VERSION ""

NS_ :

BS_:
BU_: Receiver ChassisBus VehicleBus PartyBus apb ui app aps bms gtwu odin cc cmp cp das dif dir di epas3p epas3s epbl epbr esp fc gtw hvp ibst ocs1p park pcs pmf pmr pm ptc radc rcm2 rcm sccm scm scs tas tpms umc vcfront vcleft vcright vcsec GTW

BO_ 800 ID320BMS_alertMatrix: 8 VehicleBus
   SG_ BMS_matrixIndex M : 0|4@1+ (1,0) [0|15] "" Receiver
   SG_ BMS_a001_Pack_Config_Mismatch m0 : 4|1@1+ (1,0) [0|1] "" Receiver
   SG_ BMS_a007_SW_Slowed_Chg_Batt_Cold m0 : 10|1@1+ (1,0) [0|1] "" Receiver
   SG_ BMS_a016_Pack_Module_Id_Mismatch m0 : 19|1@1+ (1,0) [0|1] "" Receiver
   SG_ BMS_a017_SW_Brick_OV m0 : 20|1@1+ (1,0) [0|1] "" Receiver
   SG_ BMS_a018_SW_Brick_UV m0 : 21|1@1+ (1,0) [0|1] "" Receiver
   SG_ BMS_a019_SW_Module_OT m0 : 22|1@1+ (1,0) [0|1] "" Receiver
   SG_ BMS_a021_SW_Dr_Limits_Regulation m0 : 24|1@1+ (1,0) [0|1] "" Receiver
   SG_ BMS_a022_SW_Over_Current m0 : 25|1@1+ (1,0) [0|1] "" Receiver
   SG_ BMS_a023_SW_Stack_OV m0 : 26|1@1+ (1,0) [0|1] "" Receiver
   SG_ BMS_a024_SW_Islanded_Brick m0 : 27|1@1+ (1,0) [0|1] "" Receiver
   SG_ BMS_a025_SW_PwrBalance_Anomaly m0 : 28|1@1+ (1,0) [0|1] "" Receiver
   SG_ BMS_a026_SW_HFCurrent_Anomaly m0 : 29|1@1+ (1,0) [0|1] "" Receiver
   SG_ BMS_a034_SW_Passive_Isolation m0 : 37|1@1+ (1,0) [0|1] "" Receiver
   SG_ BMS_a035_SW_Isolation m0 : 38|1@1+ (1,0) [0|1] "" Receiver
   SG_ BMS_a036_SW_HvpHvilFault m0 : 39|1@1+ (1,0) [0|1] "" Receiver
   SG_ BMS_a037_SW_Flood_Port_Open m0 : 40|1@1+ (1,0) [0|1] "" Receiver
   SG_ BMS_a039_SW_DC_Link_Over_Voltage m0 : 42|1@1+ (1,0) [0|1] "" Receiver
   SG_ BMS_a040_SW_Watch_Dog_HW_Trigger m0 : 43|1@1+ (1,0) [0|1] "" Receiver
   SG_ BMS_a041_SW_Destructive_Reset_So m0 : 44|1@1+ (1,0) [0|1] "" Receiver
   SG_ BMS_a042_SW_MPU_Error m0 : 45|1@1+ (1,0) [0|1] "" Receiver
   SG_ BMS_a043_SW_Watch_Dog_Reset m0 : 46|1@1+ (1,0) [0|1] "" Receiver
   SG_ BMS_a044_SW_Assertion m0 : 47|1@1+ (1,0) [0|1] "" Receiver
   SG_ BMS_a045_SW_Exception m0 : 48|1@1+ (1,0) [0|1] "" Receiver
   SG_ BMS_a046_SW_Task_Stack_Usage m0 : 49|1@1+ (1,0) [0|1] "" Receiver
   SG_ BMS_a047_SW_Task_Stack_Overflow m0 : 50|1@1+ (1,0) [0|1] "" Receiver
   SG_ BMS_a048_SW_Log_Upload_Request m0 : 51|1@1+ (1,0) [0|1] "" Receiver
   SG_ BMS_a050_SW_Brick_Voltage_MIA m0 : 53|1@1+ (1,0) [0|1] "" Receiver
   SG_ BMS_a051_SW_HVC_Vref_Bad m0 : 54|1@1+ (1,0) [0|1] "" Receiver
   SG_ BMS_a052_SW_PCS_MIA m0 : 55|1@1+ (1,0) [0|1] "" Receiver
   SG_ BMS_a054_SW_Ver_Supply_Fault m0 : 57|1@1+ (1,0) [0|1] "" Receiver
   SG_ BMS_a055_SW_HvChain_Model_Fault m0 : 58|1@1+ (1,0) [0|1] "" Receiver
   SG_ BMS_a056_SW_Standby_Supply_Fault m0 : 59|1@1+ (1,0) [0|1] "" Receiver
   SG_ BMS_a057_SW_Bandolier_Model_Warn m0 : 60|1@1+ (1,0) [0|1] "" Receiver
   SG_ BMS_a058_SW_Bandolier_Model_Rese m0 : 61|1@1+ (1,0) [0|1] "" Receiver
   SG_ BMS_a059_SW_Pack_Voltage_Sensing m0 : 62|1@1+ (1,0) [0|1] "" Receiver
   SG_ BMS_a060_SW_Leakage_Test_Failure m0 : 63|1@1+ (1,0) [0|1] "" Receiver
   SG_ BMS_a061_SW_BrickV_Change m1 : 4|1@1+ (1,0) [0|1] "" Receiver
   SG_ BMS_a062_SW_BrickV_Imbalance m1 : 5|1@1+ (1,0) [0|1] "" Receiver
   SG_ BMS_a063_SW_ChargePort_Fault m1 : 6|1@1+ (1,0) [0|1] "" Receiver
   SG_ BMS_a064_SW_SOC_Imbalance m1 : 7|1@1+ (1,0) [0|1] "" Receiver
   SG_ BMS_a065_SW_CAC_Imbalance m1 : 8|1@1+ (1,0) [0|1] "" Receiver
   SG_ BMS_a069_SW_Low_Power m1 : 12|1@1+ (1,0) [0|1] "" Receiver
   SG_ BMS_a071_SW_SM_TransCon_Not_Met m1 : 14|1@1+ (1,0) [0|1] "" Receiver
   SG_ BMS_a075_SW_Chg_Disable_Failure m1 : 18|1@1+ (1,0) [0|1] "" Receiver
   SG_ BMS_a076_SW_Dch_While_Charging m1 : 19|1@1+ (1,0) [0|1] "" Receiver
   SG_ BMS_a077_SW_Charger_Regulation m1 : 20|1@1+ (1,0) [0|1] "" Receiver
   SG_ BMS_a080_SW_Pack_Ctr_Impedance m1 : 23|1@1+ (1,0) [0|1] "" Receiver
   SG_ BMS_a081_SW_Ctr_Close_Blocked m1 : 24|1@1+ (1,0) [0|1] "" Receiver
   SG_ BMS_a082_SW_Ctr_Force_Open m1 : 25|1@1+ (1,0) [0|1] "" Receiver
   SG_ BMS_a083_SW_Ctr_Close_Failure m1 : 26|1@1+ (1,0) [0|1] "" Receiver
   SG_ BMS_a084_SW_Sleep_Wake_Aborted m1 : 27|1@1+ (1,0) [0|1] "" Receiver
   SG_ BMS_a087_SW_Feim_Test_Blocked m1 : 30|1@1+ (1,0) [0|1] "" Receiver
   SG_ BMS_a088_SW_VcFront_MIA_InDrive m1 : 31|1@1+ (1,0) [0|1] "" Receiver
   SG_ BMS_a089_SW_VcFront_MIA m1 : 32|1@1+ (1,0) [0|1] "" Receiver
   SG_ BMS_a090_SW_Gateway_MIA m1 : 33|1@1+ (1,0) [0|1] "" Receiver
   SG_ BMS_a091_SW_ChargePort_MIA m1 : 34|1@1+ (1,0) [0|1] "" Receiver
   SG_ BMS_a092_SW_ChargePort_Mia_On_Hv m1 : 35|1@1+ (1,0) [0|1] "" Receiver
   SG_ BMS_a094_SW_Drive_Inverter_MIA m1 : 37|1@1+ (1,0) [0|1] "" Receiver
   SG_ BMS_a098_SW_BMB_Data_Integrity_L m1 : 41|1@1+ (1,0) [0|1] "" Receiver
   SG_ BMS_a099_SW_BMB_Communication m1 : 42|1@1+ (1,0) [0|1] "" Receiver
   SG_ BMS_a105_SW_One_Module_Tsense m1 : 48|1@1+ (1,0) [0|1] "" Receiver
   SG_ BMS_a106_SW_All_Module_Tsense m1 : 49|1@1+ (1,0) [0|1] "" Receiver
   SG_ BMS_a107_SW_Stack_Voltage_MIA m1 : 50|1@1+ (1,0) [0|1] "" Receiver
   SG_ BMS_a121_SW_NVRAM_Config_Error m2 : 4|1@1+ (1,0) [0|1] "" Receiver
   SG_ BMS_a122_SW_BMS_Therm_Irrational m2 : 5|1@1+ (1,0) [0|1] "" Receiver
   SG_ BMS_a123_SW_Internal_Isolation m2 : 6|1@1+ (1,0) [0|1] "" Receiver
   SG_ BMS_a126_SW_Thermistor_Failure m2 : 9|1@1+ (1,0) [0|1] "" Receiver
   SG_ BMS_a127_SW_shunt_SNA m2 : 10|1@1+ (1,0) [0|1] "" Receiver
   SG_ BMS_a128_SW_shunt_MIA m2 : 11|1@1+ (1,0) [0|1] "" Receiver
   SG_ BMS_a129_SW_VSH_Failure m2 : 12|1@1+ (1,0) [0|1] "" Receiver
   SG_ BMS_a130_IO_CAN_Error m2 : 13|1@1+ (1,0) [0|1] "" Receiver
   SG_ BMS_a131_Bleed_FET_Failure m2 : 14|1@1+ (1,0) [0|1] "" Receiver
   SG_ BMS_a132_HW_BMB_OTP_Uncorrctbl m2 : 15|1@1+ (1,0) [0|1] "" Receiver
   SG_ BMS_a134_SW_Delayed_Ctr_Off m2 : 17|1@1+ (1,0) [0|1] "" Receiver
   SG_ BMS_a135_HW_BMB_Diagnostics_Fail m2 : 18|1@1+ (1,0) [0|1] "" Receiver
   SG_ BMS_a136_SW_Module_OT_Warning m2 : 19|1@1+ (1,0) [0|1] "" Receiver
   SG_ BMS_a137_SW_Brick_UV_Warning m2 : 20|1@1+ (1,0) [0|1] "" Receiver
   SG_ BMS_a138_SW_Brick_OV_Warning m2 : 21|1@1+ (1,0) [0|1] "" Receiver
   SG_ BMS_a139_SW_DC_Link_V_Irrational m2 : 22|1@1+ (1,0) [0|1] "" Receiver
   SG_ BMS_a141_SW_BMB_Status_Warning m2 : 24|1@1+ (1,0) [0|1] "" Receiver
   SG_ BMS_a143_SW_CAC_Change m2 : 26|1@1+ (1,0) [0|1] "" Receiver
   SG_ BMS_a144_Hvp_Config_Mismatch m2 : 27|1@1+ (1,0) [0|1] "" Receiver
   SG_ BMS_a145_SW_SOC_Change m2 : 28|1@1+ (1,0) [0|1] "" Receiver
   SG_ BMS_a146_SW_Brick_Overdischarged m2 : 29|1@1+ (1,0) [0|1] "" Receiver
   SG_ BMS_a149_SW_Missing_Config_Block m2 : 32|1@1+ (1,0) [0|1] "" Receiver
   SG_ BMS_a151_SW_external_isolation m2 : 34|1@1+ (1,0) [0|1] "" Receiver
   SG_ BMS_a155_SW_Weak_short_impedence m2 : 38|1@1+ (1,0) [0|1] "" Receiver
   SG_ BMS_a156_SW_BMB_Vref_bad m2 : 39|1@1+ (1,0) [0|1] "" Receiver
   SG_ BMS_a158_SW_HVP_HVI_Comms m2 : 41|1@1+ (1,0) [0|1] "" Receiver
   SG_ BMS_a159_SW_HVP_ECU_Error m2 : 42|1@1+ (1,0) [0|1] "" Receiver
   SG_ BMS_a160_SW_FC_Ctr_Clean_Failed m2 : 43|1@1+ (1,0) [0|1] "" Receiver
   SG_ BMS_a161_SW_DI_Open_Request m2 : 44|1@1+ (1,0) [0|1] "" Receiver
   SG_ BMS_a162_SW_No_Power_For_Support m2 : 45|1@1+ (1,0) [0|1] "" Receiver
   SG_ BMS_a163_SW_Contactor_Mismatch m2 : 46|1@1+ (1,0) [0|1] "" Receiver
   SG_ BMS_a164_SW_Uncontrolled_Regen m2 : 47|1@1+ (1,0) [0|1] "" Receiver
   SG_ BMS_a165_SW_Pack_Partial_Weld m2 : 48|1@1+ (1,0) [0|1] "" Receiver
   SG_ BMS_a166_SW_Pack_Full_Weld m2 : 49|1@1+ (1,0) [0|1] "" Receiver
   SG_ BMS_a167_SW_FC_Partial_Weld m2 : 50|1@1+ (1,0) [0|1] "" Receiver
   SG_ BMS_a168_SW_FC_Full_Weld m2 : 51|1@1+ (1,0) [0|1] "" Receiver
   SG_ BMS_a169_SW_FC_Pack_Weld m2 : 52|1@1+ (1,0) [0|1] "" Receiver
   SG_ BMS_a170_SW_Limp_Mode m2 : 53|1@1+ (1,0) [0|1] "" Receiver
   SG_ BMS_a171_SW_Stack_Voltage_Sense m2 : 54|1@1+ (1,0) [0|1] "" Receiver
   SG_ BMS_a174_SW_Charge_Failure m2 : 57|1@1+ (1,0) [0|1] "" Receiver
   SG_ BMS_a176_SW_GracefulPowerOff m2 : 59|1@1+ (1,0) [0|1] "" Receiver
   SG_ BMS_a178_SW_Uncontrolled_Regen_P m2 : 61|1@1+ (1,0) [0|1] "" Receiver
   SG_ BMS_a179_SW_Hvp_12V_Fault m2 : 62|1@1+ (1,0) [0|1] "" Receiver
   SG_ BMS_a180_SW_ECU_reset_blocked m2 : 63|1@1+ (1,0) [0|1] "" Receiver

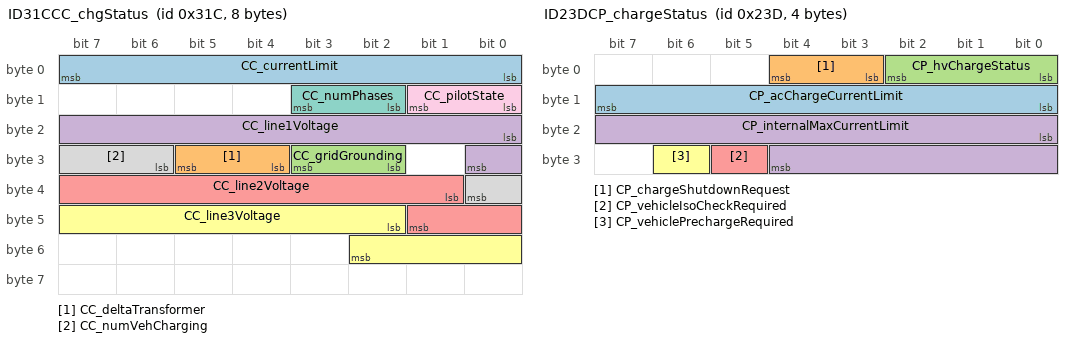
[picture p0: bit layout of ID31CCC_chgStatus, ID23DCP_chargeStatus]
BO_ 796 ID31CCC_chgStatus: 8 VehicleBus
   SG_ CC_currentLimit : 0|8@1+ (0.5,0) [0|127.5] "A" Receiver
   SG_ CC_deltaTransformer : 28|2@1+ (1,0) [0|3] "" Receiver
   SG_ CC_gridGrounding : 26|2@1+ (1,0) [0|2] "" Receiver
   SG_ CC_line1Voltage : 16|9@1+ (1,0) [0|511] "V" Receiver
   SG_ CC_line2Voltage : 33|9@1+ (1,0) [0|511] "V" Receiver
   SG_ CC_line3Voltage : 42|9@1+ (1,0) [0|511] "V" Receiver
   SG_ CC_numPhases : 10|2@1+ (1,0) [0|3] "" Receiver
   SG_ CC_numVehCharging : 30|3@1+ (1,0) [0|7] "" Receiver
   SG_ CC_pilotState : 8|2@1+ (1,0) [0|3] "" Receiver

BO_ 797 ID31DCC_chgStatus2: 8 VehicleBus
   SG_ CC_chgStatus2Index M : 0|8@1+ (1,0) [0|0] "" Receiver
   SG_ CC_buttonState m0 : 8|1@1+ (1,0) [0|1] "" Receiver

BO_ 812 ID32CCC_logData: 8 VehicleBus
   SG_ CC_logIndex M : 0|8@1+ (1,0) [0|13] "" Receiver
   SG_ CC_activeConnectorID m0 : 8|8@1+ (1,0) [0|255] "" Receiver
   SG_ CC_conn1Current m1 : 8|8@1+ (0.5,0) [0|127.5] "A" Receiver
   SG_ CC_conn2Current m2 : 8|8@1+ (0.5,0) [0|127.5] "A" Receiver
   SG_ CC_conn3Current m3 : 8|8@1+ (0.5,0) [0|127.5] "A" Receiver
   SG_ CC_conn4Current m4 : 8|8@1+ (0.5,0) [0|127.5] "A" Receiver
   SG_ CC_contactor1Closed m0 : 40|2@1+ (1,0) [0|3] "" Receiver
   SG_ CC_contactor2Closed m0 : 42|2@1+ (1,0) [0|3] "" Receiver
   SG_ CC_lifetimeAlertCount m12 : 8|28@1+ (1,0) [0|2.68435e+08] "" Receiver
   SG_ CC_lifetimeAvgStartupTemp m13 : 36|28@1- (0.1,0) [-1.34218e+07|1.34218e+07] "C" Receiver
   SG_ CC_lifetimeCtrCycles m11 : 8|28@1+ (1,0) [0|2.68435e+08] "" Receiver
   SG_ CC_lifetimeCtrCyclesLoaded m11 : 36|28@1+ (1,0) [0|2.68435e+08] "" Receiver
   SG_ CC_lifetimeThermalFoldbacks m12 : 36|28@1+ (1,0) [0|2.68435e+08] "" Receiver
   SG_ CC_lifetimei2t m10 : 32|32@1+ (0.1,0) [0|4.29497e+08] "A2h" Receiver
   SG_ CC_temperature1 m0 : 16|8@1- (1,88) [-40|215] "C" Receiver
   SG_ CC_temperature2 m0 : 24|8@1- (1,88) [-40|215] "C" Receiver
   SG_ CC_temperature3 m0 : 32|8@1- (1,88) [-40|215] "C" Receiver
   SG_ CC_temperature4 m0 : 44|8@1- (1,88) [-40|215] "C" Receiver

BO_ 573 ID23DCP_chargeStatus: 4 VehicleBus
   SG_ CP_acChargeCurrentLimit : 8|8@1+ (0.5,0) [0|127.5] "A" Receiver
   SG_ CP_chargeShutdownRequest : 3|2@1+ (1,0) [0|2] "" Receiver
   SG_ CP_hvChargeStatus : 0|3@1+ (1,0) [0|6] "" Receiver
   SG_ CP_internalMaxCurrentLimit : 16|13@1+ (0.146502,0) [0|1200] "A" Receiver
   SG_ CP_vehicleIsoCheckRequired : 29|1@1+ (1,0) [0|1] "" Receiver
   SG_ CP_vehiclePrechargeRequired : 30|1@1+ (1,0) [0|1] "" Receiver

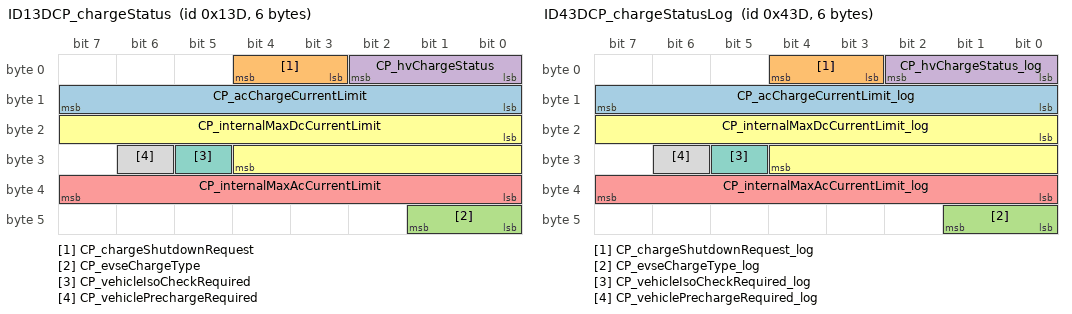
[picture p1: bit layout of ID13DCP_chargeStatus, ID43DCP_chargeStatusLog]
BO_ 317 ID13DCP_chargeStatus: 6 VehicleBus
   SG_ CP_acChargeCurrentLimit : 8|8@1+ (0.5,0) [0|127.5] "A" Receiver
   SG_ CP_chargeShutdownRequest : 3|2@1+ (1,0) [0|2] "" Receiver
   SG_ CP_evseChargeType : 40|2@1+ (1,0) [0|2] "" Receiver
   SG_ CP_hvChargeStatus : 0|3@1+ (1,0) [0|6] "" Receiver
   SG_ CP_internalMaxAcCurrentLimit : 32|8@1+ (0.5,0) [0|127.5] "A" Receiver
   SG_ CP_internalMaxDcCurrentLimit : 16|13@1+ (0.146502,0) [0|1200] "A" Receiver
   SG_ CP_vehicleIsoCheckRequired : 29|1@1+ (1,0) [0|1] "" Receiver
   SG_ CP_vehiclePrechargeRequired : 30|1@1+ (1,0) [0|1] "" Receiver

BO_ 1085 ID43DCP_chargeStatusLog: 6 VehicleBus
   SG_ CP_acChargeCurrentLimit_log : 8|8@1+ (0.5,0) [0|127.5] "A" Receiver
   SG_ CP_chargeShutdownRequest_log : 3|2@1+ (1,0) [0|2] "" Receiver
   SG_ CP_evseChargeType_log : 40|2@1+ (1,0) [0|2] "" Receiver
   SG_ CP_hvChargeStatus_log : 0|3@1+ (1,0) [0|6] "" Receiver
   SG_ CP_internalMaxAcCurrentLimit_log : 32|8@1+ (0.5,0) [0|127.5] "A" Receiver
   SG_ CP_internalMaxDcCurrentLimit_log : 16|13@1+ (0.146502,0) [0|1200] "A" Receiver
   SG_ CP_vehicleIsoCheckRequired_log : 29|1@1+ (1,0) [0|1] "" Receiver
   SG_ CP_vehiclePrechargeRequired_log : 30|1@1+ (1,0) [0|1] "" Receiver

BO_ 541 ID21DCP_evseStatus: 8 VehicleBus
   SG_ CP_acChargeState : 53|3@1+ (1,0) [0|6] "" Receiver
   SG_ CP_acNumRetries : 40|2@1+ (1,0) [0|3] "" Receiver
   SG_ CP_cableCurrentLimit : 24|7@1+ (1,0) [0|127] "A" Receiver
   SG_ CP_cableType : 16|3@1+ (1,0) [0|4] "" Receiver
   SG_ CP_digitalCommsAttempts : 32|2@1+ (1,0) [0|3] "" Receiver
   SG_ CP_digitalCommsEstablished : 37|1@1+ (1,0) [0|1] "" Receiver
   SG_ CP_evseAccept : 0|1@1+ (1,0) [0|1] "" Receiver
   SG_ CP_evseChargeType_UI : 38|2@1+ (1,0) [0|2] "" Receiver
   SG_ CP_evseRequest : 1|1@1+ (1,0) [0|1] "" Receiver
   SG_ CP_gbState : 42|4@1+ (1,0) [0|15] "" Receiver
   SG_ CP_gbdcChargeAttempts : 51|2@1+ (1,0) [0|3] "" Receiver
   SG_ CP_gbdcFailureReason : 49|2@1+ (1,0) [0|3] "" Receiver
   SG_ CP_gbdcStopChargeReason : 46|3@1+ (1,0) [0|7] "" Receiver
   SG_ CP_iecComboState : 60|4@1+ (1,0) [0|12] "" Receiver
   SG_ CP_pilot : 4|3@1+ (1,0) [0|7] "" Receiver
   SG_ CP_pilotCurrent : 8|8@1+ (0.5,0) [0|127.5] "A" Receiver
   SG_ CP_proximity : 2|2@1+ (1,0) [0|3] "" Receiver
   SG_ CP_teslaDcState : 56|4@1+ (1,0) [0|10] "" Receiver
   SG_ CP_teslaSwcanState : 34|3@1+ (1,0) [0|6] "" Receiver

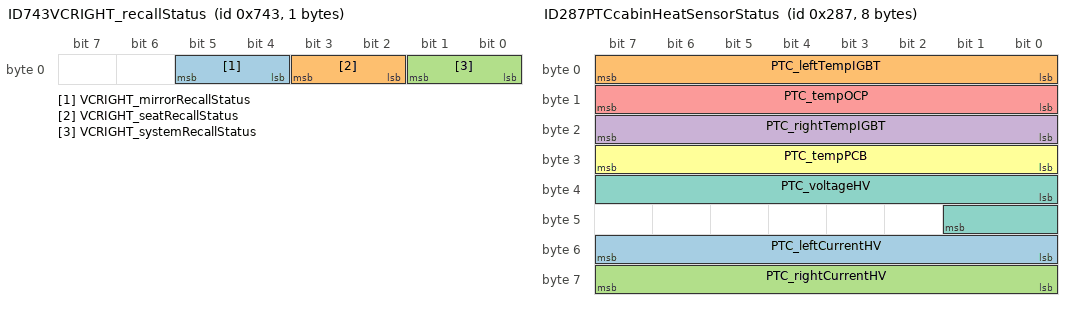
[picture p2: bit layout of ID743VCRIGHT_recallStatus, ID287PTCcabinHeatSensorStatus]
BO_ 1859 ID743VCRIGHT_recallStatus: 1 VehicleBus
   SG_ VCRIGHT_mirrorRecallStatus : 4|2@1+ (1,0) [0|3] "" Receiver
   SG_ VCRIGHT_seatRecallStatus : 2|2@1+ (1,0) [0|3] "" Receiver
   SG_ VCRIGHT_systemRecallStatus : 0|2@1+ (1,0) [0|3] "" Receiver

BO_ 1885 ID75DCP_sensorData: 8 VehicleBus
   SG_ CP_sensorDataSelect M : 0|4@1+ (1,0) [0|12] "" Receiver
   SG_ CP_UHF_chipState m6 : 4|3@1+ (1,0) [0|7] "" Receiver
   SG_ CP_UHF_fifoData m6 : 32|8@1+ (1,0) [0|255] "" Receiver
   SG_ CP_UHF_rssi m6 : 8|8@1+ (1,0) [0|255] "" Receiver
   SG_ CP_UHF_rxNumBytes m6 : 24|8@1+ (1,0) [0|255] "" Receiver
   SG_ CP_UHF_rxOverflow m6 : 16|1@1+ (1,0) [0|1] "" Receiver
   SG_ CP_UHF_selfTestRssi m6 : 40|8@1+ (1,0) [0|255] "" Receiver
   SG_ CP_backCover2Counts m5 : 32|16@1+ (0.0015259,0) [0|100] "%" Receiver
   SG_ CP_backCoverCounts m5 : 16|16@1+ (0.0015259,0) [0|100] "%" Receiver
   SG_ CP_boardTemperature m1 : 32|8@1+ (1.29412,-50) [-50|280] "C" Receiver
   SG_ CP_doorCountsDebounced m0 : 24|16@1+ (0.0015259,0) [0|100] "%" Receiver
   SG_ CP_doorCountsFiltered m0 : 8|16@1+ (0.0015259,0) [0|100] "%" Receiver
   SG_ CP_doorI m2 : 16|12@1+ (0.0025,0) [0|10.2375] "A" Receiver
   SG_ CP_doorLastRequestMaxI m2 : 28|12@1+ (0.0025,0) [0|10.2375] "A" Receiver
   SG_ CP_doorPot m2 : 4|12@1+ (0.025,0) [0|100] "%" Receiver
   SG_ CP_faultLineV m5 : 4|12@1+ (0.00114,0) [0|4.65524] "V" Receiver
   SG_ CP_inductiveSensor_raw m4 : 4|28@1+ (1,0) [0|2.68435e+08] "" Receiver
   SG_ CP_inlet1HarnessIdState m12 : 4|2@1+ (1,0) [0|2] "" Receiver
   SG_ CP_inlet1HarnessIdValue m12 : 8|3@1+ (1,0) [0|7] "" Receiver
   SG_ CP_inlet1HarnessV m12 : 16|14@1+ (0.001,0) [0|13.3] "V" Receiver
   SG_ CP_inlet2HarnessIdState m12 : 30|2@1+ (1,0) [0|2] "" Receiver
   SG_ CP_inlet2HarnessIdValue m12 : 32|3@1+ (1,0) [0|7] "" Receiver
   SG_ CP_inlet2HarnessV m12 : 40|14@1+ (0.001,0) [0|13.3] "V" Receiver
   SG_ CP_latch2I m3 : 16|12@1+ (0.0025,0) [0|10.2375] "A" Receiver
   SG_ CP_latchI m3 : 4|12@1+ (0.0025,0) [0|10.2375] "A" Receiver
   SG_ CP_pilotHighValue m9 : 40|12@1- (0.01,0) [-20.48|20.47] "V" Receiver
   SG_ CP_pilotHighValue_intervalMax10s m10 : 28|12@1- (0.01,0) [-20.48|20.47] "V" Receiver
   SG_ CP_pilotHighValue_intervalMin10s m10 : 40|12@1- (0.01,0) [-20.48|20.47] "V" Receiver
   SG_ CP_pilotLowValue m9 : 28|12@1- (0.01,0) [-20.48|20.47] "V" Receiver
   SG_ CP_pilotLowValue_intervalMax10s m10 : 4|12@1- (0.01,0) [-20.48|20.47] "V" Receiver
   SG_ CP_pilotLowValue_intervalMin10s m10 : 16|12@1- (0.01,0) [-20.48|20.47] "V" Receiver
   SG_ CP_pilotPeriod m9 : 16|12@1+ (1,0) [0|4095] "" Receiver
   SG_ CP_pilotPulseWidth m9 : 4|12@1+ (1,0) [0|4095] "" Receiver
   SG_ CP_pinTemperature1 m1 : 8|8@1+ (0.803922,-55) [-55|149.99] "C" Receiver
   SG_ CP_pinTemperature2 m1 : 16|8@1+ (0.803922,-55) [-55|149.99] "C" Receiver
   SG_ CP_pinTemperature3 m1 : 24|8@1+ (0.803922,-55) [-55|149.99] "C" Receiver
   SG_ CP_proxConn1Sense m8 : 56|1@1+ (1,0) [0|1] "" Receiver
   SG_ CP_proxEn m8 : 57|1@1+ (1,0) [0|1] "" Receiver
   SG_ CP_proximityV m8 : 8|16@1+ (0.0001,0) [0|6.5535] "V" Receiver
   SG_ CP_proximityV_GBCC1 m11 : 8|14@1+ (0.001,0) [0|13.3] "V" Receiver
   SG_ CP_proximityV_GBCC2 m11 : 24|14@1+ (0.001,0) [0|13.3] "V" Receiver
   SG_ CP_proximityV_intervalMax10s m8 : 40|16@1+ (0.0001,0) [0|6.5535] "V" Receiver
   SG_ CP_proximityV_intervalMin10s m8 : 24|16@1+ (0.0001,0) [0|6.5535] "V" Receiver
   SG_ CP_refVoltage m7 : 8|8@1+ (0.00705882,0) [0|1.8] "V" Receiver

BO_ 1962 ID7AAHVP_debugMessage: 8 VehicleBus
   SG_ HVP_debugMessageMultiplexer M : 0|4@1+ (1,0) [0|6] "" Receiver
   SG_ HVP_auxCurrentMia m0 : 57|1@1+ (1,0) [0|1] "" Receiver
   SG_ HVP_battery12V m5 : 36|12@1+ (0.1,0) [0|30] "V" Receiver
   SG_ HVP_currentSenseMia m0 : 58|1@1+ (1,0) [0|1] "" Receiver
   SG_ HVP_dcLinkNegativeV m3 : 8|16@1- (0.1,0) [-550|550] "V" Receiver
   SG_ HVP_dcLinkPositiveV m3 : 24|16@1- (0.1,0) [-550|550] "V" Receiver
   SG_ HVP_dcLinkVoltage m1 : 8|16@1- (0.1,0) [-3276.8|3276.7] "V" Receiver
   SG_ HVP_fcContCoilCurrent m4 : 4|12@1+ (0.1,0) [0|7.5] "A" Receiver
   SG_ HVP_fcContVoltage m4 : 16|12@1+ (0.1,0) [0|30] "V" Receiver
   SG_ HVP_fcLinkNegativeV m3 : 40|16@1- (0.1,0) [-550|550] "V" Receiver
   SG_ HVP_fcLinkPositiveV m5 : 8|16@1- (0.1,0) [-550|550] "V" Receiver
   SG_ HVP_fcLinkVoltage m1 : 40|16@1- (0.1,0) [-3276.8|3276.7] "V" Receiver
   SG_ HVP_gpioBmsEout m0 : 15|1@1+ (1,0) [0|1] "" Receiver
   SG_ HVP_gpioCpFaultIn m0 : 6|1@1+ (1,0) [0|1] "" Receiver
   SG_ HVP_gpioCpFaultOut m0 : 16|1@1+ (1,0) [0|1] "" Receiver
   SG_ HVP_gpioCpLatchEnable m0 : 21|1@1+ (1,0) [0|1] "" Receiver
   SG_ HVP_gpioCrashSignal m0 : 11|1@1+ (1,0) [0|1] "" Receiver
   SG_ HVP_gpioFcContNegAux m0 : 14|1@1+ (1,0) [0|1] "" Receiver
   SG_ HVP_gpioFcContPosAux m0 : 13|1@1+ (1,0) [0|1] "" Receiver
   SG_ HVP_gpioFcContPowerEnable m0 : 25|1@1+ (1,0) [0|1] "" Receiver
   SG_ HVP_gpioHvCablesOk m0 : 8|1@1+ (1,0) [0|1] "" Receiver
   SG_ HVP_gpioHvilEnable m0 : 26|1@1+ (1,0) [0|1] "" Receiver
   SG_ HVP_gpioHvpSelfEnable m0 : 9|1@1+ (1,0) [0|1] "" Receiver
   SG_ HVP_gpioHvpVerEn m0 : 19|1@1+ (1,0) [0|1] "" Receiver
   SG_ HVP_gpioLed m0 : 10|1@1+ (1,0) [0|1] "" Receiver
   SG_ HVP_gpioPackContPowerEn m0 : 7|1@1+ (1,0) [0|1] "" Receiver
   SG_ HVP_gpioPackCoontPosFlywheel m0 : 20|1@1+ (1,0) [0|1] "" Receiver
   SG_ HVP_gpioPassivePyroDepl m0 : 4|1@1+ (1,0) [0|1] "" Receiver
   SG_ HVP_gpioPcsChargePwmEnable m0 : 24|1@1+ (1,0) [0|1] "" Receiver
   SG_ HVP_gpioPcsDcdcPwmEnable m0 : 23|1@1+ (1,0) [0|1] "" Receiver
   SG_ HVP_gpioPcsEnable m0 : 22|1@1+ (1,0) [0|1] "" Receiver
   SG_ HVP_gpioPyroIsoEn m0 : 5|1@1+ (1,0) [0|1] "" Receiver
   SG_ HVP_gpioPyroPor m0 : 17|1@1+ (1,0) [0|1] "" Receiver
   SG_ HVP_gpioSecDrdy m0 : 27|1@1+ (1,0) [0|1] "" Receiver
   SG_ HVP_gpioShuntDataReady m0 : 12|1@1+ (1,0) [0|1] "" Receiver
   SG_ HVP_gpioShuntEn m0 : 18|1@1+ (1,0) [0|1] "" Receiver
   SG_ HVP_hvilInVoltage m4 : 28|12@1+ (0.1,0) [0|30] "V" Receiver
   SG_ HVP_hvilOutVoltage m4 : 40|12@1+ (0.1,0) [0|30] "V" Receiver
   SG_ HVP_hvp1v5Ref m0 : 28|12@1+ (0.1,0) [0|3] "V" Receiver
   SG_ HVP_packContCoilCurrent m5 : 24|12@1+ (0.1,0) [0|7.5] "A" Receiver
   SG_ HVP_packContVoltage m2 : 4|12@1+ (0.1,0) [0|30] "V" Receiver
   SG_ HVP_packCurrentMia m0 : 56|1@1+ (1,0) [0|1] "" Receiver
   SG_ HVP_packNegativeV m2 : 16|16@1- (0.1,0) [-550|550] "V" Receiver
   SG_ HVP_packPositiveV m2 : 32|16@1- (0.1,0) [-550|550] "V" Receiver
   SG_ HVP_packVoltage m1 : 24|16@1- (0.1,0) [-3276.8|3276.7] "V" Receiver
   SG_ HVP_pyroAnalog m2 : 48|12@1+ (0.1,0) [0|3] "V" Receiver
   SG_ HVP_shuntAsicTempDbg m6 : 40|16@1- (0.01,0) [-327.67|327.67] "C" Receiver
   SG_ HVP_shuntAsicTempStatus m6 : 60|2@1+ (1,0) [0|3] "" Receiver
   SG_ HVP_shuntAuxCurrentDbg m6 : 8|16@1- (0.1,0) [-3276.8|3276.7] "A" Receiver
   SG_ HVP_shuntAuxCurrentStatus m6 : 56|2@1+ (1,0) [0|3] "" Receiver
   SG_ HVP_shuntBarTempDbg m6 : 24|16@1- (0.01,0) [-327.67|327.67] "C" Receiver
   SG_ HVP_shuntBarTempStatus m6 : 58|2@1+ (1,0) [0|3] "" Receiver
   SG_ HVP_shuntCurrentDebug m0 : 40|16@1- (0.1,0) [-3276.8|3276.7] "A" Receiver
   SG_ HVP_shuntHwMia m0 : 61|1@1+ (1,0) [0|1] "" Receiver
   SG_ HVP_shuntRefVoltageDbg m5 : 48|16@1- (0.001,0) [-32.768|32.767] "V" Receiver
   SG_ HVP_shuntRefVoltageMismatch m0 : 59|1@1+ (1,0) [0|1] "" Receiver
   SG_ HVP_shuntThermistorMia m0 : 60|1@1+ (1,0) [0|1] "" Receiver

BO_ 647 ID287PTCcabinHeatSensorStatus: 8 VehicleBus
   SG_ PTC_leftCurrentHV : 48|8@1+ (0.2,0) [0|50] "A" Receiver
   SG_ PTC_leftTempIGBT : 0|8@1+ (1,-40) [-40|200] "C" Receiver
   SG_ PTC_rightCurrentHV : 56|8@1+ (0.2,0) [0|50] "A" Receiver
   SG_ PTC_rightTempIGBT : 16|8@1+ (1,-40) [-40|200] "C" Receiver
   SG_ PTC_tempOCP : 8|8@1+ (1,-40) [-40|200] "C" Receiver
   SG_ PTC_tempPCB : 24|8@1+ (1,-40) [-40|200] "C" Receiver
   SG_ PTC_voltageHV : 32|10@1+ (0.5,0) [0|511.5] "V" Receiver

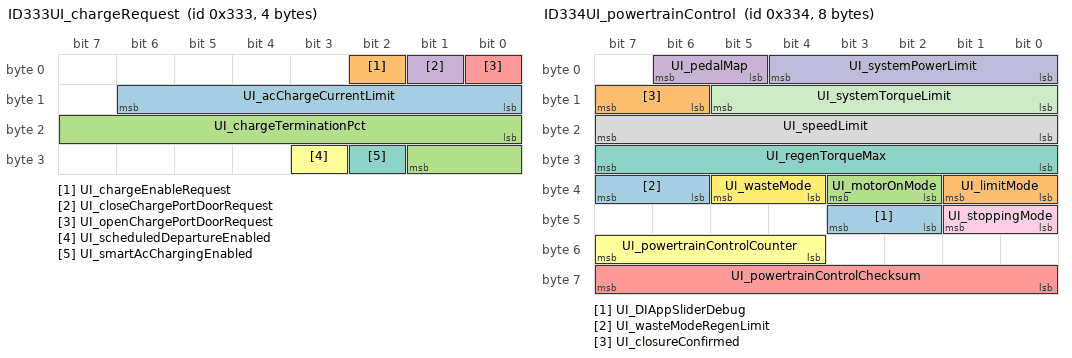
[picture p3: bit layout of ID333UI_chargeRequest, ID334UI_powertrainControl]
BO_ 819 ID333UI_chargeRequest: 4 VehicleBus
   SG_ UI_acChargeCurrentLimit : 8|7@1+ (1,0) [0|127] "A" Receiver
   SG_ UI_chargeEnableRequest : 2|1@1+ (1,0) [0|1] "" Receiver
   SG_ UI_chargeTerminationPct : 16|10@1+ (0.1,0) [25|100] "%" Receiver
   SG_ UI_closeChargePortDoorRequest : 1|1@1+ (1,0) [0|1] "" Receiver
   SG_ UI_openChargePortDoorRequest : 0|1@1+ (1,0) [0|1] "" Receiver
   SG_ UI_scheduledDepartureEnabled : 27|1@1+ (1,0) [0|1] "" Receiver
   SG_ UI_smartAcChargingEnabled : 26|1@1+ (1,0) [0|1] "" Receiver

BO_ 820 ID334UI_powertrainControl: 8 VehicleBus
   SG_ UI_DIAppSliderDebug : 42|2@1+ (1,0) [0|3] "" Receiver
   SG_ UI_limitMode : 32|2@1+ (1,0) [0|3] "" Receiver
   SG_ UI_motorOnMode : 34|2@1+ (1,0) [0|2] "" Receiver
   SG_ UI_pedalMap : 5|2@1+ (1,0) [0|2] "" Receiver
   SG_ UI_powertrainControlChecksum : 56|8@1+ (1,0) [0|255] "" Receiver
   SG_ UI_powertrainControlCounter : 52|4@1+ (1,0) [0|15] "" Receiver
   SG_ UI_regenTorqueMax : 24|8@1+ (0.5,0) [0|100] "%" Receiver
   SG_ UI_speedLimit : 16|8@1+ (1,50) [50|285] "kph" Receiver
   SG_ UI_stoppingMode : 40|2@1+ (1,0) [0|2] "" Receiver
   SG_ UI_systemPowerLimit : 0|5@1+ (20,20) [20|640] "kW" Receiver
   SG_ UI_systemTorqueLimit : 8|6@1+ (100,4000) [4000|10300] "Nm" Receiver
   SG_ UI_wasteMode : 36|2@1+ (1,0) [0|2] "" Receiver
   SG_ UI_wasteModeRegenLimit : 38|2@1+ (1,0) [0|3] "" Receiver
   SG_ UI_closureConfirmed : 14|2@1+ (1,0) [0|2] "" Receiver

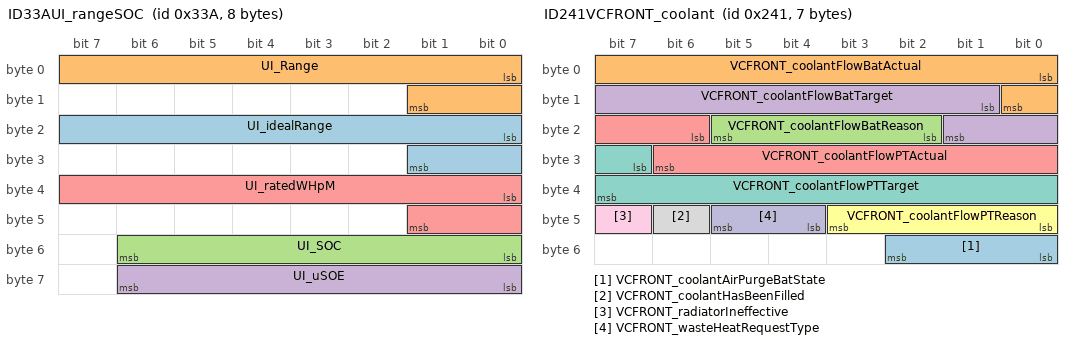
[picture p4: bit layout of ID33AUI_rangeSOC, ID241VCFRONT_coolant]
BO_ 826 ID33AUI_rangeSOC: 8 VehicleBus
   SG_ UI_idealRange : 16|10@1+ (1,0) [0|1023] "mi" Receiver
   SG_ UI_Range : 0|10@1+ (1,0) [0|1023] "mi" Receiver
   SG_ UI_SOC : 48|7@1+ (1,0) [0|127] "%" Receiver
   SG_ UI_uSOE : 56|7@1+ (1,0) [0|127] "%" Receiver
   SG_ UI_ratedWHpM : 32|10@1+ (1,0) [0|1023] "WHpM" Receiver

BO_ 577 ID241VCFRONT_coolant: 7 VehicleBus
   SG_ VCFRONT_coolantAirPurgeBatState : 48|3@1+ (1,0) [0|4] "" Receiver
   SG_ VCFRONT_coolantFlowBatActual : 0|9@1+ (0.1,0) [0|40] "LPM" Receiver
   SG_ VCFRONT_coolantFlowBatReason : 18|4@1+ (1,0) [0|14] "" Receiver
   SG_ VCFRONT_coolantFlowBatTarget : 9|9@1+ (0.1,0) [0|40] "LPM" Receiver
   SG_ VCFRONT_coolantFlowPTActual : 22|9@1+ (0.1,0) [0|40] "LPM" Receiver
   SG_ VCFRONT_coolantFlowPTReason : 40|4@1+ (1,0) [0|14] "" Receiver
   SG_ VCFRONT_coolantFlowPTTarget : 31|9@1+ (0.1,0) [0|40] "LPM" Receiver
   SG_ VCFRONT_coolantHasBeenFilled : 46|1@1+ (1,0) [0|1] "" Receiver
   SG_ VCFRONT_radiatorIneffective : 47|1@1+ (1,0) [0|1] "" Receiver
   SG_ VCFRONT_wasteHeatRequestType : 44|2@1+ (1,0) [0|2] "" Receiver

BO_ 708 ID2C4PCS_logging: 8 VehicleBus
   SG_ PCS_logMessageSelect M : 0|5@1+ (1,0) [0|26] "" Receiver
   SG_ PCS_1V2Max10s m9 : 43|11@1+ (0.001,0) [0|2.047] "V" Receiver
   SG_ PCS_1V2Min10s m9 : 32|11@1+ (0.001,0) [0|2.047] "V" Receiver
   SG_ PCS_1V5Max10s m9 : 19|11@1+ (0.001,0) [0|2.047] "V" Receiver
   SG_ PCS_1V5Min10s m9 : 8|11@1+ (0.001,0) [0|2.047] "V" Receiver
   SG_ PCS_5VNMax10s m9 : 54|10@1+ (0.01,0) [0|10.23] "V" Receiver
   SG_ PCS_acChargeSelfTestState m9 : 7|1@1+ (1,0) [0|1] "" Receiver
   SG_ PCS_chg5VL1Enable m5 : 61|1@1+ (1,0) [0|1] "" Receiver
   SG_ PCS_chgAcpwHeartbeatState m20 : 42|3@1+ (1,0) [0|4] "" Receiver
   SG_ PCS_chgCurrentSensorOutOfBandUs m20 : 32|10@1+ (0.01,0) [0|10.23] "us" Receiver
   SG_ PCS_chgInputFrequencyL1N m4 : 5|12@1+ (0.01,40) [40|80.95] "Hz" Receiver
   SG_ PCS_chgInputFrequencyL2N m4 : 17|12@1+ (0.01,40) [40|80.95] "Hz" Receiver
   SG_ PCS_chgInputFrequencyL3N m4 : 29|12@1+ (0.01,40) [40|80.95] "Hz" Receiver
   SG_ PCS_chgInputL1L2Vdc m21 : 36|10@1- (1,0) [-512|511] "V" Receiver
   SG_ PCS_chgInputL1L2Vrms m3 : 41|12@1+ (0.2,0) [0|819] "V" Receiver
   SG_ PCS_chgInputL1NVdc m21 : 5|10@1- (1,0) [-512|511] "V" Receiver
   SG_ PCS_chgInputL1NVrms m3 : 5|12@1+ (0.2,0) [0|819] "V" Receiver
   SG_ PCS_chgInputL2NVdc m21 : 16|10@1- (1,0) [-512|511] "V" Receiver
   SG_ PCS_chgInputL2NVrms m3 : 17|12@1+ (0.2,0) [0|819] "V" Receiver
   SG_ PCS_chgInputL3NVdc m21 : 26|10@1- (1,0) [-512|511] "V" Receiver
   SG_ PCS_chgInputL3NVrms m3 : 29|12@1+ (0.2,0) [0|819] "V" Receiver
   SG_ PCS_chgInputNGVdc m21 : 46|10@1- (1,0) [-512|511] "V" Receiver
   SG_ PCS_chgInputNGVrms m3 : 53|9@1+ (1,0) [0|511] "V" Receiver
   SG_ PCS_chgInternalPhaseConfig m4 : 41|4@1+ (1,0) [0|9] "" Receiver
   SG_ PCS_chgKwhLostByFreqDroop m20 : 48|8@1+ (0.1,0) [0|25.5] "kWh" Receiver
   SG_ PCS_chgL1L2PllLocked m5 : 57|1@1+ (1,0) [0|1] "" Receiver
   SG_ PCS_chgL1NPllLocked m5 : 54|1@1+ (1,0) [0|1] "" Receiver
   SG_ PCS_chgL2NPllLocked m5 : 55|1@1+ (1,0) [0|1] "" Receiver
   SG_ PCS_chgL3NPllLocked m5 : 56|1@1+ (1,0) [0|1] "" Receiver
   SG_ PCS_chgNgPllLocked m5 : 58|1@1+ (1,0) [0|1] "" Receiver
   SG_ PCS_chgOutputV m4 : 51|12@1+ (0.146484,0) [0|599.854] "V" Receiver
   SG_ PCS_chgPHAInputVPeak10s m13 : 5|9@1+ (1,0) [0|511] "V" Receiver
   SG_ PCS_chgPHBInputVPeak10s m13 : 14|9@1+ (1,0) [0|511] "V" Receiver
   SG_ PCS_chgPHCInputVPeak10s m13 : 23|9@1+ (1,0) [0|511] "V" Receiver
   SG_ PCS_chgPhAInputFreqWobbleCnt m13 : 32|8@1- (1,0) [-128|127] "s" Receiver
   SG_ PCS_chgPhAInputIrms m0 : 5|9@1+ (0.1,0) [0|51.1] "A" Receiver
   SG_ PCS_chgPhAIntBusV m0 : 14|9@1+ (1,0) [0|511] "V" Receiver
   SG_ PCS_chgPhAIntBusVMax10s m10 : 14|9@1+ (1,0) [0|511] "V" Receiver
   SG_ PCS_chgPhAIntBusVMin10s m10 : 5|9@1+ (1,0) [0|511] "V" Receiver
   SG_ PCS_chgPhAIntBusVTarget m0 : 23|9@1+ (1,0) [0|511] "V" Receiver
   SG_ PCS_chgPhALastShutdownReason m5 : 17|5@1+ (1,0) [0|17] "" Receiver
   SG_ PCS_chgPhALifetimekWh m10 : 31|24@1+ (0.01,0) [0|167772] "kWh" Receiver
   SG_ PCS_chgPhAMachineEnabled m23 : 5|1@1+ (1,0) [0|1] "" Receiver
   SG_ PCS_chgPhAMachineRotorFreqDroop m23 : 6|10@1- (0.01,0) [-5.12|5.11] "Hz" Receiver
   SG_ PCS_chgPhAMachineStatorCurrent m23 : 16|8@1- (0.2,0) [-25.6|25.4] "A" Receiver
   SG_ PCS_chgPhANoFlowBucket m20 : 5|9@1+ (0.01,0) [0|5.11] "-" Receiver
   SG_ PCS_chgPhAOutputI m0 : 32|8@1+ (0.1,0) [0|25.5] "A" Receiver
   SG_ PCS_chgPhAPchgVoltDeltaMax10s m10 : 23|8@1+ (0.5,0) [0|127.5] "V" Receiver
   SG_ PCS_chgPhARetryCount m5 : 32|3@1+ (1,0) [0|7] "" Receiver
   SG_ PCS_chgPhAState m5 : 5|4@1+ (1,0) [0|6] "" Receiver
   SG_ PCS_chgPhATransientRetryCount m10 : 55|9@1+ (0.1,0) [0|51.1] "-" Receiver
   SG_ PCS_chgPhBInputFreqWobbleCnt m13 : 40|8@1- (1,0) [-128|127] "s" Receiver
   SG_ PCS_chgPhBInputIrms m1 : 5|9@1+ (0.1,0) [0|51.1] "A" Receiver
   SG_ PCS_chgPhBIntBusV m1 : 14|9@1+ (1,0) [0|511] "V" Receiver
   SG_ PCS_chgPhBIntBusVMax10s m11 : 14|9@1+ (1,0) [0|511] "V" Receiver
   SG_ PCS_chgPhBIntBusVMin10s m11 : 5|9@1+ (1,0) [0|511] "V" Receiver
   SG_ PCS_chgPhBIntBusVTarget m1 : 23|9@1+ (1,0) [0|511] "V" Receiver
   SG_ PCS_chgPhBLastShutdownReason m5 : 22|5@1+ (1,0) [0|17] "" Receiver
   SG_ PCS_chgPhBLifetimekWh m11 : 31|24@1+ (0.01,0) [0|167772] "kWh" Receiver
   SG_ PCS_chgPhBMachineEnabled m23 : 24|1@1+ (1,0) [0|1] "" Receiver
   SG_ PCS_chgPhBMachineRotorFreqDroop m23 : 25|10@1- (0.01,0) [-5.12|5.11] "Hz" Receiver
   SG_ PCS_chgPhBMachineStatorCurrent m23 : 35|8@1- (0.2,0) [-25.6|25.4] "A" Receiver
   SG_ PCS_chgPhBNoFlowBucket m20 : 14|9@1+ (0.01,0) [0|5.11] "-" Receiver
   SG_ PCS_chgPhBOutputI m1 : 32|8@1+ (0.1,0) [0|25.5] "A" Receiver
   SG_ PCS_chgPhBPchgVoltDeltaMax10s m11 : 23|8@1+ (0.5,0) [0|127.5] "V" Receiver
   SG_ PCS_chgPhBRetryCount m5 : 35|3@1+ (1,0) [0|7] "" Receiver
   SG_ PCS_chgPhBState m5 : 9|4@1+ (1,0) [0|6] "" Receiver
   SG_ PCS_chgPhBTransientRetryCount m11 : 55|9@1+ (0.1,0) [0|51.1] "-" Receiver
   SG_ PCS_chgPhCInputFreqWobbleCnt m13 : 48|8@1- (1,0) [-128|127] "s" Receiver
   SG_ PCS_chgPhCInputIrms m2 : 5|9@1+ (0.1,0) [0|51.1] "A" Receiver
   SG_ PCS_chgPhCIntBusV m2 : 14|9@1+ (1,0) [0|511] "V" Receiver
   SG_ PCS_chgPhCIntBusVMax10s m12 : 14|9@1+ (1,0) [0|511] "V" Receiver
   SG_ PCS_chgPhCIntBusVMin10s m12 : 5|9@1+ (1,0) [0|511] "V" Receiver
   SG_ PCS_chgPhCIntBusVTarget m2 : 23|9@1+ (1,0) [0|511] "V" Receiver
   SG_ PCS_chgPhCLastShutdownReason m5 : 27|5@1+ (1,0) [0|17] "" Receiver
   SG_ PCS_chgPhCLifetimekWh m12 : 31|24@1+ (0.01,0) [0|167772] "kWh" Receiver
   SG_ PCS_chgPhCMachineEnabled m23 : 43|1@1+ (1,0) [0|1] "" Receiver
   SG_ PCS_chgPhCMachineRotorFreqDroop m23 : 44|10@1- (0.01,0) [-5.12|5.11] "Hz" Receiver
   SG_ PCS_chgPhCMachineStatorCurrent m23 : 54|8@1- (0.2,0) [-25.6|25.4] "A" Receiver
   SG_ PCS_chgPhCNoFlowBucket m20 : 23|9@1+ (0.01,0) [0|5.11] "-" Receiver
   SG_ PCS_chgPhCOutputI m2 : 32|8@1+ (0.1,0) [0|25.5] "A" Receiver
   SG_ PCS_chgPhCPchgVoltDeltaMax10s m12 : 23|8@1+ (0.5,0) [0|127.5] "V" Receiver
   SG_ PCS_chgPhCRetryCount m5 : 38|3@1+ (1,0) [0|7] "" Receiver
   SG_ PCS_chgPhCState m5 : 13|4@1+ (1,0) [0|6] "" Receiver
   SG_ PCS_chgPhCTransientRetryCount m12 : 55|9@1+ (0.1,0) [0|51.1] "-" Receiver
   SG_ PCS_chgPhManCurrentToDist m5 : 44|10@1+ (0.1,0) [0|100] "A" Receiver
   SG_ PCS_chgPhManOptimalPhsToUse m5 : 59|2@1+ (1,0) [0|3] "" Receiver
   SG_ PCS_chgPhasesPriority m4 : 45|6@1+ (1,0) [0|36] "" Receiver
   SG_ PCS_chgPwmEnableLineErrorCount m22 : 32|10@1+ (1,0) [0|1023] "" Receiver
   SG_ PCS_chgReqKwhLostByFreqDroop m20 : 56|8@1+ (0.1,0) [0|25.5] "kWh" Receiver
   SG_ PCS_chgRetryCount m5 : 41|3@1+ (1,0) [0|7] "" Receiver
   SG_ PCS_cpu2BootState m9 : 5|2@1+ (1,0) [0|3] "" Receiver
   SG_ PCS_dLogPhAChannel1Content m14 : 5|2@1+ (1,0) [0|3] "" Receiver
   SG_ PCS_dLogPhAChannel1Data m14 : 16|16@1- (0.02,0) [-655.36|655.34] "-" Receiver
   SG_ PCS_dLogPhAChannel2Content m15 : 5|2@1+ (1,0) [0|3] "" Receiver
   SG_ PCS_dLogPhAChannel2Data m15 : 16|16@1- (0.02,0) [-655.36|655.34] "-" Receiver
   SG_ PCS_dLogPhAChannel3Content m16 : 5|2@1+ (1,0) [0|3] "" Receiver
   SG_ PCS_dLogPhAChannel3Data m16 : 16|16@1- (0.02,0) [-655.36|655.34] "-" Receiver
   SG_ PCS_dLogPhAChannel4Content m17 : 5|2@1+ (1,0) [0|3] "" Receiver
   SG_ PCS_dLogPhAChannel4Data m17 : 16|16@1- (0.02,0) [-655.36|655.34] "-" Receiver
   SG_ PCS_dLogPhBChannel1Content m14 : 8|2@1+ (1,0) [0|3] "" Receiver
   SG_ PCS_dLogPhBChannel1Data m14 : 32|16@1- (0.02,0) [-655.36|655.34] "-" Receiver
   SG_ PCS_dLogPhBChannel2Content m15 : 8|2@1+ (1,0) [0|3] "" Receiver
   SG_ PCS_dLogPhBChannel2Data m15 : 32|16@1- (0.02,0) [-655.36|655.34] "-" Receiver
   SG_ PCS_dLogPhBChannel3Content m16 : 8|2@1+ (1,0) [0|3] "" Receiver
   SG_ PCS_dLogPhBChannel3Data m16 : 32|16@1- (0.02,0) [-655.36|655.34] "-" Receiver
   SG_ PCS_dLogPhBChannel4Content m17 : 8|2@1+ (1,0) [0|3] "" Receiver
   SG_ PCS_dLogPhBChannel4Data m17 : 32|16@1- (0.02,0) [-655.36|655.34] "-" Receiver
   SG_ PCS_dLogPhCChannel1Content m14 : 10|2@1+ (1,0) [0|3] "" Receiver
   SG_ PCS_dLogPhCChannel1Data m14 : 48|16@1- (0.02,0) [-655.36|655.34] "-" Receiver
   SG_ PCS_dLogPhCChannel2Content m15 : 10|2@1+ (1,0) [0|3] "" Receiver
   SG_ PCS_dLogPhCChannel2Data m15 : 48|16@1- (0.02,0) [-655.36|655.34] "-" Receiver
   SG_ PCS_dLogPhCChannel3Content m16 : 10|2@1+ (1,0) [0|3] "" Receiver
   SG_ PCS_dLogPhCChannel3Data m16 : 48|16@1- (0.02,0) [-655.36|655.34] "-" Receiver
   SG_ PCS_dLogPhCChannel4Content m17 : 10|2@1+ (1,0) [0|3] "" Receiver
   SG_ PCS_dLogPhCChannel4Data m17 : 48|16@1- (0.02,0) [-655.36|655.34] "-" Receiver
   SG_ PCS_dcdc12vSupportLifetimekWh m22 : 8|24@1+ (0.01,0) [0|167772] "kWh" Receiver
   SG_ PCS_dcdcCLAControllerOutput m7 : 16|10@1+ (0.001,0) [0|1] "1" Receiver
   SG_ PCS_dcdcClaCurrentFreq m7 : 48|12@1+ (0.0976563,0) [0|399.9] "kHz" Receiver
   SG_ PCS_dcdcCurrentLimit m6 : 20|12@1+ (0.1,0) [0|400] "A" Receiver
   SG_ PCS_dcdcHalfPeriodUs m8 : 40|16@1+ (0.000488281,0) [0|31.9995] "us" Receiver
   SG_ PCS_dcdcHvBusEstimated_C_uF m25 : 5|10@1+ (7.82014,0) [0|8000] "uF" Receiver
   SG_ PCS_dcdcHvBusEstimated_R_kOhm m25 : 16|10@1+ (0.0488759,0) [0|50] "kOhm" Receiver
   SG_ PCS_dcdcIntervalMaxFrequency m18 : 8|12@1+ (1,0) [0|400] "kHz" Receiver
   SG_ PCS_dcdcIntervalMaxHvBusVolt m18 : 24|13@1+ (0.1,0) [0|600] "V" Receiver
   SG_ PCS_dcdcIntervalMaxLvBusVolt m18 : 37|9@1+ (0.1,0) [0|40] "V" Receiver
   SG_ PCS_dcdcIntervalMaxLvOutputCurr m18 : 48|12@1+ (1,0) [0|400] "A" Receiver
   SG_ PCS_dcdcIntervalMinFrequency m19 : 8|12@1+ (1,0) [0|400] "kHz" Receiver
   SG_ PCS_dcdcIntervalMinHvBusVolt m19 : 24|13@1+ (0.1,0) [0|600] "V" Receiver
   SG_ PCS_dcdcIntervalMinLvBusVolt m19 : 37|9@1+ (0.1,0) [0|40] "V" Receiver
   SG_ PCS_dcdcIntervalMinLvOutputCurr m19 : 48|12@1+ (1,0) [0|400] "A" Receiver
   SG_ PCS_dcdcLvOutputCurrentTempLimit m6 : 32|12@1+ (0.1,0) [0|400] "A" Receiver
   SG_ PCS_dcdcMaxLvOutputCurrent m6 : 8|12@1+ (0.1,0) [0|400] "A" Receiver
   SG_ PCS_dcdcPchgStartHvBusVolt m24 : 16|12@1+ (0.146484,0) [0|599.854] "V" Receiver
   SG_ PCS_dcdcPchgStartLvBusVolt m24 : 5|10@1+ (0.0390625,0) [0|39.9609] "V" Receiver
   SG_ PCS_dcdcPwmEnableLineErrorCount m22 : 42|10@1+ (1,0) [0|1023] "" Receiver
   SG_ PCS_dcdcShortTimeUs m8 : 24|16@1+ (0.000488281,0) [0|31.9995] "us" Receiver
   SG_ PCS_dcdcTCommMeasured m8 : 8|16@1- (0.00195313,0) [-64|63.998] "us" Receiver
   SG_ PCS_dcdcTankVoltage m7 : 26|11@1- (1,0) [-1024|1023] "V" Receiver
   SG_ PCS_dcdcTankVoltageTarget m7 : 37|10@1+ (1,0) [0|1023] "V" Receiver
   SG_ PCS_dcdcUnifiedCommand m7 : 5|10@1+ (0.001,0) [0|1] "1" Receiver
   SG_ PCS_numAlertsSet m22 : 56|7@1+ (1,0) [0|127] "" Receiver

BO_ 955 ID3BBUI_power: 2 VehicleBus
   SG_ UI_powerExpected : 0|8@1+ (1,0) [0|100] "kW" Receiver
   SG_ UI_powerIdeal : 8|8@1+ (1,0) [0|100] "kW" Receiver

BO_ 1493 ID5D5RearDItemps: 5 VehicleBus
   SG_ DI_ph1Temp : 0|8@1+ (1,-40) [-40|120] "C" Receiver
   SG_ DI_ph2Temp : 8|8@1+ (1,-40) [-40|120] "C" Receiver
   SG_ DI_ph3Temp : 16|8@1+ (1,-40) [-40|120] "C" Receiver
   SG_ DI_pcbTemp2 : 24|8@1+ (1,-40) [-40|150] "C" Receiver
   SG_ DI_IGBTJunctTemp : 32|8@1+ (1,-40) [-40|200] "C" Receiver
   SG_ DI_lashAngle : 40|10@1+ (0.06,0) [0|60] "Deg" Receiver
   SG_ DI_lashCheckCount : 50|6@1+ (1,0) [0|63] "" Receiver
   SG_ DI_torqueWearTotal : 56|8@1+ (0.02,0) [0|5.08] "1" Receiver

BO_ 1366 ID556FrontDItemps: 5 VehicleBus
   SG_ DIF_ph1Temp : 0|8@1+ (1,-40) [-40|120] "C" Receiver
   SG_ DIF_ph2Temp : 8|8@1+ (1,-40) [-40|120] "C" Receiver
   SG_ DIF_ph3Temp : 16|8@1+ (1,-40) [-40|120] "C" Receiver
   SG_ DIF_pcbTemp2 : 24|8@1+ (1,-40) [-40|150] "C" Receiver
   SG_ DIF_IGBTJunctTemp : 32|8@1+ (1,-40) [-40|200] "C" Receiver
   SG_ DIF_lashAngle : 40|10@1+ (0.06,0) [0|60] "Deg" Receiver
   SG_ DIF_lashCheckCount : 50|6@1+ (1,0) [0|63] "" Receiver
   SG_ DIF_torqueWearTotal : 56|8@1+ (0.02,0) [0|5.08] "1" Receiver

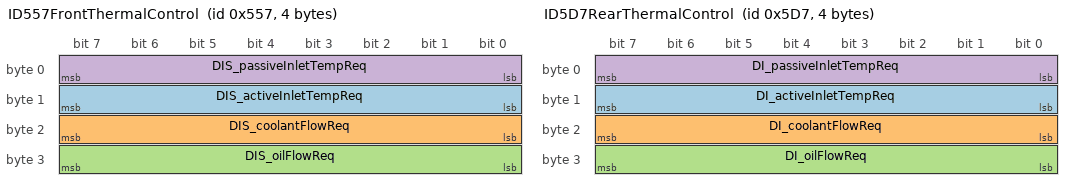
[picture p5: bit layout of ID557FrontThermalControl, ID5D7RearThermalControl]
BO_ 1367 ID557FrontThermalControl: 4 VehicleBus
   SG_ DIS_activeInletTempReq : 8|8@1+ (1,-40) [-40|120] "C" Receiver
   SG_ DIS_coolantFlowReq : 16|8@1+ (0.2,0) [0|50] "LPM" Receiver
   SG_ DIS_oilFlowReq : 24|8@1+ (0.06,0) [0|15] "LPM" Receiver
   SG_ DIS_passiveInletTempReq : 0|8@1+ (1,-40) [-40|120] "C" Receiver

BO_ 1495 ID5D7RearThermalControl: 4 VehicleBus
   SG_ DI_activeInletTempReq : 8|8@1+ (1,-40) [-40|120] "C" Receiver
   SG_ DI_coolantFlowReq : 16|8@1+ (0.2,0) [0|50] "LPM" Receiver
   SG_ DI_oilFlowReq : 24|8@1+ (0.06,0) [0|15] "LPM" Receiver
   SG_ DI_passiveInletTempReq : 0|8@1+ (1,-40) [-40|120] "C" Receiver

BO_ 2005 ID7D5DIR_debug: 8 VehicleBus
   SG_ DIR_debugSelector M : 0|8@1+ (1,0) [0|255] "" Receiver
   SG_ DIR_aebCancelReason m45 : 32|8@1+ (1,0) [0|255] "" Receiver
   SG_ DIR_aebFaultReason m45 : 16|4@1+ (1,0) [0|15] "" Receiver
   SG_ DIR_aebUnavailableReason m45 : 24|4@1+ (1,0) [0|10] "" Receiver
   SG_ DIR_brakeCpScale m2 : 16|9@1- (0.01,0.5) [-1|2] "N/N" Receiver
   SG_ DIR_brakeSwitchNC m42 : 63|1@1+ (1,0) [0|1] "" Receiver
   SG_ DIR_brakeSwitchNO m42 : 62|1@1+ (1,0) [0|1] "" Receiver
   SG_ DIR_brkStState m50 : 24|3@1+ (1,0) [0|6] "" Receiver
   SG_ DIR_busbarTemp m64 : 16|8@1+ (1,-40) [-40|215] "C" Receiver
   SG_ DIR_controlStack m67 : 56|8@1+ (0.4,0) [0|100] "%" Receiver
   SG_ DIR_cpu100HzAvg m66 : 48|8@1+ (0.4,0) [0|102] "%" Receiver
   SG_ DIR_cpu100HzMax m66 : 40|8@1+ (0.4,0) [0|102] "%" Receiver
   SG_ DIR_cpu100HzMin m66 : 32|8@1+ (0.4,0) [0|102] "%" Receiver
   SG_ DIR_cpu10HzAvg m66 : 24|8@1+ (0.4,0) [0|102] "%" Receiver
   SG_ DIR_cpu10HzMax m66 : 16|8@1+ (0.4,0) [0|102] "%" Receiver
   SG_ DIR_cpu10HzMin m66 : 8|8@1+ (0.4,0) [0|102] "%" Receiver
   SG_ DIR_cpu1HzAvg m128 : 32|8@1+ (0.4,0) [0|102] "%" Receiver
   SG_ DIR_cpu1HzMax m128 : 24|8@1+ (0.4,0) [0|102] "%" Receiver
   SG_ DIR_cpu1HzMin m128 : 16|8@1+ (0.4,0) [0|102] "%" Receiver
   SG_ DIR_cpu1kHzAvg m67 : 24|8@1+ (0.4,0) [0|102] "%" Receiver
   SG_ DIR_cpu1kHzMax m67 : 16|8@1+ (0.4,0) [0|102] "%" Receiver
   SG_ DIR_cpu1kHzMin m67 : 8|8@1+ (0.4,0) [0|102] "%" Receiver
   SG_ DIR_cpu20kHzAvg m67 : 48|8@1+ (0.4,0) [0|102] "%" Receiver
   SG_ DIR_cpu20kHzMax m67 : 40|8@1+ (0.4,0) [0|102] "%" Receiver
   SG_ DIR_cpu20kHzMin m67 : 32|8@1+ (0.4,0) [0|102] "%" Receiver
   SG_ DIR_cpuIDWord0 m131 : 16|16@1+ (1,0) [0|65535] "" Receiver
   SG_ DIR_cpuIDWord1 m132 : 16|16@1+ (1,0) [0|65535] "" Receiver
   SG_ DIR_cpuIDWord2 m132 : 32|16@1+ (1,0) [0|65535] "" Receiver
   SG_ DIR_cpuIDWord3 m132 : 48|16@1+ (1,0) [0|65535] "" Receiver
   SG_ DIR_crc m131 : 32|32@1+ (1,0) [0|4.29497e+09] "" Receiver
   SG_ DIR_currentLimit m41 : 32|16@1+ (0.1,0) [0|6553.5] "A" Receiver
   SG_ DIR_dcCableCurrentEst m37 : 16|16@1- (0.1,0) [-3276.8|3276.7] "A" Receiver
   SG_ DIR_dcCableHeat m47 : 32|16@1+ (0.001,0) [0|65.535] "kA2s" Receiver
   SG_ DIR_dcCapTemp m64 : 8|8@1+ (1,-40) [-40|215] "C" Receiver
   SG_ DIR_dcLinkCapTemp m70 : 32|8@1+ (1,-40) [-40|215] "C" Receiver
   SG_ DIR_decodeHardwareStack m68 : 24|8@1+ (0.4,0) [0|100] "%" Receiver
   SG_ DIR_driveUnitOdometer m69 : 32|32@1+ (10,0) [0|4.29497e+10] "rev" Receiver
   SG_ DIR_eepromStack m68 : 32|8@1+ (0.4,0) [0|100] "%" Receiver
   SG_ DIR_fluxState m42 : 16|4@1+ (1,0) [0|10] "" Receiver
   SG_ DIR_gainScale m37 : 8|8@1+ (0.01,0) [0|2.55] "scale" Receiver
   SG_ DIR_gateDriveState m50 : 10|3@1+ (1,0) [0|4] "" Receiver
   SG_ DIR_gateDriveSupplyState m50 : 8|2@1+ (1,0) [0|3] "" Receiver
   SG_ DIR_hvDcCableTemp m70 : 40|8@1+ (1,-40) [-40|215] "C" Receiver
   SG_ DIR_hwFaultCount m69 : 8|4@1+ (1,0) [0|15] "" Receiver
   SG_ DIR_idleStack m68 : 16|8@1+ (0.4,0) [0|100] "%" Receiver
   SG_ DIR_immobilizerCondition m64 : 63|1@1+ (1,0) [0|1] "" Receiver
   SG_ DIR_immobilizerStack m68 : 56|8@1+ (0.4,0) [0|100] "%" Receiver
   SG_ DIR_internalAngleFilt m37 : 48|16@1+ (0.0003,0) [0|8] "rad" Receiver
   SG_ DIR_llrScale m42 : 32|8@1+ (0.015,0) [0|3.825] "scale" Receiver
   SG_ DIR_llsScale m42 : 24|8@1+ (0.004,0) [0|1.02] "scale" Receiver
   SG_ DIR_lmScale m36 : 8|8@1+ (0.004,0) [0|1.02] "scale" Receiver
   SG_ DIR_loadAngle m42 : 40|16@1- (0.0003,0) [-4|4] "rad" Receiver
   SG_ DIR_loadAngleMargin m37 : 32|16@1- (0.0003,0) [-4|4] "rad" Receiver
   SG_ DIR_locCheckSpeedRef m75 : 54|8@1+ (1,0) [0|250] "kph" Receiver
   SG_ DIR_locFeedFwTrq m75 : 44|10@1- (10,0) [-5000|5000] "Nm" Receiver
   SG_ DIR_locTargetAccel m75 : 8|8@1- (0.08,-4.72) [-15|5.4] "m/s^2" Receiver
   SG_ DIR_locTargetSpeed m75 : 16|8@1+ (1,0) [0|250] "kph" Receiver
   SG_ DIR_locUi m75 : 34|10@1- (10,0) [-5000|5000] "Nm" Receiver
   SG_ DIR_locUp m75 : 24|10@1- (10,0) [-5000|5000] "Nm" Receiver
   SG_ DIR_magnetTempEst m47 : 48|8@1+ (1,-40) [-40|180] "C" Receiver
   SG_ DIR_module10HzStack m66 : 56|8@1+ (0.4,0) [0|100] "%" Receiver
   SG_ DIR_motorIA m32 : 16|16@1+ (0.1,0) [0|6553.5] "A" Receiver
   SG_ DIR_motorIAavg m38 : 32|16@1- (0.1,0) [-3276.8|3276.7] "A" Receiver
   SG_ DIR_motorIB m32 : 32|16@1+ (0.1,0) [0|6553.5] "A" Receiver
   SG_ DIR_motorIBavg m38 : 48|16@1- (0.1,0) [-3276.8|3276.7] "A" Receiver
   SG_ DIR_motorIC m32 : 48|16@1+ (0.1,0) [0|6553.5] "A" Receiver
   SG_ DIR_motorType m128 : 8|5@1+ (1,0) [0|28] "" Receiver
   SG_ DIR_motorV m34 : 48|16@1+ (2e-05,0) [0|1.3107] "mindex" Receiver
   SG_ DIR_muSurfHigh m2 : 8|8@1+ (0.005,0) [0|1.2] "N/N" Receiver
   SG_ DIR_negDcBusbarTemp m70 : 48|8@1+ (1,-40) [-40|215] "C" Receiver
   SG_ DIR_offsetA m32 : 8|8@1- (0.1,0) [-12.8|12.7] "A" Receiver
   SG_ DIR_offsetB m33 : 8|8@1- (0.1,0) [-12.8|12.7] "A" Receiver
   SG_ DIR_oilPumpMotorSpeed m46 : 8|8@1+ (40,0) [0|10200] "RPM" Receiver
   SG_ DIR_oilPumpPhaseVoltage m46 : 16|8@1+ (0.1,0) [0|25.4] "V" Receiver
   SG_ DIR_oilPumpPressureEstimateMax m46 : 24|8@1+ (2,0) [0|500] "kPa" Receiver
   SG_ DIR_oilPumpPressureExpectedMin m46 : 32|8@1+ (2,0) [0|500] "kPa" Receiver
   SG_ DIR_opdUnavailableReason m45 : 40|4@1+ (1,0) [0|15] "" Receiver
   SG_ DIR_pcsTemp m64 : 24|8@1+ (1,-40) [-40|215] "C" Receiver
   SG_ DIR_peakFlux m36 : 48|16@1+ (0.0001,0) [0|6.5535] "Wb" Receiver
   SG_ DIR_peakIQref m38 : 16|16@1+ (0.1,0) [0|6553.5] "A" Receiver
   SG_ DIR_pedalPosFilt m2 : 32|8@1+ (0.4,0) [0|100] "%" Receiver
   SG_ DIR_phaseOutBusbarTemp m70 : 8|8@1+ (1,-40) [-40|215] "C" Receiver
   SG_ DIR_phaseOutBusbarWeldTemp m70 : 16|8@1+ (1,-40) [-40|215] "C" Receiver
   SG_ DIR_phaseOutLugTemp m70 : 24|8@1+ (1,-40) [-40|215] "C" Receiver
   SG_ DIR_posDcBusbarTemp m70 : 56|8@1+ (1,-40) [-40|215] "C" Receiver
   SG_ DIR_powerStageSafeState m50 : 13|2@1+ (1,0) [0|3] "" Receiver
   SG_ DIR_pwrSatChargeCurrent m42 : 8|8@1+ (0.4,0) [0|102] "%" Receiver
   SG_ DIR_pwrSatDischargeCurrent m40 : 8|8@1+ (0.4,0) [0|102] "%" Receiver
   SG_ DIR_pwrSatMaxBusVoltage m39 : 48|8@1+ (0.4,0) [0|102] "%" Receiver
   SG_ DIR_pwrSatMaxDischargePower m39 : 16|8@1+ (0.4,0) [0|102] "%" Receiver
   SG_ DIR_pwrSatMaxRegenPower m39 : 24|8@1+ (0.4,0) [0|102] "%" Receiver
   SG_ DIR_pwrSatMinBusVoltage m39 : 56|8@1+ (0.4,0) [0|102] "%" Receiver
   SG_ DIR_resolverClaMIA m48 : 43|1@1+ (1,0) [0|1] "" Receiver
   SG_ DIR_resolverCommonGain m48 : 32|8@1+ (0.025,0) [0|5] "1" Receiver
   SG_ DIR_resolverCosFiltered m52 : 32|8@1- (0.01,0) [-1|1] "1" Receiver
   SG_ DIR_resolverCosRmsSquared m52 : 16|8@1+ (0.005,0) [0|1] "1" Receiver
   SG_ DIR_resolverErrorRmsSquared m52 : 48|8@1+ (0.005,0) [0|1] "1" Receiver
   SG_ DIR_resolverNoCarrier m48 : 41|1@1+ (1,0) [0|1] "" Receiver
   SG_ DIR_resolverNoPhaseLock m48 : 42|1@1+ (1,0) [0|1] "" Receiver
   SG_ DIR_resolverOffsetCos m48 : 8|8@1+ (0.015,0) [0|3.3] "V" Receiver
   SG_ DIR_resolverOffsetSin m48 : 16|8@1+ (0.015,0) [0|3.3] "V" Receiver
   SG_ DIR_resolverPhaseOffset m48 : 24|8@1+ (0.1,7.5) [7.5|32.5] "us" Receiver
   SG_ DIR_resolverReady m48 : 40|1@1+ (1,0) [0|1] "" Receiver
   SG_ DIR_resolverSinFiltered m52 : 40|8@1- (0.01,0) [-1|1] "1" Receiver
   SG_ DIR_resolverSinRmsSquared m52 : 24|8@1+ (0.005,0) [0|1] "1" Receiver
   SG_ DIR_rotorFlux m47 : 16|16@1+ (0.0001,0) [0|6.5535] "Wb" Receiver
   SG_ DIR_rotorMaxMagnetTemp m72 : 16|8@1+ (1,-40) [-40|215] "C" Receiver
   SG_ DIR_rotorOffsetEst m43 : 8|12@1- (0.01,0) [-20|20] "deg" Receiver
   SG_ DIR_rotorOffsetLearningState m63 : 8|4@1+ (1,0) [0|9] "" Receiver
   SG_ DIR_rotorOffsetMean m43 : 20|12@1- (0.01,0) [-20|20] "deg" Receiver
   SG_ DIR_rsScale m34 : 8|8@1+ (0.01,0) [0|2.55] "scale" Receiver
   SG_ DIR_soptMaxCurrentMagSqrd m49 : 40|16@1+ (100,0) [0|6.5535e+06] "A2" Receiver
   SG_ DIR_soptTimeToOff m49 : 24|11@1+ (0.05,0) [0|100] "ms" Receiver
   SG_ DIR_soptTimeToTrip m49 : 8|8@1+ (0.05,0) [0|10] "ms" Receiver
   SG_ DIR_soptTripDelay m49 : 16|8@1+ (0.05,0) [0|10] "ms" Receiver
   SG_ DIR_ssmState m38 : 8|4@1+ (1,0) [0|8] "" Receiver
   SG_ DIR_statorEndWindingTemp m72 : 8|8@1+ (1,-40) [-40|215] "C" Receiver
   SG_ DIR_statorFluxFdb m35 : 32|16@1+ (0.0001,0) [0|6.5535] "Wb" Receiver
   SG_ DIR_statorFluxRef m35 : 16|16@1+ (0.0001,0) [0|6.5535] "Wb" Receiver
   SG_ DIR_statorIDfdb m33 : 32|16@1- (0.1,0) [-3276.8|3276.7] "A" Receiver
   SG_ DIR_statorIDref m33 : 16|16@1- (0.1,0) [-3276.8|3276.7] "A" Receiver
   SG_ DIR_statorIQfdb m34 : 32|16@1- (0.1,0) [-3276.8|3276.7] "A" Receiver
   SG_ DIR_statorIQref m34 : 16|16@1- (0.1,0) [-3276.8|3276.7] "A" Receiver
   SG_ DIR_statorTemp1 m64 : 32|8@1+ (1,-40) [-40|215] "C" Receiver
   SG_ DIR_statorTemp2 m64 : 40|8@1+ (1,-40) [-40|215] "C" Receiver
   SG_ DIR_statorVD m36 : 32|16@1- (4e-05,0) [-1.31072|1.31068] "mindex" Receiver
   SG_ DIR_statorVDFiltered m63 : 16|16@1- (4e-05,0) [-1.31072|1.31068] "mindex" Receiver
   SG_ DIR_statorVQ m36 : 16|16@1- (4e-05,0) [-1.31072|1.31068] "mindex" Receiver
   SG_ DIR_statorVQFiltered m63 : 32|16@1- (4e-05,0) [-1.31072|1.31068] "mindex" Receiver
   SG_ DIR_sysHeatPowerOptimal m50 : 16|8@1+ (0.08,0) [0|20] "kW" Receiver
   SG_ DIR_sysPedalMaxTorque m44 : 22|14@1+ (0.1,0) [0|1638.3] "Nm" Receiver
   SG_ DIR_sysPedalMinTorque m44 : 8|14@1+ (0.1,-1638.3) [-1638.3|0] "Nm" Receiver
   SG_ DIR_sysPostPedalMaxTorque m44 : 50|14@1+ (0.1,0) [0|1638.3] "Nm" Receiver
   SG_ DIR_sysPostPedalMinTorque m44 : 36|14@1+ (0.1,-1638.3) [-1638.3|0] "Nm" Receiver
   SG_ DIR_systemStack m68 : 8|8@1+ (0.4,0) [0|100] "%" Receiver
   SG_ DIR_systemTorqueCommand m35 : 48|16@1- (0.035,0) [-1146.88|1146.85] "Nm" Receiver
   SG_ DIR_tcMaxRequest m40 : 16|8@1+ (5,0) [0|1275] "Nm" Receiver
   SG_ DIR_tcMinRequest m40 : 24|8@1+ (5,0) [0|1275] "Nm" Receiver
   SG_ DIR_torquePerAmp m33 : 48|16@1+ (0.0001,0) [0|6.5535] "Nm/A" Receiver
   SG_ DIR_tqSatMotorCurrent m39 : 40|8@1+ (0.4,0) [0|102] "%" Receiver
   SG_ DIR_tqSatMotorVoltage m39 : 32|8@1+ (0.4,0) [0|102] "%" Receiver
   SG_ DIR_tqSatThermal m39 : 8|8@1+ (0.4,0) [0|102] "%" Receiver
   SG_ DIR_tqSatUiDriveTorque m40 : 32|8@1+ (0.4,0) [0|102] "%" Receiver
   SG_ DIR_tqSatUiRegenTorque m40 : 40|8@1+ (0.4,0) [0|102] "%" Receiver
   SG_ DIR_tqScaleDifferential m35 : 8|8@1+ (0.4,0) [0|102] "%" Receiver
   SG_ DIR_tqScaleMaxMotorSpeed m40 : 48|8@1+ (0.4,0) [0|102] "%" Receiver
   SG_ DIR_tqScaleShift m40 : 56|8@1+ (0.4,0) [0|102] "%" Receiver
   SG_ DIR_udsStack m68 : 40|8@1+ (0.4,0) [0|100] "%" Receiver
   SG_ DIR_usmState m38 : 12|3@1+ (1,0) [0|7] "" Receiver
   SG_ DIR_veMassInvRaw m41 : 8|12@1+ (1e-07,0.0001) [0.0001|0.0005] "1/kg" Receiver
   SG_ DIR_veResForce m41 : 20|12@1- (0.0005,0) [-1.024|1.0235] "G" Receiver
   SG_ DIR_velocityEstimatorState m65 : 8|3@1+ (1,0) [0|4] "" Receiver
   SG_ DIR_wasteCurrentLimit m41 : 48|16@1+ (0.1,0) [0|6553.5] "A" Receiver
   SG_ DIR_xcpStack m68 : 48|8@1+ (0.4,0) [0|100] "%" Receiver

BO_ 1879 ID757DIF_debug: 8 VehicleBus
   SG_ DIF_debugSelector M : 0|8@1+ (1,0) [0|255] "" Receiver
   SG_ DIF_aebCancelReason m45 : 32|8@1+ (1,0) [0|255] "" Receiver
   SG_ DIF_aebFaultReason m45 : 16|4@1+ (1,0) [0|15] "" Receiver
   SG_ DIF_aebUnavailableReason m45 : 24|4@1+ (1,0) [0|10] "" Receiver
   SG_ DIF_brakeCpScale m2 : 16|9@1- (0.01,0.5) [-1|2] "N/N" Receiver
   SG_ DIF_brakeSwitchNC m42 : 63|1@1+ (1,0) [0|1] "" Receiver
   SG_ DIF_brakeSwitchNO m42 : 62|1@1+ (1,0) [0|1] "" Receiver
   SG_ DIF_brkStState m50 : 24|3@1+ (1,0) [0|6] "" Receiver
   SG_ DIF_busbarTemp m64 : 16|8@1+ (1,-40) [-40|215] "C" Receiver
   SG_ DIF_controlStack m67 : 56|8@1+ (0.4,0) [0|100] "%" Receiver
   SG_ DIF_cpu100HzAvg m66 : 48|8@1+ (0.4,0) [0|102] "%" Receiver
   SG_ DIF_cpu100HzMax m66 : 40|8@1+ (0.4,0) [0|102] "%" Receiver
   SG_ DIF_cpu100HzMin m66 : 32|8@1+ (0.4,0) [0|102] "%" Receiver
   SG_ DIF_cpu10HzAvg m66 : 24|8@1+ (0.4,0) [0|102] "%" Receiver
   SG_ DIF_cpu10HzMax m66 : 16|8@1+ (0.4,0) [0|102] "%" Receiver
   SG_ DIF_cpu10HzMin m66 : 8|8@1+ (0.4,0) [0|102] "%" Receiver
   SG_ DIF_cpu1HzAvg m128 : 32|8@1+ (0.4,0) [0|102] "%" Receiver
   SG_ DIF_cpu1HzMax m128 : 24|8@1+ (0.4,0) [0|102] "%" Receiver
   SG_ DIF_cpu1HzMin m128 : 16|8@1+ (0.4,0) [0|102] "%" Receiver
   SG_ DIF_cpu1kHzAvg m67 : 24|8@1+ (0.4,0) [0|102] "%" Receiver
   SG_ DIF_cpu1kHzMax m67 : 16|8@1+ (0.4,0) [0|102] "%" Receiver
   SG_ DIF_cpu1kHzMin m67 : 8|8@1+ (0.4,0) [0|102] "%" Receiver
   SG_ DIF_cpu20kHzAvg m67 : 48|8@1+ (0.4,0) [0|102] "%" Receiver
   SG_ DIF_cpu20kHzMax m67 : 40|8@1+ (0.4,0) [0|102] "%" Receiver
   SG_ DIF_cpu20kHzMin m67 : 32|8@1+ (0.4,0) [0|102] "%" Receiver
   SG_ DIF_cpuIDWord0 m131 : 16|16@1+ (1,0) [0|65535] "" Receiver
   SG_ DIF_cpuIDWord1 m132 : 16|16@1+ (1,0) [0|65535] "" Receiver
   SG_ DIF_cpuIDWord2 m132 : 32|16@1+ (1,0) [0|65535] "" Receiver
   SG_ DIF_cpuIDWord3 m132 : 48|16@1+ (1,0) [0|65535] "" Receiver
   SG_ DIF_crc m131 : 32|32@1+ (1,0) [0|4.29497e+09] "" Receiver
   SG_ DIF_currentLimit m41 : 32|16@1+ (0.1,0) [0|6553.5] "A" Receiver
   SG_ DIF_dcCableCurrentEst m37 : 16|16@1- (0.1,0) [-3276.8|3276.7] "A" Receiver
   SG_ DIF_dcCableHeat m47 : 32|16@1+ (0.001,0) [0|65.535] "kA2s" Receiver
   SG_ DIF_dcCapTemp m64 : 8|8@1+ (1,-40) [-40|215] "C" Receiver
   SG_ DIF_dcLinkCapTemp m70 : 32|8@1+ (1,-40) [-40|215] "C" Receiver
   SG_ DIF_decodeHardwareStack m68 : 24|8@1+ (0.4,0) [0|100] "%" Receiver
   SG_ DIF_driveUnitOdometer m69 : 32|32@1+ (10,0) [0|4.29497e+10] "rev" Receiver
   SG_ DIF_eepromStack m68 : 32|8@1+ (0.4,0) [0|100] "%" Receiver
   SG_ DIF_fluxState m42 : 16|4@1+ (1,0) [0|10] "" Receiver
   SG_ DIF_gainScale m37 : 8|8@1+ (0.01,0) [0|2.55] "scale" Receiver
   SG_ DIF_gateDriveState m50 : 10|3@1+ (1,0) [0|4] "" Receiver
   SG_ DIF_gateDriveSupplyState m50 : 8|2@1+ (1,0) [0|3] "" Receiver
   SG_ DIF_hvDcCableTemp m70 : 40|8@1+ (1,-40) [-40|215] "C" Receiver
   SG_ DIF_hwFaultCount m69 : 8|4@1+ (1,0) [0|15] "" Receiver
   SG_ DIF_idleStack m68 : 16|8@1+ (0.4,0) [0|100] "%" Receiver
   SG_ DIF_immobilizerCondition m64 : 63|1@1+ (1,0) [0|1] "" Receiver
   SG_ DIF_immobilizerStack m68 : 56|8@1+ (0.4,0) [0|100] "%" Receiver
   SG_ DIF_internalAngleFilt m37 : 48|16@1+ (0.0003,0) [0|8] "rad" Receiver
   SG_ DIF_llrScale m42 : 32|8@1+ (0.015,0) [0|3.825] "scale" Receiver
   SG_ DIF_llsScale m42 : 24|8@1+ (0.004,0) [0|1.02] "scale" Receiver
   SG_ DIF_lmScale m36 : 8|8@1+ (0.004,0) [0|1.02] "scale" Receiver
   SG_ DIF_loadAngle m42 : 40|16@1- (0.0003,0) [-4|4] "rad" Receiver
   SG_ DIF_loadAngleMargin m37 : 32|16@1- (0.0003,0) [-4|4] "rad" Receiver
   SG_ DIF_locCheckSpeedRef m75 : 54|8@1+ (1,0) [0|250] "kph" Receiver
   SG_ DIF_locFeedFwTrq m75 : 44|10@1- (10,0) [-5000|5000] "Nm" Receiver
   SG_ DIF_locTargetAccel m75 : 8|8@1- (0.08,-4.72) [-15|5.4] "m/s^2" Receiver
   SG_ DIF_locTargetSpeed m75 : 16|8@1+ (1,0) [0|250] "kph" Receiver
   SG_ DIF_locUi m75 : 34|10@1- (10,0) [-5000|5000] "Nm" Receiver
   SG_ DIF_locUp m75 : 24|10@1- (10,0) [-5000|5000] "Nm" Receiver
   SG_ DIF_magnetTempEst m47 : 48|8@1+ (1,-40) [-40|180] "C" Receiver
   SG_ DIF_module10HzStack m66 : 56|8@1+ (0.4,0) [0|100] "%" Receiver
   SG_ DIF_motorIA m32 : 16|16@1+ (0.1,0) [0|6553.5] "A" Receiver
   SG_ DIF_motorIAavg m38 : 32|16@1- (0.1,0) [-3276.8|3276.7] "A" Receiver
   SG_ DIF_motorIB m32 : 32|16@1+ (0.1,0) [0|6553.5] "A" Receiver
   SG_ DIF_motorIBavg m38 : 48|16@1- (0.1,0) [-3276.8|3276.7] "A" Receiver
   SG_ DIF_motorIC m32 : 48|16@1+ (0.1,0) [0|6553.5] "A" Receiver
   SG_ DIF_motorType m128 : 8|5@1+ (1,0) [0|28] "" Receiver
   SG_ DIF_motorV m34 : 48|16@1+ (2e-05,0) [0|1.3107] "mindex" Receiver
   SG_ DIF_muSurfHigh m2 : 8|8@1+ (0.005,0) [0|1.2] "N/N" Receiver
   SG_ DIF_negDcBusbarTemp m70 : 48|8@1+ (1,-40) [-40|215] "C" Receiver
   SG_ DIF_offsetA m32 : 8|8@1- (0.1,0) [-12.8|12.7] "A" Receiver
   SG_ DIF_offsetB m33 : 8|8@1- (0.1,0) [-12.8|12.7] "A" Receiver
   SG_ DIF_oilPumpMotorSpeed m46 : 8|8@1+ (40,0) [0|10200] "RPM" Receiver
   SG_ DIF_oilPumpPhaseVoltage m46 : 16|8@1+ (0.1,0) [0|25.4] "V" Receiver
   SG_ DIF_oilPumpPressureEstimateMax m46 : 24|8@1+ (2,0) [0|500] "kPa" Receiver
   SG_ DIF_oilPumpPressureExpectedMin m46 : 32|8@1+ (2,0) [0|500] "kPa" Receiver
   SG_ DIF_opdUnavailableReason m45 : 40|4@1+ (1,0) [0|15] "" Receiver
   SG_ DIF_pcsTemp m64 : 24|8@1+ (1,-40) [-40|215] "C" Receiver
   SG_ DIF_peakFlux m36 : 48|16@1+ (0.0001,0) [0|6.5535] "Wb" Receiver
   SG_ DIF_peakIQref m38 : 16|16@1+ (0.1,0) [0|6553.5] "A" Receiver
   SG_ DIF_pedalPosFilt m2 : 32|8@1+ (0.4,0) [0|100] "%" Receiver
   SG_ DIF_phaseOutBusbarTemp m70 : 8|8@1+ (1,-40) [-40|215] "C" Receiver
   SG_ DIF_phaseOutBusbarWeldTemp m70 : 16|8@1+ (1,-40) [-40|215] "C" Receiver
   SG_ DIF_phaseOutLugTemp m70 : 24|8@1+ (1,-40) [-40|215] "C" Receiver
   SG_ DIF_posDcBusbarTemp m70 : 56|8@1+ (1,-40) [-40|215] "C" Receiver
   SG_ DIF_powerStageSafeState m50 : 13|2@1+ (1,0) [0|3] "" Receiver
   SG_ DIF_pwrSatChargeCurrent m42 : 8|8@1+ (0.4,0) [0|102] "%" Receiver
   SG_ DIF_pwrSatDischargeCurrent m40 : 8|8@1+ (0.4,0) [0|102] "%" Receiver
   SG_ DIF_pwrSatMaxBusVoltage m39 : 48|8@1+ (0.4,0) [0|102] "%" Receiver
   SG_ DIF_pwrSatMaxDischargePower m39 : 16|8@1+ (0.4,0) [0|102] "%" Receiver
   SG_ DIF_pwrSatMaxRegenPower m39 : 24|8@1+ (0.4,0) [0|102] "%" Receiver
   SG_ DIF_pwrSatMinBusVoltage m39 : 56|8@1+ (0.4,0) [0|102] "%" Receiver
   SG_ DIF_resolverClaMIA m48 : 43|1@1+ (1,0) [0|1] "" Receiver
   SG_ DIF_resolverCommonGain m48 : 32|8@1+ (0.025,0) [0|5] "1" Receiver
   SG_ DIF_resolverCosFiltered m52 : 32|8@1- (0.01,0) [-1|1] "1" Receiver
   SG_ DIF_resolverCosRmsSquared m52 : 16|8@1+ (0.005,0) [0|1] "1" Receiver
   SG_ DIF_resolverErrorRmsSquared m52 : 48|8@1+ (0.005,0) [0|1] "1" Receiver
   SG_ DIF_resolverNoCarrier m48 : 41|1@1+ (1,0) [0|1] "" Receiver
   SG_ DIF_resolverNoPhaseLock m48 : 42|1@1+ (1,0) [0|1] "" Receiver
   SG_ DIF_resolverOffsetCos m48 : 8|8@1+ (0.015,0) [0|3.3] "V" Receiver
   SG_ DIF_resolverOffsetSin m48 : 16|8@1+ (0.015,0) [0|3.3] "V" Receiver
   SG_ DIF_resolverPhaseOffset m48 : 24|8@1+ (0.1,7.5) [7.5|32.5] "us" Receiver
   SG_ DIF_resolverReady m48 : 40|1@1+ (1,0) [0|1] "" Receiver
   SG_ DIF_resolverSinFiltered m52 : 40|8@1- (0.01,0) [-1|1] "1" Receiver
   SG_ DIF_resolverSinRmsSquared m52 : 24|8@1+ (0.005,0) [0|1] "1" Receiver
   SG_ DIF_rotorFlux m47 : 16|16@1+ (0.0001,0) [0|6.5535] "Wb" Receiver
   SG_ DIF_rotorMaxMagnetTemp m72 : 16|8@1+ (1,-40) [-40|215] "C" Receiver
   SG_ DIF_rotorOffsetEst m43 : 8|12@1- (0.01,0) [-20|20] "deg" Receiver
   SG_ DIF_rotorOffsetLearningState m63 : 8|4@1+ (1,0) [0|9] "" Receiver
   SG_ DIF_rotorOffsetMean m43 : 20|12@1- (0.01,0) [-20|20] "deg" Receiver
   SG_ DIF_rsScale m34 : 8|8@1+ (0.01,0) [0|2.55] "scale" Receiver
   SG_ DIF_soptMaxCurrentMagSqrd m49 : 40|16@1+ (100,0) [0|6.5535e+06] "A2" Receiver
   SG_ DIF_soptTimeToOff m49 : 24|11@1+ (0.05,0) [0|100] "ms" Receiver
   SG_ DIF_soptTimeToTrip m49 : 8|8@1+ (0.05,0) [0|10] "ms" Receiver
   SG_ DIF_soptTripDelay m49 : 16|8@1+ (0.05,0) [0|10] "ms" Receiver
   SG_ DIF_ssmState m38 : 8|4@1+ (1,0) [0|8] "" Receiver
   SG_ DIF_statorEndWindingTemp m72 : 8|8@1+ (1,-40) [-40|215] "C" Receiver
   SG_ DIF_statorFluxFdb m35 : 32|16@1+ (0.0001,0) [0|6.5535] "Wb" Receiver
   SG_ DIF_statorFluxRef m35 : 16|16@1+ (0.0001,0) [0|6.5535] "Wb" Receiver
   SG_ DIF_statorIDfdb m33 : 32|16@1- (0.1,0) [-3276.8|3276.7] "A" Receiver
   SG_ DIF_statorIDref m33 : 16|16@1- (0.1,0) [-3276.8|3276.7] "A" Receiver
   SG_ DIF_statorIQfdb m34 : 32|16@1- (0.1,0) [-3276.8|3276.7] "A" Receiver
   SG_ DIF_statorIQref m34 : 16|16@1- (0.1,0) [-3276.8|3276.7] "A" Receiver
   SG_ DIF_statorTemp1 m64 : 32|8@1+ (1,-40) [-40|215] "C" Receiver
   SG_ DIF_statorTemp2 m64 : 40|8@1+ (1,-40) [-40|215] "C" Receiver
   SG_ DIF_statorVD m36 : 32|16@1- (4e-05,0) [-1.31072|1.31068] "mindex" Receiver
   SG_ DIF_statorVDFiltered m63 : 16|16@1- (4e-05,0) [-1.31072|1.31068] "mindex" Receiver
   SG_ DIF_statorVQ m36 : 16|16@1- (4e-05,0) [-1.31072|1.31068] "mindex" Receiver
   SG_ DIF_statorVQFiltered m63 : 32|16@1- (4e-05,0) [-1.31072|1.31068] "mindex" Receiver
   SG_ DIF_sysHeatPowerOptimal m50 : 16|8@1+ (0.08,0) [0|20] "kW" Receiver
   SG_ DIF_sysPedalMaxTorque m44 : 22|14@1+ (0.1,0) [0|1638.3] "Nm" Receiver
   SG_ DIF_sysPedalMinTorque m44 : 8|14@1+ (0.1,-1638.3) [-1638.3|0] "Nm" Receiver
   SG_ DIF_sysPostPedalMaxTorque m44 : 50|14@1+ (0.1,0) [0|1638.3] "Nm" Receiver
   SG_ DIF_sysPostPedalMinTorque m44 : 36|14@1+ (0.1,-1638.3) [-1638.3|0] "Nm" Receiver
   SG_ DIF_systemStack m68 : 8|8@1+ (0.4,0) [0|100] "%" Receiver
   SG_ DIF_systemTorqueCommand m35 : 48|16@1- (0.035,0) [-1146.88|1146.85] "Nm" Receiver
   SG_ DIF_tcMaxRequest m40 : 16|8@1+ (5,0) [0|1275] "Nm" Receiver
   SG_ DIF_tcMinRequest m40 : 24|8@1+ (5,0) [0|1275] "Nm" Receiver
   SG_ DIF_torquePerAmp m33 : 48|16@1+ (0.0001,0) [0|6.5535] "Nm/A" Receiver
   SG_ DIF_tqSatMotorCurrent m39 : 40|8@1+ (0.4,0) [0|102] "%" Receiver
   SG_ DIF_tqSatMotorVoltage m39 : 32|8@1+ (0.4,0) [0|102] "%" Receiver
   SG_ DIF_tqSatThermal m39 : 8|8@1+ (0.4,0) [0|102] "%" Receiver
   SG_ DIF_tqSatUiDriveTorque m40 : 32|8@1+ (0.4,0) [0|102] "%" Receiver
   SG_ DIF_tqSatUiRegenTorque m40 : 40|8@1+ (0.4,0) [0|102] "%" Receiver
   SG_ DIF_tqScaleDifferential m35 : 8|8@1+ (0.4,0) [0|102] "%" Receiver
   SG_ DIF_tqScaleMaxMotorSpeed m40 : 48|8@1+ (0.4,0) [0|102] "%" Receiver
   SG_ DIF_tqScaleShift m40 : 56|8@1+ (0.4,0) [0|102] "%" Receiver
   SG_ DIF_udsStack m68 : 40|8@1+ (0.4,0) [0|100] "%" Receiver
   SG_ DIF_usmState m38 : 12|3@1+ (1,0) [0|7] "" Receiver
   SG_ DIF_veMassInvRaw m41 : 8|12@1+ (1e-07,0.0001) [0.0001|0.0005] "1/kg" Receiver
   SG_ DIF_veResForce m41 : 20|12@1- (0.0005,0) [-1.024|1.0235] "G" Receiver
   SG_ DIF_velocityEstimatorState m65 : 8|3@1+ (1,0) [0|4] "" Receiver
   SG_ DIF_wasteCurrentLimit m41 : 48|16@1+ (0.1,0) [0|6553.5] "A" Receiver
   SG_ DIF_xcpStack m68 : 48|8@1+ (0.4,0) [0|100] "%" Receiver

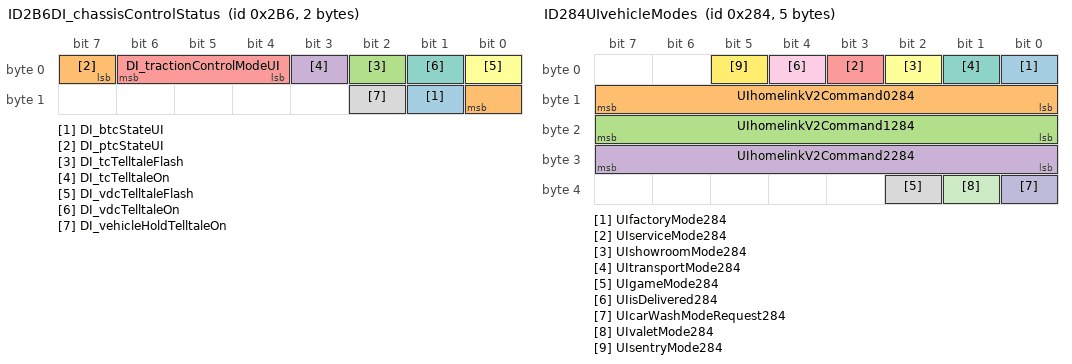
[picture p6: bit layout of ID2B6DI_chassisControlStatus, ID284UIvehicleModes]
BO_ 694 ID2B6DI_chassisControlStatus: 2 VehicleBus
   SG_ DI_btcStateUI : 9|1@1+ (1,0) [0|1] "" Receiver
   SG_ DI_ptcStateUI : 7|2@1+ (1,0) [0|3] "" Receiver
   SG_ DI_tcTelltaleFlash : 2|1@1+ (1,0) [0|1] "" Receiver
   SG_ DI_tcTelltaleOn : 3|1@1+ (1,0) [0|1] "" Receiver
   SG_ DI_tractionControlModeUI : 4|3@1+ (1,0) [0|6] "" Receiver
   SG_ DI_vdcTelltaleFlash : 0|1@1+ (1,0) [0|1] "" Receiver
   SG_ DI_vdcTelltaleOn : 1|1@1+ (1,0) [0|1] "" Receiver
   SG_ DI_vehicleHoldTelltaleOn : 10|1@1+ (1,0) [0|1] "" Receiver

BO_ 644 ID284UIvehicleModes: 5 VehicleBus
   SG_ UIfactoryMode284 : 0|1@1+ (1,0) [0|0] "" Receiver
   SG_ UIhomelinkV2Command0284 : 8|8@1+ (1,0) [0|0] "" Receiver
   SG_ UIhomelinkV2Command1284 : 16|8@1+ (1,0) [0|0] "" Receiver
   SG_ UIhomelinkV2Command2284 : 24|8@1+ (1,0) [0|0] "" Receiver
   SG_ UIserviceMode284 : 3|1@1+ (1,0) [0|0] "" Receiver
   SG_ UIshowroomMode284 : 2|1@1+ (1,0) [0|0] "" Receiver
   SG_ UItransportMode284 : 1|1@1+ (1,0) [0|0] "" Receiver
   SG_ UIgameMode284 : 34|1@1+ (1,0) [0|0] "" Receiver
   SG_ UIisDelivered284 : 4|1@1+ (1,0) [0|0] "" Receiver
   SG_ UIcarWashModeRequest284 : 32|1@1+ (1,0) [0|0] "" Receiver
   SG_ UIvaletMode284 : 33|1@1+ (1,0) [0|0] "" Receiver
   SG_ UIsentryMode284 : 5|1@1+ (1,0) [0|0] "" Receiver

BO_ 545 ID221VCFRONT_LVPowerState: 8 VehicleBus
   SG_ VCFRONT_LVPowerStateIndex M : 0|5@1+ (1,0) [0|1] "" Receiver
   SG_ VCFRONT_CMPDLVState m1 : 18|2@1+ (1,0) [0|3] "" Receiver
   SG_ VCFRONT_amplifierLVRequest m0 : 28|2@1+ (1,0) [0|3] "" Receiver
   SG_ VCFRONT_cpLVRequest m1 : 8|2@1+ (1,0) [0|3] "" Receiver
   SG_ VCFRONT_das1HighCurrentLVState m0 : 30|2@1+ (1,0) [0|3] "" Receiver
   SG_ VCFRONT_das2HighCurrentLVState m0 : 32|2@1+ (1,0) [0|3] "" Receiver
   SG_ VCFRONT_difLVState m0 : 36|2@1+ (1,0) [0|3] "" Receiver
   SG_ VCFRONT_dirLVRequest m0 : 34|2@1+ (1,0) [0|3] "" Receiver
   SG_ VCFRONT_epasLVState m1 : 10|2@1+ (1,0) [0|3] "" Receiver
   SG_ VCFRONT_espLVState m0 : 10|2@1+ (1,0) [0|3] "" Receiver
   SG_ VCFRONT_hvacCompLVState m0 : 14|2@1+ (1,0) [0|3] "" Receiver
   SG_ VCFRONT_hvcLVRequest m1 : 12|2@1+ (1,0) [0|3] "" Receiver
   SG_ VCFRONT_iBoosterLVState m0 : 24|2@1+ (1,0) [0|3] "" Receiver
   SG_ VCFRONT_ocsLVRequest m0 : 42|2@1+ (1,0) [0|3] "" Receiver
   SG_ VCFRONT_oilPumpFrontLVState m0 : 38|2@1+ (1,0) [0|3] "" Receiver
   SG_ VCFRONT_oilPumpRearLVRequest m0 : 40|2@1+ (1,0) [0|3] "" Receiver
   SG_ VCFRONT_parkLVState m0 : 8|2@1+ (1,0) [0|3] "" Receiver
   SG_ VCFRONT_pcsLVState m1 : 16|2@1+ (1,0) [0|3] "" Receiver
   SG_ VCFRONT_ptcLVRequest m0 : 16|2@1+ (1,0) [0|3] "" Receiver
   SG_ VCFRONT_radcLVState m0 : 12|2@1+ (1,0) [0|3] "" Receiver
   SG_ VCFRONT_rcmLVRequest m0 : 22|2@1+ (1,0) [0|3] "" Receiver
   SG_ VCFRONT_sccmLVRequest m0 : 18|2@1+ (1,0) [0|3] "" Receiver
   SG_ VCFRONT_tasLVState m1 : 14|2@1+ (1,0) [0|3] "" Receiver
   SG_ VCFRONT_tpmsLVRequest m0 : 20|2@1+ (1,0) [0|3] "" Receiver
   SG_ VCFRONT_tunerLVRequest m0 : 26|2@1+ (1,0) [0|3] "" Receiver
   SG_ VCFRONT_uiHiCurrentLVState m0 : 48|2@1+ (1,0) [0|3] "" Receiver
   SG_ VCFRONT_vcleftHiCurrentLVState m0 : 44|2@1+ (1,0) [0|3] "" Receiver
   SG_ VCFRONT_vcrightHiCurrentLVState m0 : 46|2@1+ (1,0) [0|3] "" Receiver

BO_ 753 ID2F1VCFRONT_eFuseDebugStatus: 8 VehicleBus
   SG_ VCFRONT_eFuseDebugStatusIndex M : 0|5@1+ (1,0) [0|18] "" Receiver
   SG_ VCFRONT_ChargePumpVoltage m16 : 24|16@1+ (0.00544368,0) [0|356.751] "V" Receiver
   SG_ VCFRONT_EPAS3PCurrent m4 : 47|16@1+ (0.1,0) [0|6553.5] "A" Receiver
   SG_ VCFRONT_EPAS3PFault m4 : 10|1@1+ (1,0) [0|1] "" Receiver
   SG_ VCFRONT_EPAS3PSelfTestResult m4 : 11|4@1+ (1,0) [0|11] "" Receiver
   SG_ VCFRONT_EPAS3PState m4 : 8|2@1+ (1,0) [0|2] "" Receiver
   SG_ VCFRONT_EPAS3PTemp m4 : 15|11@1+ (0.125,-40) [-40|150] "C" Receiver
   SG_ VCFRONT_EPAS3PVoltage m4 : 31|16@1+ (0.1,0) [0|6553.5] "V" Receiver
   SG_ VCFRONT_EPAS3SCurrent m5 : 47|16@1+ (0.1,0) [0|6553.5] "A" Receiver
   SG_ VCFRONT_EPAS3SFault m5 : 10|1@1+ (1,0) [0|1] "" Receiver
   SG_ VCFRONT_EPAS3SSelfTestResult m5 : 11|4@1+ (1,0) [0|11] "" Receiver
   SG_ VCFRONT_EPAS3SState m5 : 8|2@1+ (1,0) [0|2] "" Receiver
   SG_ VCFRONT_EPAS3STemp m5 : 15|11@1+ (0.125,-40) [-40|150] "C" Receiver
   SG_ VCFRONT_EPAS3SVoltage m5 : 31|16@1+ (0.1,0) [0|6553.5] "V" Receiver
   SG_ VCFRONT_ESPMotorCurrent m6 : 47|16@1+ (0.1,0) [0|6553.5] "A" Receiver
   SG_ VCFRONT_ESPMotorFault m6 : 10|1@1+ (1,0) [0|1] "" Receiver
   SG_ VCFRONT_ESPMotorSelfTestResult m6 : 11|4@1+ (1,0) [0|11] "" Receiver
   SG_ VCFRONT_ESPMotorState m6 : 8|2@1+ (1,0) [0|2] "" Receiver
   SG_ VCFRONT_ESPMotorTemp m6 : 15|11@1+ (0.125,-40) [-40|150] "C" Receiver
   SG_ VCFRONT_ESPMotorVoltage m6 : 31|16@1+ (0.1,0) [0|6553.5] "V" Receiver
   SG_ VCFRONT_ESPValveCurrent m7 : 44|16@1+ (0.1,0) [0|6553.5] "A" Receiver
   SG_ VCFRONT_ESPValveFault m7 : 10|1@1+ (1,0) [0|1] "" Receiver
   SG_ VCFRONT_ESPValveState m7 : 8|2@1+ (1,0) [0|2] "" Receiver
   SG_ VCFRONT_ESPValveTemp m7 : 12|11@1+ (0.125,-40) [-40|150] "C" Receiver
   SG_ VCFRONT_ESPValveVoltage m7 : 28|16@1+ (0.1,0) [0|6553.5] "V" Receiver
   SG_ VCFRONT_IBSUnfilteredTemperature m17 : 40|16@1- (0.01,0) [-327.68|327.67] "C" Receiver
   SG_ VCFRONT_PCSCurrent m2 : 47|16@1- (0.1,0) [-3276.8|3276.7] "A" Receiver
   SG_ VCFRONT_PCSFault m2 : 10|1@1+ (1,0) [0|1] "" Receiver
   SG_ VCFRONT_PCSState m2 : 8|2@1+ (1,0) [0|2] "" Receiver
   SG_ VCFRONT_PCSTemp m2 : 15|11@1+ (0.125,-40) [-40|150] "C" Receiver
   SG_ VCFRONT_PCSVoltage m2 : 31|16@1+ (0.1,0) [0|6553.5] "V" Receiver
   SG_ VCFRONT_autopilot1Current m8 : 43|16@1+ (0.1,0) [0|6553.5] "A" Receiver
   SG_ VCFRONT_autopilot1Fault m8 : 10|1@1+ (1,0) [0|1] "" Receiver
   SG_ VCFRONT_autopilot1State m8 : 8|2@1+ (1,0) [0|2] "" Receiver
   SG_ VCFRONT_autopilot1Temp m8 : 11|11@1+ (0.125,-40) [-40|150] "C" Receiver
   SG_ VCFRONT_autopilot1Voltage m8 : 27|16@1+ (0.1,0) [0|6553.5] "V" Receiver
   SG_ VCFRONT_autopilot2Current m9 : 43|16@1+ (0.1,0) [0|6553.5] "A" Receiver
   SG_ VCFRONT_autopilot2Fault m9 : 10|1@1+ (1,0) [0|1] "" Receiver
   SG_ VCFRONT_autopilot2State m9 : 8|2@1+ (1,0) [0|2] "" Receiver
   SG_ VCFRONT_autopilot2Temp m9 : 11|11@1+ (0.125,-40) [-40|150] "C" Receiver
   SG_ VCFRONT_autopilot2Voltage m9 : 27|16@1+ (0.1,0) [0|6553.5] "V" Receiver
   SG_ VCFRONT_chargedIBSAmpHours m17 : 8|16@1+ (1,0) [0|65535] "Ah" Receiver
   SG_ VCFRONT_dischargedIBSAmpHours m17 : 24|16@1+ (1,0) [0|65535] "Ah" Receiver
   SG_ VCFRONT_eFuseLockoutVoltage m16 : 8|12@1+ (0.00544368,0) [0|22.2919] "V" Receiver
   SG_ VCFRONT_headlampLeftCurrent m12 : 10|10@1+ (0.1,0) [0|102.3] "A" Receiver
   SG_ VCFRONT_headlampLeftFault m12 : 9|1@1+ (1,0) [0|1] "" Receiver
   SG_ VCFRONT_headlampLeftState m12 : 8|1@1+ (1,0) [0|1] "" Receiver
   SG_ VCFRONT_headlampLeftTemperature m12 : 48|8@1- (1,-40) [-40|150] "C" Receiver
   SG_ VCFRONT_headlampLeftVoltage m12 : 20|8@1+ (0.1,0) [0|25.4] "V" Receiver
   SG_ VCFRONT_headlampRightCurrent m12 : 30|10@1+ (0.1,0) [0|102.3] "A" Receiver
   SG_ VCFRONT_headlampRightFault m12 : 29|1@1+ (1,0) [0|1] "" Receiver
   SG_ VCFRONT_headlampRightState m12 : 28|1@1+ (1,0) [0|1] "" Receiver
   SG_ VCFRONT_headlampRightTemperature m12 : 56|8@1- (1,-40) [-40|150] "C" Receiver
   SG_ VCFRONT_headlampRightVoltage m12 : 40|8@1+ (0.1,0) [0|25.4] "V" Receiver
   SG_ VCFRONT_iBoosterCurrent m3 : 47|16@1+ (0.1,0) [0|6553.5] "A" Receiver
   SG_ VCFRONT_iBoosterFault m3 : 10|1@1+ (1,0) [0|1] "" Receiver
   SG_ VCFRONT_iBoosterSelfTestResult m3 : 11|4@1+ (1,0) [0|11] "" Receiver
   SG_ VCFRONT_iBoosterState m3 : 8|2@1+ (1,0) [0|2] "" Receiver
   SG_ VCFRONT_iBoosterTemp m3 : 15|11@1+ (0.125,-40) [-40|150] "C" Receiver
   SG_ VCFRONT_iBoosterVoltage m3 : 31|16@1+ (0.1,0) [0|6553.5] "V" Receiver
   SG_ VCFRONT_leftControllerCurrent m1 : 47|16@1+ (0.1,0) [0|6553.5] "A" Receiver
   SG_ VCFRONT_leftControllerFault m1 : 10|1@1+ (1,0) [0|1] "" Receiver
   SG_ VCFRONT_leftControllerState m1 : 8|2@1+ (1,0) [0|2] "" Receiver
   SG_ VCFRONT_leftControllerTemp m1 : 15|11@1+ (0.125,-40) [-40|150] "C" Receiver
   SG_ VCFRONT_leftControllerVoltage m1 : 31|16@1+ (0.1,0) [0|6553.5] "V" Receiver
   SG_ VCFRONT_pcsSelfTestResult m2 : 11|4@1+ (1,0) [0|11] "" Receiver
   SG_ VCFRONT_pump1AndFanCurrent m14 : 6|16@1+ (0.1,0) [0|6553.5] "A" Receiver
   SG_ VCFRONT_pump1AndFanState m14 : 5|1@1+ (1,0) [0|1] "" Receiver
   SG_ VCFRONT_pump1AndFanVoltage m14 : 22|12@1+ (0.1,0) [0|409.5] "V" Receiver
   SG_ VCFRONT_pump2AndAirCompCurrent m14 : 35|16@1+ (0.1,0) [0|6553.5] "A" Receiver
   SG_ VCFRONT_pump2AndAirCompState m14 : 34|1@1+ (1,0) [0|1] "" Receiver
   SG_ VCFRONT_pump2AndAirCompVoltage m14 : 51|12@1+ (0.1,0) [0|409.5] "V" Receiver
   SG_ VCFRONT_railA_12v m15 : 8|12@1+ (0.00544368,0) [0|22.2919] "V" Receiver
   SG_ VCFRONT_railA_5v m15 : 32|12@1+ (0.00544368,0) [0|22.2919] "V" Receiver
   SG_ VCFRONT_railB_12v m15 : 20|12@1+ (0.00544368,0) [0|22.2919] "V" Receiver
   SG_ VCFRONT_railB_5v m15 : 44|12@1+ (0.00544368,0) [0|22.2919] "V" Receiver
   SG_ VCFRONT_rightControllerCurrent m0 : 47|16@1+ (0.1,0) [0|6553.5] "A" Receiver
   SG_ VCFRONT_rightControllerFault m0 : 10|1@1+ (1,0) [0|1] "" Receiver
   SG_ VCFRONT_rightControllerState m0 : 8|2@1+ (1,0) [0|2] "" Receiver
   SG_ VCFRONT_rightControllerTemp m0 : 15|11@1+ (0.125,-40) [-40|150] "C" Receiver
   SG_ VCFRONT_rightControllerVoltage m0 : 31|16@1+ (0.1,0) [0|6553.5] "V" Receiver
   SG_ VCFRONT_sleepBypassCurrent m10 : 26|16@1+ (0.1,0) [0|6553.5] "A" Receiver
   SG_ VCFRONT_sleepBypassFault m10 : 9|1@1+ (1,0) [0|1] "" Receiver
   SG_ VCFRONT_sleepBypassState m10 : 8|1@1+ (1,0) [0|1] "" Receiver
   SG_ VCFRONT_sleepBypassVoltage m10 : 10|16@1+ (0.1,0) [0|6553.5] "V" Receiver
   SG_ VCFRONT_uiAudioCurrent m11 : 8|16@1+ (0.1,0) [0|6553.5] "A" Receiver
   SG_ VCFRONT_uiAudioFault m11 : 6|1@1+ (1,0) [0|1] "" Receiver
   SG_ VCFRONT_uiAudioState m11 : 5|1@1+ (1,0) [0|1] "" Receiver
   SG_ VCFRONT_uiCurrent m11 : 32|16@1+ (0.1,0) [0|6553.5] "A" Receiver
   SG_ VCFRONT_uiFault m11 : 25|1@1+ (1,0) [0|1] "" Receiver
   SG_ VCFRONT_uiState m11 : 24|1@1+ (1,0) [0|1] "" Receiver
   SG_ VCFRONT_vbatFusedHighCurrent m13 : 46|16@1+ (0.1,0) [0|6553.5] "A" Receiver
   SG_ VCFRONT_vbatFusedHighFault m13 : 9|1@1+ (1,0) [0|1] "" Receiver
   SG_ VCFRONT_vbatFusedHighState m13 : 8|1@1+ (1,0) [0|1] "" Receiver
   SG_ VCFRONT_vbatFusedHighTemp m13 : 14|11@1+ (0.125,-40) [-40|150] "C" Receiver
   SG_ VCFRONT_vbatFusedHighVoltage m13 : 30|16@1+ (0.1,0) [0|6553.5] "V" Receiver
   SG_ VCFRONT_vbatFusedSelfTestResult m13 : 10|4@1+ (1,0) [0|11] "" Receiver
   SG_ VCFRONT_vcleftSelfTestResult m1 : 11|4@1+ (1,0) [0|11] "" Receiver
   SG_ VCFRONT_vcrightSelfTestResult m0 : 11|4@1+ (1,0) [0|11] "" Receiver

BO_ 579 ID243VCRIGHT_hvacStatus: 8 VehicleBus
   SG_ VCRIGHT_hvacStatusIndex M : 0|2@1+ (1,0) [0|3] "" Receiver
   SG_ VCRIGHT_hvacACRunning m0 : 50|1@1+ (1,0) [0|1] "" Receiver
   SG_ VCRIGHT_hvacAirDistributionMode m0 : 41|3@1+ (1,0) [0|7] "" Receiver
   SG_ VCRIGHT_hvacBlowerSegment m0 : 44|4@1+ (1,0) [0|11] "" Receiver
   SG_ VCRIGHT_hvacCabinTempEst m0 : 30|11@1+ (0.1,-40) [-40|164] "C" Receiver
   SG_ VCRIGHT_hvacDuctTargetLeft m1 : 48|8@1+ (0.5,-40) [-40|80] "C" Receiver
   SG_ VCRIGHT_hvacDuctTargetRight m1 : 56|8@1+ (0.5,-40) [-40|80] "C" Receiver
   SG_ VCRIGHT_hvacMassflowRefrigSystem m1 : 2|8@1+ (1,0) [0|250] "g/s" Receiver
   SG_ VCRIGHT_hvacModelInitStatus m0 : 60|3@1+ (1,0) [0|5] "" Receiver
   SG_ VCRIGHT_hvacOverheatProtActive m0 : 63|1@1+ (1,0) [0|1] "" Receiver
   SG_ VCRIGHT_hvacPowerState m0 : 51|3@1+ (1,0) [0|4] "" Receiver
   SG_ VCRIGHT_hvacQdotLeft m0 : 2|14@1+ (1,-8191) [-8191|8191] "W" Receiver
   SG_ VCRIGHT_hvacQdotRight m0 : 16|14@1+ (1,-8191) [-8191|8191] "W" Receiver
   SG_ VCRIGHT_hvacRecirc m0 : 48|2@1+ (1,0) [0|2] "" Receiver
   SG_ VCRIGHT_hvacRecircDoorPercent m1 : 10|6@1+ (1.6,0) [0|100] "%" Receiver
   SG_ VCRIGHT_hvacSecondRowState m0 : 56|3@1+ (1,0) [0|4] "" Receiver
   SG_ VCRIGHT_hvacSystemNominal m0 : 59|1@1+ (1,0) [0|1] "" Receiver
   SG_ VCRIGHT_hvacVentStatus m0 : 54|2@1+ (1,0) [0|2] "" Receiver
   SG_ VCRIGHT_tempDuctLeft m1 : 16|8@1+ (0.5,-22) [-22|105] "C" Receiver
   SG_ VCRIGHT_tempDuctLeftLower m1 : 24|8@1+ (0.5,-22) [-22|105] "C" Receiver
   SG_ VCRIGHT_tempDuctLeftUpper m2 : 2|8@1+ (0.5,-22) [-22|105] "C" Receiver
   SG_ VCRIGHT_tempDuctRight m1 : 32|8@1+ (0.5,-22) [-22|105] "C" Receiver
   SG_ VCRIGHT_tempDuctRightLower m1 : 40|8@1+ (0.5,-22) [-22|105] "C" Receiver
   SG_ VCRIGHT_tempDuctRightUpper m2 : 10|8@1+ (0.5,-22) [-22|105] "C" Receiver

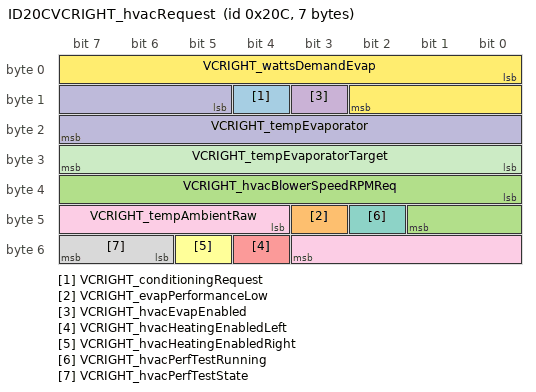
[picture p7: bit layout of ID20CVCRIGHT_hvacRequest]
BO_ 524 ID20CVCRIGHT_hvacRequest: 7 VehicleBus
   SG_ VCRIGHT_conditioningRequest : 12|1@1+ (1,0) [0|1] "" Receiver
   SG_ VCRIGHT_evapPerformanceLow : 43|1@1+ (1,0) [0|1] "" Receiver
   SG_ VCRIGHT_hvacBlowerSpeedRPMReq : 32|10@1+ (5,0) [0|5115] "RPM" Receiver
   SG_ VCRIGHT_hvacEvapEnabled : 11|1@1+ (1,0) [0|1] "" Receiver
   SG_ VCRIGHT_hvacHeatingEnabledLeft : 52|1@1+ (1,0) [0|1] "" Receiver
   SG_ VCRIGHT_hvacHeatingEnabledRight : 53|1@1+ (1,0) [0|1] "" Receiver
   SG_ VCRIGHT_hvacPerfTestRunning : 42|1@1+ (1,0) [0|1] "" Receiver
   SG_ VCRIGHT_hvacPerfTestState : 54|2@1+ (1,0) [0|2] "" Receiver
   SG_ VCRIGHT_tempAmbientRaw : 44|8@1+ (0.5,-40) [-40|80] "C" Receiver
   SG_ VCRIGHT_tempEvaporator : 13|11@1+ (0.1,-40) [-40|105] "C" Receiver
   SG_ VCRIGHT_tempEvaporatorTarget : 24|8@1+ (0.2,0) [0|50] "C" Receiver
   SG_ VCRIGHT_wattsDemandEvap : 0|11@1+ (5,0) [0|10000] "W" Receiver

BO_ 691 ID2B3VCRIGHT_logging1Hz: 8 VehicleBus
   SG_ VCRIGHT_logging1HzIndex M : 0|4@1+ (1,0) [0|11] "" Receiver
   SG_ VCRIGHT_LHPanelAirflowBlocked m3 : 54|1@1+ (1,0) [0|1] "" Receiver
   SG_ VCRIGHT_RHPanelAirflowBlocked m3 : 55|1@1+ (1,0) [0|1] "" Receiver
   SG_ VCRIGHT_cabinTempBreathLevel m1 : 56|8@1+ (0.5,-40) [-40|80] "C" Receiver
   SG_ VCRIGHT_cabinTempFanCurrent m9 : 15|6@1- (0.001,0) [-0.01|0.05] "A" Receiver
   SG_ VCRIGHT_cabinTempFanOutput m9 : 14|1@1+ (1,0) [0|1] "" Receiver
   SG_ VCRIGHT_cabinTempGlassRoof m1 : 8|8@1+ (0.5,-40) [-40|80] "C" Receiver
   SG_ VCRIGHT_cabinTempInterior m1 : 24|8@1+ (0.5,-40) [-40|80] "C" Receiver
   SG_ VCRIGHT_cabinTempInteriorL2 m0 : 24|8@1+ (0.5,-40) [-40|80] "C" Receiver
   SG_ VCRIGHT_cabinTempInteriorL3 m9 : 40|8@1+ (0.5,-40) [-40|80] "C" Receiver
   SG_ VCRIGHT_cabinTempInteriorSunny m1 : 32|8@1+ (0.6,-40) [-40|100] "C" Receiver
   SG_ VCRIGHT_cabinTempInteriorSunnyL2 m0 : 40|8@1+ (0.6,-40) [-40|100] "C" Receiver
   SG_ VCRIGHT_cabinTempInteriorSunnyL3 m9 : 48|8@1+ (0.6,-40) [-40|100] "C" Receiver
   SG_ VCRIGHT_cabinTempSideGlassLeft m1 : 40|8@1+ (0.5,-40) [-40|80] "C" Receiver
   SG_ VCRIGHT_cabinTempSideGlassRight m1 : 48|8@1+ (0.5,-40) [-40|80] "C" Receiver
   SG_ VCRIGHT_cabinTempTopPadAir m9 : 56|8@1+ (0.6,-40) [-40|100] "C" Receiver
   SG_ VCRIGHT_cabinTempWindshield m1 : 16|8@1+ (0.5,-40) [-40|80] "C" Receiver
   SG_ VCRIGHT_cloudinessEstimatedPct m9 : 33|7@1+ (1,0) [0|100] "%" Receiver
   SG_ VCRIGHT_convectionDeliveredLeft m4 : 24|8@1+ (2,-254) [-254|256] "W/m2" Receiver
   SG_ VCRIGHT_convectionDeliveredRight m4 : 32|8@1+ (2,-254) [-254|256] "W/m2" Receiver
   SG_ VCRIGHT_convectionTargetLeft m4 : 8|8@1+ (2,-254) [-254|256] "W/m2" Receiver
   SG_ VCRIGHT_convectionTargetRight m4 : 16|8@1+ (2,-254) [-254|256] "W/m2" Receiver
   SG_ VCRIGHT_defrostAirflowBlocked m3 : 57|1@1+ (1,0) [0|1] "" Receiver
   SG_ VCRIGHT_evapCondensationRate m10 : 47|9@1- (0.007,0) [-1|1] "g/s" Receiver
   SG_ VCRIGHT_evapDryingRoutineRuntime m10 : 56|5@1+ (2,0) [0|60] "min" Receiver
   SG_ VCRIGHT_evapLoadInFresh m5 : 32|8@1+ (35,0) [0|8000] "W" Receiver
   SG_ VCRIGHT_evapLoadInRecirc m5 : 40|8@1+ (35,0) [0|8000] "W" Receiver
   SG_ VCRIGHT_evapWaterMass m10 : 40|7@1+ (6,0) [0|380] "Grams" Receiver
   SG_ VCRIGHT_filterLifeBlowerTorque m9 : 4|10@1+ (0.006,-1.5) [-1.5|4.5] "Nm" Receiver
   SG_ VCRIGHT_floorAirflowBlocked m3 : 56|1@1+ (1,0) [0|1] "" Receiver
   SG_ VCRIGHT_hvacAirFlowModeRow1 m3 : 29|3@1+ (1,0) [0|7] "" Receiver
   SG_ VCRIGHT_hvacAirFlowModeRow2 m3 : 32|3@1+ (1,0) [0|7] "" Receiver
   SG_ VCRIGHT_hvacAirflowReason m3 : 48|4@1+ (1,0) [0|14] "" Receiver
   SG_ VCRIGHT_hvacAutoTransitionReason m3 : 24|5@1+ (1,0) [0|19] "" Receiver
   SG_ VCRIGHT_hvacCabOvrheatProtActive m9 : 30|1@1+ (1,0) [0|1] "" Receiver
   SG_ VCRIGHT_hvacCabOvrheatProtAllowe m9 : 32|1@1+ (1,0) [0|1] "" Receiver
   SG_ VCRIGHT_hvacCabinPurgeActive m9 : 29|1@1+ (1,0) [0|1] "" Receiver
   SG_ VCRIGHT_hvacCabinPurgeAllowed m9 : 31|1@1+ (1,0) [0|1] "" Receiver
   SG_ VCRIGHT_hvacIntakeEndStop m7 : 56|8@1+ (0.02,0) [0|5] "V" Receiver
   SG_ VCRIGHT_hvacIntakeVoltage m6 : 56|8@1+ (0.02,0) [0|5] "V" Receiver
   SG_ VCRIGHT_hvacIntakeZeroStop m8 : 56|8@1+ (0.02,0) [0|5] "V" Receiver
   SG_ VCRIGHT_hvacLHBleedEndStop m7 : 8|8@1+ (0.02,0) [0|5] "V" Receiver
   SG_ VCRIGHT_hvacLHBleedVoltage m6 : 8|8@1+ (0.02,0) [0|5] "V" Receiver
   SG_ VCRIGHT_hvacLHBleedZeroStop m8 : 8|8@1+ (0.02,0) [0|5] "V" Receiver
   SG_ VCRIGHT_hvacLHVaneEndStop m7 : 24|8@1+ (0.02,0) [0|5] "V" Receiver
   SG_ VCRIGHT_hvacLHVaneVoltage m6 : 24|8@1+ (0.02,0) [0|5] "V" Receiver
   SG_ VCRIGHT_hvacLHVaneZeroStop m8 : 24|8@1+ (0.02,0) [0|5] "V" Receiver
   SG_ VCRIGHT_hvacLowerModeEndStop m7 : 48|8@1+ (0.02,0) [0|5] "V" Receiver
   SG_ VCRIGHT_hvacLowerModeVoltage m6 : 48|8@1+ (0.02,0) [0|5] "V" Receiver
   SG_ VCRIGHT_hvacLowerModeZeroStop m8 : 48|8@1+ (0.02,0) [0|5] "V" Receiver
   SG_ VCRIGHT_hvacMassflowTarget m3 : 40|8@1+ (1,0) [0|200] "g/s" Receiver
   SG_ VCRIGHT_hvacQdotFeedforward m5 : 16|16@1+ (1,-32767) [-32767|32767] "W" Receiver
   SG_ VCRIGHT_hvacQdotLimitedLeft m3 : 52|1@1+ (1,0) [0|1] "" Receiver
   SG_ VCRIGHT_hvacQdotLimitedRight m3 : 53|1@1+ (1,0) [0|1] "" Receiver
   SG_ VCRIGHT_hvacRHBleedEndStop m7 : 16|8@1+ (0.02,0) [0|5] "V" Receiver
   SG_ VCRIGHT_hvacRHBleedVoltage m6 : 16|8@1+ (0.02,0) [0|5] "V" Receiver
   SG_ VCRIGHT_hvacRHBleedZeroStop m8 : 16|8@1+ (0.02,0) [0|5] "V" Receiver
   SG_ VCRIGHT_hvacRHVaneEndStop m7 : 32|8@1+ (0.02,0) [0|5] "V" Receiver
   SG_ VCRIGHT_hvacRHVaneVoltage m6 : 32|8@1+ (0.02,0) [0|5] "V" Receiver
   SG_ VCRIGHT_hvacRHVaneZeroStop m8 : 32|8@1+ (0.02,0) [0|5] "V" Receiver
   SG_ VCRIGHT_hvacSetTempActualLeft m3 : 8|8@1+ (0.1,15) [15|28] "C" Receiver
   SG_ VCRIGHT_hvacSetTempActualRight m3 : 16|8@1+ (0.1,15) [15|28] "C" Receiver
   SG_ VCRIGHT_hvacUpperModeEndStop m7 : 40|8@1+ (0.02,0) [0|5] "V" Receiver
   SG_ VCRIGHT_hvacUpperModeVoltage m6 : 40|8@1+ (0.02,0) [0|5] "V" Receiver
   SG_ VCRIGHT_hvacUpperModeZeroStop m8 : 40|8@1+ (0.02,0) [0|5] "V" Receiver
   SG_ VCRIGHT_leftHeatOvertempProtect m10 : 61|1@1+ (1,0) [0|1] "" Receiver
   SG_ VCRIGHT_pcbaTemperature m2 : 4|11@1+ (0.125,-40) [-40|150] "C" Receiver
   SG_ VCRIGHT_ptcHeaterHvacActNotReady m5 : 7|1@1+ (1,0) [0|1] "" Receiver
   SG_ VCRIGHT_ptcHeaterLAirPathBlocked m5 : 10|1@1+ (1,0) [0|1] "" Receiver
   SG_ VCRIGHT_ptcHeaterNoAirflow m5 : 6|1@1+ (1,0) [0|1] "" Receiver
   SG_ VCRIGHT_ptcHeaterNoHighVoltage m5 : 9|1@1+ (1,0) [0|1] "" Receiver
   SG_ VCRIGHT_ptcHeaterNoUiRequest m5 : 8|1@1+ (1,0) [0|1] "" Receiver
   SG_ VCRIGHT_ptcHeaterPwrDemandLeft m2 : 40|8@1+ (20,0) [0|5000] "W" Receiver
   SG_ VCRIGHT_ptcHeaterPwrDemandRight m2 : 48|8@1+ (20,0) [0|5000] "W" Receiver
   SG_ VCRIGHT_ptcHeaterRAirPathBlocked m5 : 11|1@1+ (1,0) [0|1] "" Receiver
   SG_ VCRIGHT_ptcHeaterReqAirpathBlock m5 : 12|1@1+ (1,0) [0|1] "" Receiver
   SG_ VCRIGHT_ptcHeaterTempDuctFault m5 : 5|1@1+ (1,0) [0|1] "" Receiver
   SG_ VCRIGHT_ptcHeaterTempDuctHigh m5 : 4|1@1+ (1,0) [0|1] "" Receiver
   SG_ VCRIGHT_rightHeatOvertempProtect m10 : 62|1@1+ (1,0) [0|1] "" Receiver
   SG_ VCRIGHT_solarLoadLeftOccupant m4 : 48|7@1+ (2,0) [0|254] "W/m2" Receiver
   SG_ VCRIGHT_solarLoadOnVehFiltered m9 : 21|8@1+ (4,0) [0|1020] "W/m2" Receiver
   SG_ VCRIGHT_solarLoadOnVehicle m4 : 56|8@1+ (4,0) [0|1020] "W/m2" Receiver
   SG_ VCRIGHT_solarLoadRightOccupant m4 : 40|7@1+ (2,0) [0|254] "W/m2" Receiver
   SG_ VCRIGHT_tempDuctModeledLeft m10 : 4|9@1+ (0.3,-40) [-40|105] "C" Receiver
   SG_ VCRIGHT_tempDuctModeledRight m10 : 13|9@1+ (0.3,-40) [-40|105] "C" Receiver
   SG_ VCRIGHT_tempHtrSurfaceModeledL m10 : 22|9@1+ (0.3,-40) [-40|105] "C" Receiver
   SG_ VCRIGHT_tempHtrSurfaceModeledR m10 : 31|9@1+ (0.3,-40) [-40|105] "C" Receiver
   SG_ VCRIGHT_tempIncarCabinDeep m0 : 16|8@1+ (0.5,-40) [-40|85] "C" Receiver
   SG_ VCRIGHT_tempIncarCabinMid m0 : 32|8@1+ (0.5,-40) [-40|85] "C" Receiver
   SG_ VCRIGHT_tempIncarCabinProbe m0 : 8|8@1+ (0.5,-40) [-40|85] "C" Receiver
   SG_ VCRIGHT_wattsHeaterLeftTotal m2 : 16|10@1+ (5,0) [0|4000] "W" Receiver
   SG_ VCRIGHT_wattsHeaterRightTotal m2 : 26|10@1+ (5,0) [0|4000] "W" Receiver

BO_ 705 ID2C1VCFront10hz: 8 VehicleBus
   SG_ VCFRONT_logging10HzIndex M : 0|3@1+ (1,0) [0|7] "" Receiver
   SG_ VCFRONT_activeLouverAbnormalKT m4 : 3|1@1+ (1,0) [0|1] "" Receiver
   SG_ VCFRONT_activeLouverCalibRange m4 : 53|8@1+ (1,630) [630|880] "ticks" Receiver
   SG_ VCFRONT_activeLouverCommSuccess m4 : 63|1@1+ (1,0) [0|1] "" Receiver
   SG_ VCFRONT_activeLouverDemand m4 : 32|7@1+ (1,0) [0|100] "%" Receiver
   SG_ VCFRONT_activeLouverDisconnect m4 : 6|1@1+ (1,0) [0|1] "" Receiver
   SG_ VCFRONT_activeLouverFalsStallCal m4 : 62|1@1+ (1,0) [0|1] "" Receiver
   SG_ VCFRONT_activeLouverFalsStallRun m4 : 61|1@1+ (1,0) [0|1] "" Receiver
   SG_ VCFRONT_activeLouverIsCalibrated m4 : 15|1@1+ (1,0) [0|1] "" Receiver
   SG_ VCFRONT_activeLouverMotorCounts m4 : 16|11@1+ (1,-100) [-100|1900] "ticks" Receiver
   SG_ VCFRONT_activeLouverMotorState m4 : 8|3@1+ (1,0) [0|7] "" Receiver
   SG_ VCFRONT_activeLouverOverCurrent m4 : 4|1@1+ (1,0) [0|1] "" Receiver
   SG_ VCFRONT_activeLouverOverTemp m4 : 5|1@1+ (1,0) [0|1] "" Receiver
   SG_ VCFRONT_activeLouverStallCounter m4 : 40|3@1+ (1,0) [0|7] "" Receiver
   SG_ VCFRONT_activeLouverStallLength m4 : 43|10@1+ (1,0) [0|1000] "ticks" Receiver
   SG_ VCFRONT_activeLouverStalled m4 : 7|1@1+ (1,0) [0|1] "" Receiver
   SG_ VCFRONT_activeLouverState m4 : 11|4@1+ (1,0) [0|8] "" Receiver
   SG_ VCFRONT_compLimitDeadband m3 : 8|1@1+ (1,0) [0|1] "" Receiver
   SG_ VCFRONT_compLimitNvh m3 : 6|1@1+ (1,0) [0|1] "" Receiver
   SG_ VCFRONT_compLimitPresDischargeHi m3 : 3|1@1+ (1,0) [0|1] "" Receiver
   SG_ VCFRONT_compLimitScrollSepRamp m3 : 7|1@1+ (1,0) [0|1] "" Receiver
   SG_ VCFRONT_compLimitScrollSepRegion m3 : 5|1@1+ (1,0) [0|1] "" Receiver
   SG_ VCFRONT_compLimitTempDischargeHi m3 : 4|1@1+ (1,0) [0|1] "" Receiver
   SG_ VCFRONT_compLimitTempDischargeSi m3 : 19|1@1+ (1,0) [0|1] "" Receiver
   SG_ VCFRONT_compRampRateUpMax m3 : 20|6@1+ (0.1,0) [0|6] "%/s" Receiver
   SG_ VCFRONT_compStandbyCoastDownMode m3 : 15|1@1+ (1,0) [0|1] "" Receiver
   SG_ VCFRONT_compStandbyCommunication m3 : 10|1@1+ (1,0) [0|1] "" Receiver
   SG_ VCFRONT_compStandbyHVNotReady m3 : 11|1@1+ (1,0) [0|1] "" Receiver
   SG_ VCFRONT_compStandbyHighSuctionSu m3 : 16|1@1+ (1,0) [0|1] "" Receiver
   SG_ VCFRONT_compStandbyLowAmbient m3 : 12|1@1+ (1,0) [0|1] "" Receiver
   SG_ VCFRONT_compStandbyLowDischPress m3 : 13|1@1+ (1,0) [0|1] "" Receiver
   SG_ VCFRONT_compStandbyMultiplePdCut m3 : 17|1@1+ (1,0) [0|1] "" Receiver
   SG_ VCFRONT_compStandbyRefrigNotOk m3 : 14|1@1+ (1,0) [0|1] "" Receiver
   SG_ VCFRONT_compStandbySelfNotReady m3 : 9|1@1+ (1,0) [0|1] "" Receiver
   SG_ VCFRONT_compStandbyShowroomMode m3 : 18|1@1+ (1,0) [0|1] "" Receiver
   SG_ VCFRONT_coolantFlowAmbSourceActu m0 : 48|8@1+ (0.1,0) [0|25] "LPM" Receiver
   SG_ VCFRONT_coolantFlowAmbSourceTarg m0 : 56|8@1+ (0.1,0) [0|25] "LPM" Receiver
   SG_ VCFRONT_coolantTempBasedMode m2 : 3|2@1+ (1,0) [0|3] "" Receiver
   SG_ VCFRONT_coolantValveAngleActual m2 : 8|11@1+ (0.25,-100) [-100|410] "deg" Receiver
   SG_ VCFRONT_coolantValveAngleTarget m2 : 19|10@1+ (0.25,-5) [-5|245] "deg" Receiver
   SG_ VCFRONT_coolantValveAngleTravel m2 : 40|10@1+ (5,0) [0|5000] "deg" Receiver
   SG_ VCFRONT_coolantValveDuty m2 : 32|8@1- (1,0) [-100|100] "%" Receiver
   SG_ VCFRONT_coolantValveISense m2 : 56|7@1+ (0.01,0) [0|1.2] "A" Receiver
   SG_ VCFRONT_coolantValveModeWrong m2 : 5|1@1+ (1,0) [0|1] "" Receiver
   SG_ VCFRONT_coolantValveState m2 : 29|2@1+ (1,0) [0|3] "" Receiver
   SG_ VCFRONT_exvFlow m3 : 32|10@1+ (0.1,0) [0|100] "%" Receiver
   SG_ VCFRONT_exvIsFlooding m3 : 42|1@1+ (1,0) [0|1] "" Receiver
   SG_ VCFRONT_exvMotorState m3 : 28|4@1+ (1,0) [0|10] "" Receiver
   SG_ VCFRONT_exvPrechillActive m3 : 43|1@1+ (1,0) [0|1] "" Receiver
   SG_ VCFRONT_pumpBatSpiError m0 : 46|1@1+ (1,0) [0|1] "" Receiver
   SG_ VCFRONT_pumpBatteryEnabled m0 : 41|1@1+ (1,0) [0|1] "" Receiver
   SG_ VCFRONT_pumpBatteryInitd m0 : 39|1@1+ (1,0) [0|1] "" Receiver
   SG_ VCFRONT_pumpBatteryOutVoltage m0 : 24|7@1+ (0.2,0) [0|20] "V" Receiver
   SG_ VCFRONT_pumpBatteryPowerOn m0 : 43|1@1+ (1,0) [0|1] "" Receiver
   SG_ VCFRONT_pumpBatteryRPMTarget m0 : 3|10@1+ (10,0) [0|10000] "rpm" Receiver
   SG_ VCFRONT_pumpPowertrainEnabled m0 : 42|1@1+ (1,0) [0|1] "" Receiver
   SG_ VCFRONT_pumpPowertrainInitd m0 : 40|1@1+ (1,0) [0|1] "" Receiver
   SG_ VCFRONT_pumpPowertrainOutVoltage m0 : 32|7@1+ (0.2,0) [0|20] "V" Receiver
   SG_ VCFRONT_pumpPowertrainPowerOn m0 : 44|1@1+ (1,0) [0|1] "" Receiver
   SG_ VCFRONT_pumpPowertrainRPMTarget m0 : 13|10@1+ (10,0) [0|10000] "rpm" Receiver
   SG_ VCFRONT_pumpPtSpiError m0 : 47|1@1+ (1,0) [0|1] "" Receiver
   SG_ VCFRONT_pumpsWake m0 : 45|1@1+ (1,0) [0|1] "" Receiver
   SG_ VCFRONT_radarHeaterCurrent m6 : 8|8@1+ (0.1,0) [0|25.5] "A" Receiver
   SG_ VCFRONT_radarHeaterDuty m6 : 16|7@1+ (1,0) [0|100] "%" Receiver
   SG_ VCFRONT_radarHeaterTargetVoltage m6 : 24|8@1+ (0.1,0) [0|16] "V" Receiver
   SG_ VCFRONT_radiatorFanDemandLimit m1 : 48|7@1+ (1,0) [0|100] "%" Receiver
   SG_ VCFRONT_radiatorFanDemandLimited m1 : 47|1@1+ (1,0) [0|1] "" Receiver
   SG_ VCFRONT_radiatorFanEnabled m1 : 27|1@1+ (1,0) [0|1] "" Receiver
   SG_ VCFRONT_radiatorFanInitd m1 : 26|1@1+ (1,0) [0|1] "" Receiver
   SG_ VCFRONT_radiatorFanOutVoltage m1 : 8|7@1+ (0.2,0) [0|20] "V" Receiver
   SG_ VCFRONT_radiatorFanPhaseCurrent m1 : 32|8@1+ (0.25,-10) [-10|50] "A" Receiver
   SG_ VCFRONT_radiatorFanPhaseIMax m1 : 40|7@1+ (0.25,0) [5|35] "A" Receiver
   SG_ VCFRONT_radiatorFanPowerOn m1 : 28|1@1+ (1,0) [0|1] "" Receiver
   SG_ VCFRONT_radiatorFanRPMTarget m1 : 16|10@1+ (10,0) [0|10000] "rpm" Receiver
   SG_ VCFRONT_refrigerantHasBeenFilled m3 : 27|1@1+ (1,0) [0|1] "" Receiver
   SG_ VCFRONT_refrigerantValvesClosed m3 : 26|1@1+ (1,0) [0|1] "" Receiver
   SG_ VCFRONT_solenoidEvapCurrent m3 : 58|6@1+ (0.04,0) [0|2.4] "A" Receiver
   SG_ VCFRONT_subcoolFeedbackFlow m5 : 13|10@1- (0.1,0) [-50|50] "%" Receiver
   SG_ VCFRONT_subcoolFeedforwardFlow m5 : 3|10@1+ (0.1,0) [0|100] "%" Receiver
   SG_ VCFRONT_subcoolProtectionFlow m5 : 24|10@1+ (0.1,0) [0|100] "%" Receiver
   SG_ VCFRONT_subcoolProtectionType m5 : 34|3@1+ (1,0) [0|4] "" Receiver
   SG_ VCFRONT_tempDischargeSimulated m3 : 44|11@1+ (0.125,-40) [-40|150] "C" Receiver
   SG_ VCFRONT_thmlFanSpiError m1 : 55|1@1+ (1,0) [0|1] "" Receiver
   SG_ VCFRONT_usingSimulatedAmbTemp m3 : 57|1@1+ (1,0) [0|1] "" Receiver
   SG_ VCFRONT_usingSimulatedDischTemp m3 : 56|1@1+ (1,0) [0|1] "" Receiver
   SG_ VCFRONT_usingSimulatedSuctTemp m3 : 55|1@1+ (1,0) [0|1] "" Receiver

BO_ 737 ID2E1VCFRONT_status: 8 VehicleBus
   SG_ VCFRONT_statusIndex M : 0|3@1+ (1,0) [0|6] "" Receiver
   SG_ VCFRONT_12VARailStable m5 : 5|1@1+ (1,0) [0|1] "" Receiver
   SG_ VCFRONT_12VBRailStable m5 : 6|1@1+ (1,0) [0|1] "" Receiver
   SG_ VCFRONT_12VOverchargeCounter m4 : 16|4@1+ (1,0) [0|15] "" Receiver
   SG_ VCFRONT_5VARailStable m5 : 3|1@1+ (1,0) [0|1] "" Receiver
   SG_ VCFRONT_5VBRailStable m5 : 4|1@1+ (1,0) [0|1] "" Receiver
   SG_ VCFRONT_AS8510Voltage m5 : 28|12@1+ (0.00544368,0) [0|22.2864] "V" Receiver
   SG_ VCFRONT_ChargePumpVoltageStable m5 : 9|1@1+ (1,0) [0|1] "" Receiver
   SG_ VCFRONT_HSDInitCompleteU13 m5 : 11|1@1+ (1,0) [0|1] "" Receiver
   SG_ VCFRONT_HSDInitCompleteU16 m5 : 12|1@1+ (1,0) [0|1] "" Receiver
   SG_ VCFRONT_IBSFault m4 : 15|1@1+ (1,0) [0|1] "" Receiver
   SG_ VCFRONT_PCSMia m4 : 14|1@1+ (1,0) [0|1] "" Receiver
   SG_ VCFRONT_PEResetLineState m5 : 10|1@1+ (1,0) [0|1] "" Receiver
   SG_ VCFRONT_airCompressorStatus m0 : 25|3@1+ (1,0) [0|7] "" Receiver
   SG_ VCFRONT_anyClosureOpen m0 : 49|1@1+ (1,0) [0|1] "" Receiver
   SG_ VCFRONT_anyDoorOpen m0 : 50|1@1+ (1,0) [0|1] "" Receiver
   SG_ VCFRONT_batterySMState m1 : 16|4@1+ (1,0) [0|8] "" Receiver
   SG_ VCFRONT_chargeNeeded m4 : 13|1@1+ (1,0) [0|1] "" Receiver
   SG_ VCFRONT_chillerDemandActive m3 : 26|1@1+ (1,0) [0|1] "" Receiver
   SG_ VCFRONT_compPerfRecoveryLimited m3 : 27|1@1+ (1,0) [0|1] "" Receiver
   SG_ VCFRONT_coolantFillRoutineStatus m3 : 50|2@1+ (1,0) [0|3] "" Receiver
   SG_ VCFRONT_crashDetectedType m0 : 20|2@1+ (1,0) [0|3] "" Receiver
   SG_ VCFRONT_crashState m0 : 22|2@1+ (1,0) [0|3] "" Receiver
   SG_ VCFRONT_crashUnlockOverrideSet m0 : 24|1@1+ (1,0) [0|1] "" Receiver
   SG_ VCFRONT_epasWakeLine m1 : 4|1@1+ (1,0) [0|1] "" Receiver
   SG_ VCFRONT_freezeEvapITerm m3 : 24|1@1+ (1,0) [0|1] "" Receiver
   SG_ VCFRONT_frunkAccessPost m0 : 62|1@1+ (1,0) [0|1] "" Receiver
   SG_ VCFRONT_frunkInteriorRelSwitch m0 : 48|1@1+ (1,0) [0|1] "" Receiver
   SG_ VCFRONT_frunkLatchStatus m0 : 3|4@1+ (1,0) [0|8] "" Receiver
   SG_ VCFRONT_frunkLatchType m0 : 58|2@1+ (1,0) [0|2] "" Receiver
   SG_ VCFRONT_hasLowRefrigerant m3 : 29|1@1+ (1,0) [0|1] "" Receiver
   SG_ VCFRONT_headlampLeftFanStatus m0 : 60|1@1+ (1,0) [0|1] "" Receiver
   SG_ VCFRONT_headlampRightFanStatus m0 : 61|1@1+ (1,0) [0|1] "" Receiver
   SG_ VCFRONT_headlightLeftVPosition m0 : 28|10@1+ (1,0) [0|1023] "ticks" Receiver
   SG_ VCFRONT_headlightRightVPosition m0 : 38|10@1+ (1,0) [0|1023] "ticks" Receiver
   SG_ VCFRONT_homelinkCommStatus m2 : 48|2@1+ (1,0) [0|3] "" Receiver
   SG_ VCFRONT_homelinkV2Response0 m2 : 8|8@1+ (1,0) [0|255] "" Receiver
   SG_ VCFRONT_homelinkV2Response1 m2 : 16|8@1+ (1,0) [0|255] "" Receiver
   SG_ VCFRONT_homelinkV2Response2 m2 : 24|8@1+ (1,0) [0|255] "" Receiver
   SG_ VCFRONT_homelinkV2Response3 m2 : 32|8@1+ (1,0) [0|255] "" Receiver
   SG_ VCFRONT_homelinkV2Response4 m2 : 40|8@1+ (1,0) [0|255] "" Receiver
   SG_ VCFRONT_hornOn m0 : 51|1@1+ (1,0) [0|1] "" Receiver
   SG_ VCFRONT_hvacPerfTestCommand m3 : 48|2@1+ (1,0) [0|3] "" Receiver
   SG_ VCFRONT_iBoosterStateDBG m1 : 5|3@1+ (1,0) [0|4] "" Receiver
   SG_ VCFRONT_iBoosterWakeLine m1 : 3|1@1+ (1,0) [0|1] "" Receiver
   SG_ VCFRONT_isActiveHeatingBattery m0 : 63|1@1+ (1,0) [0|1] "" Receiver
   SG_ VCFRONT_isColdStartRunning m3 : 30|1@1+ (1,0) [0|1] "" Receiver
   SG_ VCFRONT_isEvapOperationAllowed m3 : 25|1@1+ (1,0) [0|1] "" Receiver
   SG_ VCFRONT_isHeatPumpOilPurgeActive m3 : 31|1@1+ (1,0) [0|1] "" Receiver
   SG_ VCFRONT_maxEvapHeatRejection m3 : 8|8@1+ (65,0) [0|16575] "W" Receiver
   SG_ VCFRONT_minEvapHeatRejection m3 : 16|8@1+ (10,0) [0|2500] "W" Receiver
   SG_ VCFRONT_pressureRefrigDischarge m3 : 40|8@1+ (0.125,0) [0|31.75] "bar" Receiver
   SG_ VCFRONT_pressureRefrigSuction m3 : 32|7@1+ (0.125,0) [0|11.5] "bar" Receiver
   SG_ VCFRONT_radarHeaterState m0 : 52|3@1+ (1,0) [0|4] "" Receiver
   SG_ VCFRONT_railAState m5 : 7|1@1+ (1,0) [0|1] "" Receiver
   SG_ VCFRONT_railBState m5 : 8|1@1+ (1,0) [0|1] "" Receiver
   SG_ VCFRONT_refrigFillRoutineStatus m3 : 52|2@1+ (1,0) [0|3] "" Receiver
   SG_ VCFRONT_reverseBatteryFault m4 : 30|1@1+ (1,0) [0|1] "" Receiver
   SG_ VCFRONT_shortedCellFaultCounter m4 : 44|3@1+ (1,0) [0|7] "" Receiver
   SG_ VCFRONT_silentWakeIBSCurrent m4 : 32|12@1- (0.1,-204.7) [-409.5|0] "mA" Receiver
   SG_ VCFRONT_sleepCurrent m1 : 32|12@1- (0.1,-204.7) [-409.5|0] "mA" Receiver
   SG_ VCFRONT_tempCompTargetVoltage m4 : 3|10@1+ (0.01,9) [9|16] "V" Receiver
   SG_ VCFRONT_timeSpentSleeping m1 : 24|8@1+ (1,0) [0|255] "s" Receiver
   SG_ VCFRONT_vbatMonitorVoltage m5 : 16|12@1+ (0.00544368,0) [0|22.2864] "V" Receiver
   SG_ VCFRONT_vbatProt m5 : 40|12@1+ (0.00544368,0) [0|22.2919] "V" Receiver
   SG_ VCFRONT_vehicleStatusDBG m1 : 8|5@1+ (1,0) [0|17] "" Receiver
   SG_ VCFRONT_voltageDropCounter m4 : 20|4@1+ (1,0) [0|15] "" Receiver
   SG_ VCFRONT_voltageFloorReachedCount m4 : 24|4@1+ (1,0) [0|15] "" Receiver
   SG_ VCFRONT_voltageProfile m4 : 28|2@1+ (1,0) [0|3] "" Receiver
   SG_ VCFRONT_wiperPosition m0 : 12|3@1+ (1,0) [0|4] "" Receiver
   SG_ VCFRONT_wiperSpeed m0 : 8|4@1+ (1,0) [0|8] "" Receiver
   SG_ VCFRONT_wiperState m0 : 16|4@1+ (1,0) [0|12] "" Receiver

BO_ 897 ID381VCFRONT_logging1Hz: 8 VehicleBus
   SG_ VCFRONT_logging1HzIndex M : 0|5@1+ (1,0) [0|19] "" Receiver
   SG_ VCFRONT_CCQdotActual m9 : 21|7@1+ (80,0) [0|10100] "W" Receiver
   SG_ VCFRONT_CCQdotFdFrwrdTarget m9 : 7|7@1+ (80,0) [0|10100] "W" Receiver
   SG_ VCFRONT_CCQdotFdbk m9 : 14|7@1- (80,0) [-5000|5000] "W" Receiver
   SG_ VCFRONT_CMPDischargeSuperheat m8 : 17|5@1- (1,6) [-10|21] "C" Receiver
   SG_ VCFRONT_DIQdotA m9 : 42|7@1+ (80,0) [0|10000] "W" Receiver
   SG_ VCFRONT_HCML_bladeTemp m3 : 32|8@1- (1,67) [-60|194] "C" Receiver
   SG_ VCFRONT_HCML_diffuseTemp m3 : 40|8@1- (1,67) [-60|194] "C" Receiver
   SG_ VCFRONT_HCML_highBeamTemp m3 : 16|8@1- (1,67) [-60|194] "C" Receiver
   SG_ VCFRONT_HCML_lowBeamSpotTemp m3 : 8|8@1- (1,67) [-60|194] "C" Receiver
   SG_ VCFRONT_HCML_turnTemp m3 : 24|8@1- (1,67) [-60|194] "C" Receiver
   SG_ VCFRONT_HCMR_bladeTemp m4 : 32|8@1- (1,67) [-60|194] "C" Receiver
   SG_ VCFRONT_HCMR_diffuseTemp m4 : 40|8@1- (1,67) [-60|194] "C" Receiver
   SG_ VCFRONT_HCMR_highBeamTemp m4 : 16|8@1- (1,67) [-60|194] "C" Receiver
   SG_ VCFRONT_HCMR_lowBeamSpotTemp m4 : 8|8@1- (1,67) [-60|194] "C" Receiver
   SG_ VCFRONT_HCMR_turnTemp m4 : 24|8@1- (1,67) [-60|194] "C" Receiver
   SG_ VCFRONT_PDischargeControllerOutp m14 : 24|8@1+ (0.5,0) [0|100] "%" Receiver
   SG_ VCFRONT_PSuctionControllerOutput m14 : 40|8@1+ (0.5,0) [0|100] "%" Receiver
   SG_ VCFRONT_ambientColderThanBatt m16 : 8|1@1+ (1,0) [0|1] "" Receiver
   SG_ VCFRONT_ambientSourcingAvailable m16 : 9|1@1+ (1,0) [0|1] "" Receiver
   SG_ VCFRONT_ambientSourcingDisabled m14 : 38|1@1+ (1,0) [0|1] "" Receiver
   SG_ VCFRONT_battDissipation m12 : 8|8@1+ (140,0) [0|35000] "W" Receiver
   SG_ VCFRONT_battLoopWorthCooling m16 : 15|1@1+ (1,0) [0|1] "" Receiver
   SG_ VCFRONT_battOverStagUpperLimit m16 : 6|1@1+ (1,0) [0|1] "" Receiver
   SG_ VCFRONT_battUnderStagUpperLimit m16 : 7|1@1+ (1,0) [0|1] "" Receiver
   SG_ VCFRONT_cabinHeatEnergyDuringDri m8 : 42|7@1+ (150,0) [0|19000] "Wh" Receiver
   SG_ VCFRONT_calibratedPositionHCML m6 : 5|10@1+ (1,0) [0|1023] "Steps" Receiver
   SG_ VCFRONT_calibratedPositionHCMR m6 : 16|10@1+ (1,0) [0|1023] "Steps" Receiver
   SG_ VCFRONT_ccLeftExvCalibFailed m11 : 60|1@1+ (1,0) [0|1] "" Receiver
   SG_ VCFRONT_ccLeftExvCalibOffset m11 : 40|8@1- (4,0) [-510|510] "ticks" Receiver
   SG_ VCFRONT_ccLeftExvRange m7 : 41|9@1+ (3,0) [0|1500] "ticks" Receiver
   SG_ VCFRONT_ccRightExvCalibFailed m11 : 61|1@1+ (1,0) [0|1] "" Receiver
   SG_ VCFRONT_ccRightExvCalibOffset m11 : 48|8@1- (4,0) [-510|510] "ticks" Receiver
   SG_ VCFRONT_ccRightExvRange m7 : 50|9@1+ (3,0) [0|1500] "ticks" Receiver
   SG_ VCFRONT_chillerExvCalibFailed m11 : 56|1@1+ (1,0) [0|1] "" Receiver
   SG_ VCFRONT_chillerExvCalibOffset m11 : 8|8@1- (4,0) [-510|510] "ticks" Receiver
   SG_ VCFRONT_chillerExvRange m7 : 5|9@1+ (3,0) [0|1500] "ticks" Receiver
   SG_ VCFRONT_chillerInletTempEstimate m13 : 27|8@1- (1,0) [-40|85] "C" Receiver
   SG_ VCFRONT_chillerLiftDisabledLowPs m14 : 39|1@1+ (1,0) [0|1] "" Receiver
   SG_ VCFRONT_chillerPassiveCoolPower m12 : 24|8@1- (60,7560) [0|15000] "W" Receiver
   SG_ VCFRONT_compEnergyDuringDrive m8 : 35|7@1+ (150,0) [0|19000] "Wh" Receiver
   SG_ VCFRONT_condenserPressureLimit m1 : 8|6@1+ (0.16,10) [10|20] "bar" Receiver
   SG_ VCFRONT_coolantLevelVoltage m0 : 55|9@1+ (0.01,0) [0|5] "V" Receiver
   SG_ VCFRONT_coolantValveAngleDrift m2 : 18|10@1+ (0.25,-127) [-127|127] "degrees" Receiver
   SG_ VCFRONT_coolantValveCountRange m2 : 8|10@1+ (1,375) [375|1375] "ticks" Receiver
   SG_ VCFRONT_coolantValveRadBypass m2 : 56|7@1+ (1,0) [0|100] "%" Receiver
   SG_ VCFRONT_coolantValveRecalCount m2 : 28|16@1+ (1,0) [0|65535] "" Receiver
   SG_ VCFRONT_coolantValveRecalReason m2 : 5|3@1+ (1,0) [0|6] "" Receiver
   SG_ VCFRONT_coolantValveWindupEstL m2 : 44|6@1+ (2,0) [0|126] "ticks" Receiver
   SG_ VCFRONT_coolantValveWindupEstR m2 : 50|6@1+ (2,0) [0|126] "ticks" Receiver
   SG_ VCFRONT_currentPositionHCML m6 : 26|10@1+ (1,0) [0|1023] "Steps" Receiver
   SG_ VCFRONT_currentPositionHCMR m6 : 36|10@1+ (1,0) [0|1023] "Steps" Receiver
   SG_ VCFRONT_cycleModelConverged m10 : 61|1@1+ (1,0) [0|1] "" Receiver
   SG_ VCFRONT_diDissipation m12 : 16|8@1+ (80,0) [0|20000] "W" Receiver
   SG_ VCFRONT_dischargePressureTarget m14 : 8|7@1+ (0.25,0) [0|26] "bar" Receiver
   SG_ VCFRONT_estCompPower m16 : 48|8@1+ (50,0) [0|12750] "W" Receiver
   SG_ VCFRONT_estCompPressureInlet m16 : 24|8@1+ (0.05,0) [0|12.75] "bar" Receiver
   SG_ VCFRONT_estCompPressureOutlet m16 : 32|8@1+ (0.1,0) [1|26.5] "bar" Receiver
   SG_ VCFRONT_estCompRefrigMassflow m16 : 17|7@1+ (2,0) [0|254] "g/s" Receiver
   SG_ VCFRONT_estCompTempOutlet m16 : 40|8@1+ (1.5,0) [0|190.5] "C" Receiver
   SG_ VCFRONT_estCompressorRpm m10 : 48|6@1+ (400,0) [0|25200] "rpm" Receiver
   SG_ VCFRONT_estPressureDisch m10 : 19|7@1+ (0.25,0) [0|31.75] "bar" Receiver
   SG_ VCFRONT_estPressureLiq m10 : 5|7@1+ (0.25,0) [0|31.75] "bar" Receiver
   SG_ VCFRONT_estPressureSuct m10 : 12|7@1+ (0.125,0) [0|11.5] "bar" Receiver
   SG_ VCFRONT_estQLift m10 : 54|7@1+ (100,0) [0|12700] "W" Receiver
   SG_ VCFRONT_estTempDisch m10 : 40|8@1- (0.8,68.8) [-34|170] "C" Receiver
   SG_ VCFRONT_estTempLiq m10 : 26|8@1- (0.8,68.8) [-34|170] "C" Receiver
   SG_ VCFRONT_estTempSuct m10 : 34|6@1- (1,2) [-30|33] "C" Receiver
   SG_ VCFRONT_evapDisabledLowPsCutout m14 : 15|1@1+ (1,0) [0|1] "" Receiver
   SG_ VCFRONT_evapExvCalibFailed m11 : 57|1@1+ (1,0) [0|1] "" Receiver
   SG_ VCFRONT_evapExvCalibOffset m11 : 16|8@1- (4,0) [-510|510] "ticks" Receiver
   SG_ VCFRONT_evapExvRange m7 : 14|9@1+ (3,0) [0|1500] "ticks" Receiver
   SG_ VCFRONT_evapFdFrwrdTarget m9 : 28|7@1+ (80,0) [0|10100] "W" Receiver
   SG_ VCFRONT_evapFdFrwrdTargetMinimum m9 : 49|7@1+ (80,0) [0|10000] "W" Receiver
   SG_ VCFRONT_evapFdbk m9 : 35|7@1- (80,0) [-5000|5000] "W" Receiver
   SG_ VCFRONT_exteriorQuietModeAllowed m9 : 6|1@1+ (1,0) [0|1] "" Receiver
   SG_ VCFRONT_exteriorQuietModeEnabled m9 : 5|1@1+ (1,0) [0|1] "" Receiver
   SG_ VCFRONT_fanControlFeedfwdActive m15 : 49|1@1+ (1,0) [0|1] "" Receiver
   SG_ VCFRONT_fanControlRadCanCool m15 : 48|1@1+ (1,0) [0|1] "" Receiver
   SG_ VCFRONT_fanControlRadiatorInletT m15 : 57|6@1- (1.8,36) [-20|90] "C" Receiver
   SG_ VCFRONT_fanControlRadiatorUa m15 : 50|7@1+ (8,0) [0|1000] "W/C" Receiver
   SG_ VCFRONT_fanDemandCondenser m1 : 14|7@1+ (1,0) [0|100] "%" Receiver
   SG_ VCFRONT_fanDemandRadiator m1 : 21|7@1+ (1,0) [0|100] "%" Receiver
   SG_ VCFRONT_feedBackDuctTempControll m15 : 32|8@1+ (1,-100) [-100|100] "-" Receiver
   SG_ VCFRONT_feedBackEvapTempControll m15 : 24|7@1+ (0.01,-0.5) [-0.5|0.5] "-" Receiver
   SG_ VCFRONT_feedFwdFanDemand m13 : 35|7@1+ (1,0) [0|100] "%" Receiver
   SG_ VCFRONT_feedFwdMDotCabinCondense m15 : 16|8@1+ (0.005,0) [0|1] "-" Receiver
   SG_ VCFRONT_feedFwdMDotEvaporator m15 : 8|8@1+ (0.005,0) [0|1] "-" Receiver
   SG_ VCFRONT_feedFwdPumpDemand m13 : 42|7@1+ (1,0) [0|100] "%" Receiver
   SG_ VCFRONT_feedfwdLoadCoolingDomina m9 : 59|1@1+ (1,0) [0|1] "" Receiver
   SG_ VCFRONT_homelinkRegionCode m5 : 8|4@1+ (1,0) [0|9] "" Receiver
   SG_ VCFRONT_hpAmbientSource m17 : 6|1@1+ (1,0) [0|1] "" Receiver
   SG_ VCFRONT_hpAtSteadyState m16 : 63|1@1+ (1,0) [0|1] "" Receiver
   SG_ VCFRONT_hpBattStagTarget m8 : 28|7@1+ (1,-40) [-40|80] "C" Receiver
   SG_ VCFRONT_hpBatteryCool m17 : 19|1@1+ (1,0) [0|1] "" Receiver
   SG_ VCFRONT_hpBatteryCoolCabinConden m17 : 20|1@1+ (1,0) [0|1] "" Receiver
   SG_ VCFRONT_hpBatteryCoolCabinReheat m17 : 21|1@1+ (1,0) [0|1] "" Receiver
   SG_ VCFRONT_hpBatteryCoolEvaporator m17 : 22|1@1+ (1,0) [0|1] "" Receiver
   SG_ VCFRONT_hpBatteryHeatAmbientSour m17 : 17|1@1+ (1,0) [0|1] "" Receiver
   SG_ VCFRONT_hpBatteryHeatCOP1 m17 : 18|1@1+ (1,0) [0|1] "" Receiver
   SG_ VCFRONT_hpCOP m8 : 22|6@1+ (0.1,0) [0|6] "-" Receiver
   SG_ VCFRONT_hpCabinCoolEvaporator m17 : 15|1@1+ (1,0) [0|1] "" Receiver
   SG_ VCFRONT_hpCabinCoolEvaporatorReh m17 : 16|1@1+ (1,0) [0|1] "" Receiver
   SG_ VCFRONT_hpCabinHeatAmbientSource m17 : 8|1@1+ (1,0) [0|1] "" Receiver
   SG_ VCFRONT_hpCabinHeatBatteryCoolRe m17 : 14|1@1+ (1,0) [0|1] "" Receiver
   SG_ VCFRONT_hpCabinHeatBatteryHeatRe m17 : 13|1@1+ (1,0) [0|1] "" Receiver
   SG_ VCFRONT_hpCabinHeatBlend m17 : 11|1@1+ (1,0) [0|1] "" Receiver
   SG_ VCFRONT_hpCabinHeatCOP1 m17 : 12|1@1+ (1,0) [0|1] "" Receiver
   SG_ VCFRONT_hpCabinHeatReheatAmbient m17 : 10|1@1+ (1,0) [0|1] "" Receiver
   SG_ VCFRONT_hpCabinHeatReheatScaveng m17 : 9|1@1+ (1,0) [0|1] "" Receiver
   SG_ VCFRONT_hpCabinHeatScavengeOnly m17 : 7|1@1+ (1,0) [0|1] "" Receiver
   SG_ VCFRONT_hpCompPowerIndex m16 : 56|7@1+ (1,0) [0|127] "-" Receiver
   SG_ VCFRONT_hpForceScavenge m16 : 5|1@1+ (1,0) [0|1] "" Receiver
   SG_ VCFRONT_hpGeneral m17 : 5|1@1+ (1,0) [0|1] "" Receiver
   SG_ VCFRONT_hpMode m16 : 10|5@1+ (1,0) [0|19] "" Receiver
   SG_ VCFRONT_hpPotentialLowRefrig m9 : 61|1@1+ (1,0) [0|1] "" Receiver
   SG_ VCFRONT_hpRefrigerantPurgeState m9 : 62|2@1+ (1,0) [0|2] "" Receiver
   SG_ VCFRONT_hpSubcoolTarget m8 : 12|5@1+ (1,0) [0|31] "C" Receiver
   SG_ VCFRONT_lccExvCalibFailed m11 : 59|1@1+ (1,0) [0|1] "" Receiver
   SG_ VCFRONT_lccExvCalibOffset m11 : 32|8@1- (4,0) [-510|510] "ticks" Receiver
   SG_ VCFRONT_lccExvRange m7 : 32|9@1+ (3,0) [0|1500] "ticks" Receiver
   SG_ VCFRONT_lccInletTempEstimate m13 : 19|8@1- (1,0) [-40|85] "C" Receiver
   SG_ VCFRONT_lccPassiveHeatPower m12 : 32|8@1+ (60,0) [0|15000] "W" Receiver
   SG_ VCFRONT_lowSideLiftEnergyDrive m8 : 49|7@1+ (150,0) [0|19000] "Wh" Receiver
   SG_ VCFRONT_lowSideWattsLift m8 : 56|7@1+ (60,0) [0|7600] "W" Receiver
   SG_ VCFRONT_maxAllowedEvapPowerInSer m12 : 40|8@1+ (40,0) [0|10000] "W" Receiver
   SG_ VCFRONT_maxChillerCoolingPower m15 : 40|8@1+ (100,0) [0|20000] "W" Receiver
   SG_ VCFRONT_maxCompressorRPMAllowed m14 : 56|7@1+ (90,0) [0|11430] "rpm" Receiver
   SG_ VCFRONT_minAllowedChillerPowerIn m12 : 48|8@1+ (40,0) [0|10000] "W" Receiver
   SG_ VCFRONT_minAllowedSuctionPressur m14 : 48|7@1+ (0.02,0) [0|2.5] "bar" Receiver
   SG_ VCFRONT_minFlowPDCont m14 : 16|8@1+ (0.5,0) [0|100] "%" Receiver
   SG_ VCFRONT_modeDesired m0 : 14|2@1+ (1,0) [0|3] "" Receiver
   SG_ VCFRONT_modeTransitionID m0 : 8|6@1+ (1,0) [0|39] "" Receiver
   SG_ VCFRONT_modelLoadCoolingDominant m9 : 60|1@1+ (1,0) [0|1] "" Receiver
   SG_ VCFRONT_passiveCoolingState m9 : 56|2@1+ (1,0) [0|3] "" Receiver
   SG_ VCFRONT_ptLoopWorthCooling m16 : 16|1@1+ (1,0) [0|1] "" Receiver
   SG_ VCFRONT_pumpBatteryFETTemp m1 : 36|8@1+ (1,-40) [-40|150] "C" Receiver
   SG_ VCFRONT_pumpPowertrainFETTemp m1 : 44|8@1+ (1,-40) [-40|150] "C" Receiver
   SG_ VCFRONT_radActiveRejectEstimate m13 : 49|15@1+ (1,0) [0|30000] "W" Receiver
   SG_ VCFRONT_radPassiveRejectEstimate m13 : 5|14@1+ (1,0) [0|15000] "W" Receiver
   SG_ VCFRONT_radiatorFanFETTemp m1 : 52|8@1+ (1,-40) [-40|150] "C" Receiver
   SG_ VCFRONT_radiatorFanRunReason m1 : 60|4@1+ (1,0) [0|8] "" Receiver
   SG_ VCFRONT_recircExvCalibFailed m11 : 58|1@1+ (1,0) [0|1] "" Receiver
   SG_ VCFRONT_recircExvCalibOffset m11 : 24|8@1- (4,0) [-510|510] "ticks" Receiver
   SG_ VCFRONT_recircExvRange m7 : 23|9@1+ (3,0) [0|1500] "ticks" Receiver
   SG_ VCFRONT_subcoolActual m8 : 5|7@1- (0.4,15.2) [-10|40] "C" Receiver
   SG_ VCFRONT_suctionPressureTarget m14 : 32|6@1+ (0.15,0) [0|8] "bar" Receiver
   SG_ VCFRONT_targetBatActiveCool m0 : 32|7@1+ (1,0) [0|100] "C" Receiver
   SG_ VCFRONT_targetBatActiveHeat m0 : 48|7@1+ (1,-40) [-40|60] "C" Receiver
   SG_ VCFRONT_targetBatPassive m0 : 40|7@1+ (1,-20) [-20|80] "C" Receiver
   SG_ VCFRONT_targetPTActiveCool m0 : 16|8@1+ (1,-40) [-40|120] "C" Receiver
   SG_ VCFRONT_targetPTPassive m0 : 24|8@1+ (1,-40) [-40|120] "C" Receiver
   SG_ VCFRONT_tempRefrigSuction m1 : 28|8@1+ (0.5,-40) [-40|85] "C" Receiver
   SG_ VCFRONT_totalLoadCoolingDominant m9 : 58|1@1+ (1,0) [0|1] "" Receiver
   SG_ VCFRONT_wiperCycles m18 : 48|16@1+ (100,0) [0|6.5535e+06] "Cycles" Receiver

BA_DEF_ BO_ "GenMsgCycleTime" INT 0 0;
BA_DEF_ SG_ "SystemSignalLongSymbol" STRING ;
BA_ "SystemSignalLongSymbol" SG_ 800 BMS_a040_SW_Watch_Dog_HW_Trigger "BMS_a040_SW_Watch_Dog_HW_Trigger";
BA_ "SystemSignalLongSymbol" SG_ 800 BMS_a041_SW_Destructive_Reset_So "BMS_a041_SW_Destructive_Reset_So";
BA_ "SystemSignalLongSymbol" SG_ 800 BMS_a057_SW_Bandolier_Model_Warn "BMS_a057_SW_Bandolier_Model_Warn";
BA_ "SystemSignalLongSymbol" SG_ 800 BMS_a058_SW_Bandolier_Model_Rese "BMS_a058_SW_Bandolier_Model_Rese";
BA_ "SystemSignalLongSymbol" SG_ 800 BMS_a092_SW_ChargePort_Mia_On_Hv "BMS_a092_SW_ChargePort_Mia_On_Hv";
BA_ "SystemSignalLongSymbol" SG_ 800 BMS_a098_SW_BMB_Data_Integrity_L "BMS_a098_SW_BMB_Data_Integrity_L";
BA_ "SystemSignalLongSymbol" SG_ 800 BMS_a135_HW_BMB_Diagnostics_Fail "BMS_a135_HW_BMB_Diagnostics_Fail";
BA_ "SystemSignalLongSymbol" SG_ 800 BMS_a178_SW_Uncontrolled_Regen_P "BMS_a178_SW_Uncontrolled_Regen_P";
BA_ "GenMsgCycleTime" BO_ 819 500;
BA_ "GenMsgCycleTime" BO_ 577 100;
BA_ "SystemSignalLongSymbol" SG_ 691 VCRIGHT_hvacCabOvrheatProtAllowe "VCRIGHT_hvacCabOvrheatProtAllowe";
BA_ "SystemSignalLongSymbol" SG_ 691 VCRIGHT_ptcHeaterReqAirpathBlock "VCRIGHT_ptcHeaterReqAirpathBlock";
BA_ "SystemSignalLongSymbol" SG_ 737 VCFRONT_voltageFloorReachedCount "VCFRONT_voltageFloorReachedCount";
BA_ "SystemSignalLongSymbol" SG_ 897 VCFRONT_cabinHeatEnergyDuringDri "VCFRONT_cabinHeatEnergyDuringDri";
BA_DEF_DEF_ "GenMsgCycleTime" 0;
BA_DEF_DEF_ "SystemSignalLongSymbol" "";
CM_ SG_ 647 PTC_leftCurrentHV "Heater Left Current";
CM_ SG_ 647 PTC_rightCurrentHV "Heater Right Current";
CM_ SG_ 647 PTC_voltageHV "Heater Voltage";
CM_ SG_ 819 UI_acChargeCurrentLimit "UI Charge Current Limit";
CM_ SG_ 826 UI_Range "Range";
CM_ SG_ 826 UI_SOC "State of Charge UI";
CM_ SG_ 826 UI_uSOE "UI fine SOC";
CM_ SG_ 826 UI_ratedWHpM "WHM Rating";
CM_ SG_ 577 VCFRONT_coolantFlowBatActual "Battery Coolant Flow";
CM_ SG_ 577 VCFRONT_coolantFlowPTActual "Powertrain Coolant Flow";
CM_ BO_ 1367 "swapped with 5D7 in old firmware";
CM_ BO_ 1495 "swapped with 557 in old firmware";
CM_ BO_ 2005 "swapped with 757 in old firmware";
CM_ BO_ 1879 "swapped with 7D5 in old firmware";
CM_ SG_ 579 VCRIGHT_hvacCabinTempEst "Cabin Temperature";
CM_ SG_ 524 VCRIGHT_wattsDemandEvap "Evaporator Power";
CM_ SG_ 691 VCRIGHT_ptcHeaterPwrDemandLeft "Heater Left Power Demand";
CM_ SG_ 691 VCRIGHT_ptcHeaterPwrDemandRight "Heater Right Power Demand";
CM_ SG_ 691 VCRIGHT_wattsHeaterLeftTotal "Heater Left Power";
CM_ SG_ 691 VCRIGHT_wattsHeaterRightTotal "Heater Right Power";
VAL_ 800 BMS_matrixIndex 0 "BMS_AlertMatrix0" 1 "BMS_AlertMatrix1" 2 "BMS_AlertMatrix2";
VAL_ 796 CC_currentLimit 255 "SNA";
VAL_ 796 CC_gridGrounding 1 "CC_GRID_GROUNDING_IT_SplitPhase" 2 "CC_GRID_GROUNDING_SNA" 0 "CC_GRID_GROUNDING_TN_TT";
VAL_ 796 CC_line1Voltage 511 "SNA";
VAL_ 796 CC_line2Voltage 511 "SNA";
VAL_ 796 CC_line3Voltage 511 "SNA";
VAL_ 796 CC_numPhases 0 "SNA";
VAL_ 796 CC_pilotState 2 "CC_PILOT_STATE_FAULTED" 1 "CC_PILOT_STATE_IDLE" 0 "CC_PILOT_STATE_READY" 3 "CC_PILOT_STATE_SNA";
VAL_ 797 CC_chgStatus2Index 0 "Mux0";
VAL_ 797 CC_buttonState 1 "CC_BUTTON_PRESSED" 0 "CC_BUTTON_RELEASED";
VAL_ 812 CC_logIndex 0 "Mux0" 1 "Mux1" 10 "Mux10" 11 "Mux11" 12 "Mux12" 13 "Mux13" 2 "Mux2" 3 "Mux3" 4 "Mux4";
VAL_ 812 CC_activeConnectorID 255 "SNA";
VAL_ 812 CC_conn1Current 255 "SNA";
VAL_ 812 CC_conn2Current 255 "SNA";
VAL_ 812 CC_conn3Current 255 "SNA";
VAL_ 812 CC_conn4Current 255 "SNA";
VAL_ 812 CC_contactor1Closed 1 "CC_CONTACTOR_CLOSED" 0 "CC_CONTACTOR_OPEN" 3 "CC_CONTACTOR_SNA";
VAL_ 812 CC_contactor2Closed 1 "CC_CONTACTOR_CLOSED" 0 "CC_CONTACTOR_OPEN" 3 "CC_CONTACTOR_SNA";
VAL_ 812 CC_temperature1 127 "SNA";
VAL_ 812 CC_temperature2 127 "SNA";
VAL_ 812 CC_temperature3 127 "SNA";
VAL_ 812 CC_temperature4 127 "SNA";
VAL_ 573 CP_chargeShutdownRequest 2 "EMERGENCY_SHUTDOWN_REQUESTED" 1 "GRACEFUL_SHUTDOWN_REQUESTED" 0 "NO_SHUTDOWN_REQUESTED";
VAL_ 573 CP_hvChargeStatus 1 "CP_CHARGE_CONNECTED" 5 "CP_CHARGE_ENABLED" 6 "CP_CHARGE_FAULTED" 0 "CP_CHARGE_INACTIVE" 2 "CP_CHARGE_STANDBY" 4 "CP_EVSE_TEST_PASSED" 3 "CP_EXT_EVSE_TEST_ACTIVE";
VAL_ 317 CP_chargeShutdownRequest 2 "EMERGENCY_SHUTDOWN_REQUESTED" 1 "GRACEFUL_SHUTDOWN_REQUESTED" 0 "NO_SHUTDOWN_REQUESTED";
VAL_ 317 CP_evseChargeType 2 "AC_CHARGER_PRESENT" 1 "DC_CHARGER_PRESENT" 0 "NO_CHARGER_PRESENT";
VAL_ 317 CP_hvChargeStatus 1 "CP_CHARGE_CONNECTED" 5 "CP_CHARGE_ENABLED" 6 "CP_CHARGE_FAULTED" 0 "CP_CHARGE_INACTIVE" 2 "CP_CHARGE_STANDBY" 4 "CP_EVSE_TEST_PASSED" 3 "CP_EXT_EVSE_TEST_ACTIVE";
VAL_ 1085 CP_chargeShutdownRequest_log 2 "EMERGENCY_SHUTDOWN_REQUESTED" 1 "GRACEFUL_SHUTDOWN_REQUESTED" 0 "NO_SHUTDOWN_REQUESTED";
VAL_ 1085 CP_evseChargeType_log 2 "AC_CHARGER_PRESENT" 1 "DC_CHARGER_PRESENT" 0 "NO_CHARGER_PRESENT";
VAL_ 1085 CP_hvChargeStatus_log 1 "CP_CHARGE_CONNECTED" 5 "CP_CHARGE_ENABLED" 6 "CP_CHARGE_FAULTED" 0 "CP_CHARGE_INACTIVE" 2 "CP_CHARGE_STANDBY" 4 "CP_EVSE_TEST_PASSED" 3 "CP_EXT_EVSE_TEST_ACTIVE";
VAL_ 541 CP_acChargeState 1 "AC_CHARGE_CONNECTED_CHARGE_BLOCKED" 3 "AC_CHARGE_ENABLED" 6 "AC_CHARGE_FAULT" 0 "AC_CHARGE_INACTIVE" 4 "AC_CHARGE_ONBOARD_CHARGER_SHUTDOWN" 2 "AC_CHARGE_STANDBY" 5 "AC_CHARGE_VEH_SHUTDOWN";
VAL_ 541 CP_cableType 2 "CHG_CABLE_TYPE_GB_AC" 3 "CHG_CABLE_TYPE_GB_DC" 0 "CHG_CABLE_TYPE_IEC" 1 "CHG_CABLE_TYPE_SAE" 4 "CHG_CABLE_TYPE_SNA";
VAL_ 541 CP_evseChargeType_UI 2 "AC_CHARGER_PRESENT" 1 "DC_CHARGER_PRESENT" 0 "NO_CHARGER_PRESENT";
VAL_ 541 CP_gbState 10 "GBDC_CHARGE_DISABLING" 5 "GBDC_CHARGE_PARAM_CONFIG" 8 "GBDC_CHARGING" 2 "GBDC_COMMS_RECEIVED" 11 "GBDC_END_OF_CHARGE" 12 "GBDC_ERROR_HANDLING" 14 "GBDC_FAULTED" 3 "GBDC_HANDSHAKING_EXT_ISO" 0 "GBDC_INACTIVE" 7 "GBDC_READY_TO_CHARGE" 4 "GBDC_RECOGNITION" 13 "GBDC_RETRY_CHARGE" 9 "GBDC_STOP_CHARGE_REQUESTED" 15 "GBDC_TESTER_PRESENT" 6 "GBDC_VEH_PACK_PRECHARGE" 1 "GBDC_WAIT_FOR_COMMS";
VAL_ 541 CP_gbdcFailureReason 1 "GBDC_ATTEMPTS_EXPIRED" 3 "GBDC_CRITICAL_FAILURE" 0 "GBDC_FAILURE_NONE" 2 "GBDC_SHUTDOWN_FAILURE";
VAL_ 541 CP_gbdcStopChargeReason 3 "GBDC_COMMS_TIMEOUT" 5 "GBDC_EVSE_CRITICAL_FAULT" 4 "GBDC_EVSE_FAULT" 2 "GBDC_EVSE_REQUESTED" 6 "GBDC_LIVE_DISCONNECT" 0 "GBDC_STOP_REASON_NONE" 7 "GBDC_SUPERCHARGER_COMMS_TIMEOUT" 1 "GBDC_VEH_REQUESTED";
VAL_ 541 CP_iecComboState 6 "IEC_COMBO_CABLE_CHECK" 5 "IEC_COMBO_CHARGE_PARAM_DISCOVERY" 1 "IEC_COMBO_CONNECTED" 8 "IEC_COMBO_ENABLED" 10 "IEC_COMBO_END_OF_CHARGE" 11 "IEC_COMBO_FAULT" 0 "IEC_COMBO_INACTIVE" 4 "IEC_COMBO_PAYMENT_SELECTION" 7 "IEC_COMBO_PRECHARGE" 3 "IEC_COMBO_SERVICE_DISCOVERY" 9 "IEC_COMBO_SHUTDOWN" 2 "IEC_COMBO_V2G_SESSION_SETUP" 12 "IEC_COMBO_WAIT_RESTART";
VAL_ 541 CP_pilot 3 "CHG_PILOT_FAST_CHARGE" 1 "CHG_PILOT_FAULTED" 4 "CHG_PILOT_IDLE" 5 "CHG_PILOT_INVALID" 2 "CHG_PILOT_LINE_CHARGE" 0 "CHG_PILOT_NONE" 7 "CHG_PILOT_SNA" 6 "CHG_PILOT_UNUSED_6";
VAL_ 541 CP_proximity 1 "CHG_PROXIMITY_DISCONNECTED" 3 "CHG_PROXIMITY_LATCHED" 0 "CHG_PROXIMITY_SNA" 2 "CHG_PROXIMITY_UNLATCHED";
VAL_ 541 CP_teslaDcState 1 "TESLA_DC_CONNECTED_CHARGE_BLOCKED" 9 "TESLA_DC_EMERGENCY_SHUTDOWN" 6 "TESLA_DC_ENABLED" 7 "TESLA_DC_EVSE_SHUTDOWN" 5 "TESLA_DC_EXT_PRECHARGE_ACTIVE" 3 "TESLA_DC_EXT_TESTS_ENABLED" 4 "TESLA_DC_EXT_TEST_ACTIVE" 10 "TESLA_DC_FAULT" 0 "TESLA_DC_INACTIVE" 2 "TESLA_DC_STANDBY" 8 "TESLA_DC_VEH_SHUTDOWN";
VAL_ 541 CP_teslaSwcanState 1 "TESLA_SWCAN_ACCEPT" 3 "TESLA_SWCAN_ESTABLISHED" 4 "TESLA_SWCAN_FAULT" 5 "TESLA_SWCAN_GO_TO_SLEEP" 0 "TESLA_SWCAN_INACTIVE" 6 "TESLA_SWCAN_OFFBOARD_UPDATE_IN_PROGRESS" 2 "TESLA_SWCAN_RECEIVE";
VAL_ 1859 VCRIGHT_mirrorRecallStatus 2 "RECALL_COMPLETE" 3 "RECALL_INTERRUPTED" 1 "RECALL_IN_PROGRESS" 0 "RECALL_SNA";
VAL_ 1859 VCRIGHT_seatRecallStatus 2 "RECALL_COMPLETE" 3 "RECALL_INTERRUPTED" 1 "RECALL_IN_PROGRESS" 0 "RECALL_SNA";
VAL_ 1859 VCRIGHT_systemRecallStatus 2 "RECALL_COMPLETE" 3 "RECALL_INTERRUPTED" 1 "RECALL_IN_PROGRESS" 0 "RECALL_SNA";
VAL_ 1885 CP_sensorDataSelect 2 "CP_SENSOR_DOOR" 0 "CP_SENSOR_DOOR_COUNTS" 4 "CP_SENSOR_INDUCTIVE_DOOR" 12 "CP_SENSOR_INLET_HARNESS_ID" 3 "CP_SENSOR_LATCH" 9 "CP_SENSOR_PILOT" 10 "CP_SENSOR_PILOT2" 1 "CP_SENSOR_PIN_TEMP" 8 "CP_SENSOR_PROX" 11 "CP_SENSOR_PROX_GB" 7 "CP_SENSOR_RAILS" 5 "CP_SENSOR_SAFETY" 6 "CP_SENSOR_UHF";
VAL_ 1885 CP_inlet1HarnessIdState 1 "HARNESS_PEDIGREE_INVALID" 0 "HARNESS_PEDIGREE_UNKNOWN_SNA" 2 "HARNESS_PEDIGREE_VALID";
VAL_ 1885 CP_inlet2HarnessIdState 1 "HARNESS_PEDIGREE_INVALID" 0 "HARNESS_PEDIGREE_UNKNOWN_SNA" 2 "HARNESS_PEDIGREE_VALID";
VAL_ 1962 HVP_debugMessageMultiplexer 0 "Mux0" 1 "Mux1" 2 "Mux2" 3 "Mux3" 4 "Mux4" 5 "Mux5" 6 "Mux6";
VAL_ 1962 HVP_shuntAsicTempDbg 32768 "SHUNT_TEMPERATURE_SNA";
VAL_ 1962 HVP_shuntAsicTempStatus 1 "SHUNT_DATA_INVALID" 0 "SHUNT_DATA_NOT_AVAILABLE" 3 "SHUNT_DATA_STALE" 2 "SHUNT_DATA_VALID";
VAL_ 1962 HVP_shuntAuxCurrentStatus 1 "SHUNT_DATA_INVALID" 0 "SHUNT_DATA_NOT_AVAILABLE" 3 "SHUNT_DATA_STALE" 2 "SHUNT_DATA_VALID";
VAL_ 1962 HVP_shuntBarTempDbg 32768 "SHUNT_TEMPERATURE_SNA";
VAL_ 1962 HVP_shuntBarTempStatus 1 "SHUNT_DATA_INVALID" 0 "SHUNT_DATA_NOT_AVAILABLE" 3 "SHUNT_DATA_STALE" 2 "SHUNT_DATA_VALID";
VAL_ 819 UI_acChargeCurrentLimit 127 "SNA";
VAL_ 820 UI_limitMode 2 "LIMIT_FACTORY" 0 "LIMIT_NORMAL" 3 "LIMIT_SERVICE" 1 "LIMIT_VALET";
VAL_ 820 UI_motorOnMode 1 "MOTORONMODE_FRONT_ONLY" 0 "MOTORONMODE_NORMAL" 2 "MOTORONMODE_REAR_ONLY";
VAL_ 820 UI_pedalMap 0 "CHILL" 2 "PERFORMANCE" 1 "SPORT";
VAL_ 820 UI_speedLimit 255 "SNA";
VAL_ 820 UI_stoppingMode 1 "CREEP" 2 "HOLD" 0 "STANDARD";
VAL_ 820 UI_systemPowerLimit 31 "SNA";
VAL_ 820 UI_systemTorqueLimit 63 "SNA";
VAL_ 820 UI_wasteMode 2 "WASTE_TYPE_FULL" 0 "WASTE_TYPE_NONE" 1 "WASTE_TYPE_PARTIAL";
VAL_ 820 UI_wasteModeRegenLimit 3 "MAX_REGEN_CURRENT_0A" 2 "MAX_REGEN_CURRENT_10A" 1 "MAX_REGEN_CURRENT_30A" 0 "MAX_REGEN_CURRENT_MAX";
VAL_ 820 UI_closureConfirmed 1 "CONFIRMED_FRUNK" 0 "CONFIRMED_NONE" 2 "CONFIRMED_PROX";
VAL_ 577 VCFRONT_coolantAirPurgeBatState 1 "AIR_PURGE_STATE_ACTIVE" 2 "AIR_PURGE_STATE_COMPLETE" 0 "AIR_PURGE_STATE_INACTIVE" 3 "AIR_PURGE_STATE_INTERRUPTED" 4 "AIR_PURGE_STATE_PENDING";
VAL_ 577 VCFRONT_coolantFlowBatReason 4 "ACTIVE_MANAGER_BATT" 9 "ACTIVE_MANAGER_PT" 6 "BMS_FLOW_REQ" 1 "COOLANT_AIR_PURGE" 7 "DAS_FLOW_REQ" 13 "DIS_FLOW_REQ" 12 "DI_FLOW_REQ" 14 "HP_FLOW_REQ" 0 "NONE" 2 "NO_FLOW_REQ" 3 "OVERRIDE_BATT" 8 "OVERRIDE_PT" 5 "PASSIVE_MANAGER_BATT" 10 "PASSIVE_MANAGER_PT" 11 "PCS_FLOW_REQ";
VAL_ 577 VCFRONT_coolantFlowPTReason 4 "ACTIVE_MANAGER_BATT" 9 "ACTIVE_MANAGER_PT" 6 "BMS_FLOW_REQ" 1 "COOLANT_AIR_PURGE" 7 "DAS_FLOW_REQ" 13 "DIS_FLOW_REQ" 12 "DI_FLOW_REQ" 14 "HP_FLOW_REQ" 0 "NONE" 2 "NO_FLOW_REQ" 3 "OVERRIDE_BATT" 8 "OVERRIDE_PT" 5 "PASSIVE_MANAGER_BATT" 10 "PASSIVE_MANAGER_PT" 11 "PCS_FLOW_REQ";
VAL_ 577 VCFRONT_wasteHeatRequestType 2 "WASTE_TYPE_FULL" 0 "WASTE_TYPE_NONE" 1 "WASTE_TYPE_PARTIAL";
VAL_ 708 PCS_logMessageSelect 3 "PCS_LOG_CHG_1" 4 "PCS_LOG_CHG_2" 5 "PCS_LOG_CHG_3" 13 "PCS_LOG_CHG_4" 21 "PCS_LOG_CHG_LINE_OFFSET" 23 "PCS_LOG_CHG_MACHINEMODEL" 20 "PCS_LOG_CHG_NO_FLOW" 6 "PCS_LOG_DCDC_1" 7 "PCS_LOG_DCDC_2" 8 "PCS_LOG_DCDC_3" 18 "PCS_LOG_DCDC_4" 19 "PCS_LOG_DCDC_5" 24 "PCS_LOG_DCDC_HVBUS_PCHG_DATA" 25 "PCS_LOG_DCDC_IMPEDANCE_EST" 22 "PCS_LOG_DCDC_STATISTICS" 14 "PCS_LOG_DLOG_1" 15 "PCS_LOG_DLOG_2" 16 "PCS_LOG_DLOG_3" 17 "PCS_LOG_DLOG_4" 26 "PCS_LOG_NUM_MSGS" 0 "PCS_LOG_PHA_1" 10 "PCS_LOG_PHA_2" 1 "PCS_LOG_PHB_1" 11 "PCS_LOG_PHB_2" 2 "PCS_LOG_PHC_1" 12 "PCS_LOG_PHC_2" 9 "PCS_LOG_SYSTEM_1";
VAL_ 708 PCS_acChargeSelfTestState 0 "PCS_SELF_TEST_IDLE" 1 "PCS_SELF_TEST_STARTED";
VAL_ 708 PCS_chgAcpwHeartbeatState 2 "PCS_ACPW_HEARTBEAT_STATE_DETECTED_OFFGRID" 3 "PCS_ACPW_HEARTBEAT_STATE_DETECTED_ONGRID" 1 "PCS_ACPW_HEARTBEAT_STATE_NOT_DETECTED" 4 "PCS_ACPW_HEARTBEAT_STATE_NUM" 0 "PCS_ACPW_HEARTBEAT_STATE_UNKNOWN";
VAL_ 708 PCS_chgInputFrequencyL1N 0 "FREQUENCY_UNKNOWN";
VAL_ 708 PCS_chgInputFrequencyL2N 0 "FREQUENCY_UNKNOWN";
VAL_ 708 PCS_chgInputFrequencyL3N 0 "FREQUENCY_UNKNOWN";
VAL_ 708 PCS_chgInternalPhaseConfig 5 "PHASE_CONFIG_MFG_TEST_CONFIG_1" 6 "PHASE_CONFIG_MFG_TEST_CONFIG_2" 7 "PHASE_CONFIG_RELIABILITY_SINGLE_PHASE" 1 "PHASE_CONFIG_SINGLE_PHASE" 8 "PHASE_CONFIG_SINGLE_PHASE_EVSE_PARALLEL" 4 "PHASE_CONFIG_SINGLE_PHASE_IEC_GB" 0 "PHASE_CONFIG_SNA" 2 "PHASE_CONFIG_THREE_PHASE" 3 "PHASE_CONFIG_THREE_PHASE_DELTA" 9 "PHASE_CONFIG_TOTAL_NUM";
VAL_ 708 PCS_chgPhALastShutdownReason 12 "PCS_PH_SHUTDOWN_CONTROL_REGULATION_FAULT" 16 "PCS_PH_SHUTDOWN_FREQ_OUT_OF_RANGE" 2 "PCS_PH_SHUTDOWN_HW_ENABLE" 4 "PCS_PH_SHUTDOWN_HW_FAULT" 7 "PCS_PH_SHUTDOWN_INPUT_OV" 6 "PCS_PH_SHUTDOWN_INPUT_UV" 11 "PCS_PH_SHUTDOWN_INT_BUS_UV" 17 "PCS_PH_SHUTDOWN_LINE_TRANSIENT_FAULT" 9 "PCS_PH_SHUTDOWN_OUTPUT_OV" 8 "PCS_PH_SHUTDOWN_OUTPUT_UV" 13 "PCS_PH_SHUTDOWN_OVER_TEMPERATURE" 5 "PCS_PH_SHUTDOWN_PLL_NOT_LOCKED" 10 "PCS_PH_SHUTDOWN_PRECHARGE_TIMEOUT" 0 "PCS_PH_SHUTDOWN_REASON_NONE" 15 "PCS_PH_SHUTDOWN_SENSOR_IRRATIONAL" 1 "PCS_PH_SHUTDOWN_SW_ENABLE" 3 "PCS_PH_SHUTDOWN_SW_FAULT" 14 "PCS_PH_SHUTDOWN_TEMP_IRRATIONAL";
VAL_ 708 PCS_chgPhAState 5 "PCS_PH_STATE_CLEAR_FAULTS" 3 "PCS_PH_STATE_ENABLE" 4 "PCS_PH_STATE_FAULT" 1 "PCS_PH_STATE_IDLE" 0 "PCS_PH_STATE_INIT" 2 "PCS_PH_STATE_PRECHARGE" 6 "PCS_PH_STATE_SHUTTING_DOWN";
VAL_ 708 PCS_chgPhBLastShutdownReason 12 "PCS_PH_SHUTDOWN_CONTROL_REGULATION_FAULT" 16 "PCS_PH_SHUTDOWN_FREQ_OUT_OF_RANGE" 2 "PCS_PH_SHUTDOWN_HW_ENABLE" 4 "PCS_PH_SHUTDOWN_HW_FAULT" 7 "PCS_PH_SHUTDOWN_INPUT_OV" 6 "PCS_PH_SHUTDOWN_INPUT_UV" 11 "PCS_PH_SHUTDOWN_INT_BUS_UV" 17 "PCS_PH_SHUTDOWN_LINE_TRANSIENT_FAULT" 9 "PCS_PH_SHUTDOWN_OUTPUT_OV" 8 "PCS_PH_SHUTDOWN_OUTPUT_UV" 13 "PCS_PH_SHUTDOWN_OVER_TEMPERATURE" 5 "PCS_PH_SHUTDOWN_PLL_NOT_LOCKED" 10 "PCS_PH_SHUTDOWN_PRECHARGE_TIMEOUT" 0 "PCS_PH_SHUTDOWN_REASON_NONE" 15 "PCS_PH_SHUTDOWN_SENSOR_IRRATIONAL" 1 "PCS_PH_SHUTDOWN_SW_ENABLE" 3 "PCS_PH_SHUTDOWN_SW_FAULT" 14 "PCS_PH_SHUTDOWN_TEMP_IRRATIONAL";
VAL_ 708 PCS_chgPhBState 5 "PCS_PH_STATE_CLEAR_FAULTS" 3 "PCS_PH_STATE_ENABLE" 4 "PCS_PH_STATE_FAULT" 1 "PCS_PH_STATE_IDLE" 0 "PCS_PH_STATE_INIT" 2 "PCS_PH_STATE_PRECHARGE" 6 "PCS_PH_STATE_SHUTTING_DOWN";
VAL_ 708 PCS_chgPhCLastShutdownReason 12 "PCS_PH_SHUTDOWN_CONTROL_REGULATION_FAULT" 16 "PCS_PH_SHUTDOWN_FREQ_OUT_OF_RANGE" 2 "PCS_PH_SHUTDOWN_HW_ENABLE" 4 "PCS_PH_SHUTDOWN_HW_FAULT" 7 "PCS_PH_SHUTDOWN_INPUT_OV" 6 "PCS_PH_SHUTDOWN_INPUT_UV" 11 "PCS_PH_SHUTDOWN_INT_BUS_UV" 17 "PCS_PH_SHUTDOWN_LINE_TRANSIENT_FAULT" 9 "PCS_PH_SHUTDOWN_OUTPUT_OV" 8 "PCS_PH_SHUTDOWN_OUTPUT_UV" 13 "PCS_PH_SHUTDOWN_OVER_TEMPERATURE" 5 "PCS_PH_SHUTDOWN_PLL_NOT_LOCKED" 10 "PCS_PH_SHUTDOWN_PRECHARGE_TIMEOUT" 0 "PCS_PH_SHUTDOWN_REASON_NONE" 15 "PCS_PH_SHUTDOWN_SENSOR_IRRATIONAL" 1 "PCS_PH_SHUTDOWN_SW_ENABLE" 3 "PCS_PH_SHUTDOWN_SW_FAULT" 14 "PCS_PH_SHUTDOWN_TEMP_IRRATIONAL";
VAL_ 708 PCS_chgPhCState 5 "PCS_PH_STATE_CLEAR_FAULTS" 3 "PCS_PH_STATE_ENABLE" 4 "PCS_PH_STATE_FAULT" 1 "PCS_PH_STATE_IDLE" 0 "PCS_PH_STATE_INIT" 2 "PCS_PH_STATE_PRECHARGE" 6 "PCS_PH_STATE_SHUTTING_DOWN";
VAL_ 708 PCS_chgPhasesPriority 36 "PHASES_PRIORITY_ABC" 24 "PHASES_PRIORITY_ACB" 33 "PHASES_PRIORITY_BAC" 9 "PHASES_PRIORITY_BCA" 18 "PHASES_PRIORITY_CAB" 6 "PHASES_PRIORITY_CBA" 0 "UNDEFINED_PHASES_PRIORITY";
VAL_ 708 PCS_cpu2BootState 2 "CPU2_STATE_APPLICATION" 1 "CPU2_STATE_BOOTLOADER" 0 "CPU2_STATE_BOOTROM" 3 "CPU2_STATE_ERROR";
VAL_ 708 PCS_dLogPhAChannel1Content 1 "PCS_DLOG_INPUT_CURRENT" 0 "PCS_DLOG_INPUT_VOLTAGE" 3 "PCS_DLOG_INT_BUS_VOLTAGE" 2 "PCS_DLOG_OUTPUT_CURRENT";
VAL_ 708 PCS_dLogPhAChannel2Content 1 "PCS_DLOG_INPUT_CURRENT" 0 "PCS_DLOG_INPUT_VOLTAGE" 3 "PCS_DLOG_INT_BUS_VOLTAGE" 2 "PCS_DLOG_OUTPUT_CURRENT";
VAL_ 708 PCS_dLogPhAChannel3Content 1 "PCS_DLOG_INPUT_CURRENT" 0 "PCS_DLOG_INPUT_VOLTAGE" 3 "PCS_DLOG_INT_BUS_VOLTAGE" 2 "PCS_DLOG_OUTPUT_CURRENT";
VAL_ 708 PCS_dLogPhAChannel4Content 1 "PCS_DLOG_INPUT_CURRENT" 0 "PCS_DLOG_INPUT_VOLTAGE" 3 "PCS_DLOG_INT_BUS_VOLTAGE" 2 "PCS_DLOG_OUTPUT_CURRENT";
VAL_ 708 PCS_dLogPhBChannel1Content 1 "PCS_DLOG_INPUT_CURRENT" 0 "PCS_DLOG_INPUT_VOLTAGE" 3 "PCS_DLOG_INT_BUS_VOLTAGE" 2 "PCS_DLOG_OUTPUT_CURRENT";
VAL_ 708 PCS_dLogPhBChannel2Content 1 "PCS_DLOG_INPUT_CURRENT" 0 "PCS_DLOG_INPUT_VOLTAGE" 3 "PCS_DLOG_INT_BUS_VOLTAGE" 2 "PCS_DLOG_OUTPUT_CURRENT";
VAL_ 708 PCS_dLogPhBChannel3Content 1 "PCS_DLOG_INPUT_CURRENT" 0 "PCS_DLOG_INPUT_VOLTAGE" 3 "PCS_DLOG_INT_BUS_VOLTAGE" 2 "PCS_DLOG_OUTPUT_CURRENT";
VAL_ 708 PCS_dLogPhBChannel4Content 1 "PCS_DLOG_INPUT_CURRENT" 0 "PCS_DLOG_INPUT_VOLTAGE" 3 "PCS_DLOG_INT_BUS_VOLTAGE" 2 "PCS_DLOG_OUTPUT_CURRENT";
VAL_ 708 PCS_dLogPhCChannel1Content 1 "PCS_DLOG_INPUT_CURRENT" 0 "PCS_DLOG_INPUT_VOLTAGE" 3 "PCS_DLOG_INT_BUS_VOLTAGE" 2 "PCS_DLOG_OUTPUT_CURRENT";
VAL_ 708 PCS_dLogPhCChannel2Content 1 "PCS_DLOG_INPUT_CURRENT" 0 "PCS_DLOG_INPUT_VOLTAGE" 3 "PCS_DLOG_INT_BUS_VOLTAGE" 2 "PCS_DLOG_OUTPUT_CURRENT";
VAL_ 708 PCS_dLogPhCChannel3Content 1 "PCS_DLOG_INPUT_CURRENT" 0 "PCS_DLOG_INPUT_VOLTAGE" 3 "PCS_DLOG_INT_BUS_VOLTAGE" 2 "PCS_DLOG_OUTPUT_CURRENT";
VAL_ 708 PCS_dLogPhCChannel4Content 1 "PCS_DLOG_INPUT_CURRENT" 0 "PCS_DLOG_INPUT_VOLTAGE" 3 "PCS_DLOG_INT_BUS_VOLTAGE" 2 "PCS_DLOG_OUTPUT_CURRENT";
VAL_ 708 PCS_dcdcTankVoltage 1024 "TANK_VOLTAGE_SNA";
VAL_ 1493 DI_IGBTJunctTemp 255 "SNA";
VAL_ 1493 DI_torqueWearTotal 255 "SNA";
VAL_ 1366 DIF_IGBTJunctTemp 255 "SNA";
VAL_ 1366 DIF_torqueWearTotal 255 "SNA";
VAL_ 2005 DIR_aebFaultReason 9 "DI_AEB_FAULT_ACCEL_OUT_OF_BOUNDS" 14 "DI_AEB_FAULT_ACCEL_REQ_INVALID" 5 "DI_AEB_FAULT_DAS_CONTROL_MIA" 15 "DI_AEB_FAULT_DAS_REQ_DI_UNAVAIL" 6 "DI_AEB_FAULT_DAS_SNA" 3 "DI_AEB_FAULT_EBR_FAULT" 1 "DI_AEB_FAULT_EPB_MIA" 10 "DI_AEB_FAULT_EPB_NOT_PARKED" 11 "DI_AEB_FAULT_ESP_FAULT" 12 "DI_AEB_FAULT_ESP_MIA" 13 "DI_AEB_FAULT_MIN_TIME_BTWN_EVENTS" 0 "DI_AEB_FAULT_NONE" 2 "DI_AEB_FAULT_PM_MIA" 8 "DI_AEB_FAULT_PM_REQUEST" 4 "DI_AEB_FAULT_SPEED_DELTA" 7 "DI_AEB_FAULT_VEL_EST_ABNORMAL";
VAL_ 2005 DIR_aebUnavailableReason 1 "DI_AEB_UNAVAILABLE_CLOSURE" 5 "DI_AEB_UNAVAILABLE_DI_STATE" 6 "DI_AEB_UNAVAILABLE_EBR_UNAVAILABLE" 7 "DI_AEB_UNAVAILABLE_EPB" 2 "DI_AEB_UNAVAILABLE_GEAR" 8 "DI_AEB_UNAVAILABLE_HYSTERESIS" 4 "DI_AEB_UNAVAILABLE_NEGATIVE_SPEED" 0 "DI_AEB_UNAVAILABLE_NONE" 10 "DI_AEB_UNAVAILABLE_REVERSE_SPEED" 3 "DI_AEB_UNAVAILABLE_SKID" 9 "DI_AEB_UNAVAILABLE_TRACK_MODE";
VAL_ 2005 DIR_brkStState 6 "BRKST_STATE_FINISHED" 1 "BRKST_STATE_IDLE" 5 "BRKST_STATE_INTERRUPTED" 4 "BRKST_STATE_RUNNING_PRESSED" 3 "BRKST_STATE_RUNNING_PRESSING" 2 "BRKST_STATE_RUNNING_UNPRESSED" 0 "BRKST_STATE_UNAVAILABLE";
VAL_ 2005 DIR_fluxState 5 "DI_FLUXSTATE_ENABLED" 9 "DI_FLUXSTATE_FAULT" 4 "DI_FLUXSTATE_FLUX_DOWN" 3 "DI_FLUXSTATE_FLUX_UP" 6 "DI_FLUXSTATE_ICONTROL" 2 "DI_FLUXSTATE_STANDBY" 0 "DI_FLUXSTATE_START" 10 "DI_FLUXSTATE_STATIONARY_WASTE" 1 "DI_FLUXSTATE_TEST" 7 "DI_FLUXSTATE_VCONTROL";
VAL_ 2005 DIR_gateDriveState 3 "PSTG_GD_STATE_CONFIGURED" 2 "PSTG_GD_STATE_CONFIGURING" 0 "PSTG_GD_STATE_INIT" 4 "PSTG_GD_STATE_NOT_CONFIGURED" 1 "PSTG_GD_STATE_SELFTEST";
VAL_ 2005 DIR_gateDriveSupplyState 0 "PSTG_GD_SUPPLY_DOWN" 3 "PSTG_GD_SUPPLY_FALLING" 1 "PSTG_GD_SUPPLY_RISING" 2 "PSTG_GD_SUPPLY_UP";
VAL_ 2005 DIR_immobilizerCondition 1 "DI_IMM_CONDITION_LEARNED" 0 "DI_IMM_CONDITION_VIRGIN_SNA";
VAL_ 2005 DIR_magnetTempEst 0 "SNA";
VAL_ 2005 DIR_motorType 8 "DI_MOTOR_F1A" 10 "DI_MOTOR_F1AC" 11 "DI_MOTOR_F2AB" 12 "DI_MOTOR_F2AC" 13 "DI_MOTOR_F2AD" 14 "DI_MOTOR_F2AE" 26 "DI_MOTOR_F2AE_AL" 15 "DI_MOTOR_F2APMSRM" 17 "DI_MOTOR_IM100A" 19 "DI_MOTOR_IM100B" 22 "DI_MOTOR_IM130C" 24 "DI_MOTOR_IM130D" 25 "DI_MOTOR_IM130D_AL" 27 "DI_MOTOR_IM130D_AL_POSCO" 20 "DI_MOTOR_IM216A" 3 "DI_MOTOR_M7M3" 4 "DI_MOTOR_M7M4" 5 "DI_MOTOR_M7M5" 7 "DI_MOTOR_M7M6" 6 "DI_MOTOR_M8A" 16 "DI_MOTOR_PM216A" 18 "DI_MOTOR_PM216B" 21 "DI_MOTOR_PM216C" 23 "DI_MOTOR_PM216D" 28 "DI_MOTOR_PM275B" 1 "DI_MOTOR_ROADSTER_BASE" 2 "DI_MOTOR_ROADSTER_SPORT" 0 "DI_MOTOR_SNA" 9 "DI_MOTOR_SSR1A";
VAL_ 2005 DIR_oilPumpPhaseVoltage 255 "SNA";
VAL_ 2005 DIR_oilPumpPressureEstimateMax 255 "SNA";
VAL_ 2005 DIR_oilPumpPressureExpectedMin 255 "SNA";
VAL_ 2005 DIR_opdUnavailableReason 1 "DI_OPD_UNAVAILABLE_DISABLED" 4 "DI_OPD_UNAVAILABLE_DI_SYS_STATE" 7 "DI_OPD_UNAVAILABLE_EPB_FAULT" 3 "DI_OPD_UNAVAILABLE_GEAR" 11 "DI_OPD_UNAVAILABLE_GRADE_ESTIMATE" 5 "DI_OPD_UNAVAILABLE_INVALID_BRAKE_SENSE" 14 "DI_OPD_UNAVAILABLE_INVALID_MSPD" 15 "DI_OPD_UNAVAILABLE_MOTOR_HOLD_TIMEOUT" 0 "DI_OPD_UNAVAILABLE_NONE" 13 "DI_OPD_UNAVAILABLE_PARKED" 2 "DI_OPD_UNAVAILABLE_PM_FAULT" 6 "DI_OPD_UNAVAILABLE_SKID" 12 "DI_OPD_UNAVAILABLE_TORQUE_LIMIT" 8 "DI_OPD_UNAVAILABLE_TRACK_MODE" 10 "DI_OPD_UNAVAILABLE_TRACTION_CONTROL" 9 "DI_OPD_UNAVAILABLE_VELOCITY_ESTIMATE";
VAL_ 2005 DIR_powerStageSafeState 2 "PSTG_SAFESTATE_3PS_HIGH" 3 "PSTG_SAFESTATE_3PS_LOW" 1 "PSTG_SAFESTATE_ALL_OFF" 0 "PSTG_SAFESTATE_NONE";
VAL_ 2005 DIR_rotorOffsetLearningState 9 "ROL_NUM_STATES" 2 "ROL_STATE_ACCELERATE" 5 "ROL_STATE_CORRECT" 8 "ROL_STATE_DONE" 0 "ROL_STATE_INIT" 4 "ROL_STATE_MEASURE" 3 "ROL_STATE_SHIFT" 6 "ROL_STATE_VERIFY" 1 "ROL_STATE_WAIT" 7 "ROL_STATE_WRITE";
VAL_ 2005 DIR_ssmState 5 "SSM_STATE_ABORT" 4 "SSM_STATE_ENABLE" 8 "SSM_STATE_FAULT" 2 "SSM_STATE_IDLE" 7 "SSM_STATE_RETRY" 3 "SSM_STATE_STANDBY" 0 "SSM_STATE_START" 1 "SSM_STATE_UNAVAILABLE" 6 "SSM_STATE_WAIT_FOR_RETRY";
VAL_ 2005 DIR_tcMaxRequest 255 "SNA";
VAL_ 2005 DIR_tcMinRequest 255 "SNA";
VAL_ 2005 DIR_usmState 3 "USM_STATE_ABORT" 4 "USM_STATE_ENABLE" 5 "USM_STATE_FAULT" 2 "USM_STATE_RETRY" 1 "USM_STATE_STANDBY" 0 "USM_STATE_START" 6 "USM_STATE_UNAVAILABLE" 7 "USM_STATE_WAIT_FOR_RETRY";
VAL_ 2005 DIR_velocityEstimatorState 4 "VE_STATE_BACKUP_MOTOR" 2 "VE_STATE_BACKUP_WHEELS_A" 3 "VE_STATE_BACKUP_WHEELS_B" 0 "VE_STATE_NOT_INITIALIZED" 1 "VE_STATE_WHEELS_NORMAL";
VAL_ 1879 DIF_aebFaultReason 9 "DI_AEB_FAULT_ACCEL_OUT_OF_BOUNDS" 14 "DI_AEB_FAULT_ACCEL_REQ_INVALID" 5 "DI_AEB_FAULT_DAS_CONTROL_MIA" 15 "DI_AEB_FAULT_DAS_REQ_DI_UNAVAIL" 6 "DI_AEB_FAULT_DAS_SNA" 3 "DI_AEB_FAULT_EBR_FAULT" 1 "DI_AEB_FAULT_EPB_MIA" 10 "DI_AEB_FAULT_EPB_NOT_PARKED" 11 "DI_AEB_FAULT_ESP_FAULT" 12 "DI_AEB_FAULT_ESP_MIA" 13 "DI_AEB_FAULT_MIN_TIME_BTWN_EVENTS" 0 "DI_AEB_FAULT_NONE" 2 "DI_AEB_FAULT_PM_MIA" 8 "DI_AEB_FAULT_PM_REQUEST" 4 "DI_AEB_FAULT_SPEED_DELTA" 7 "DI_AEB_FAULT_VEL_EST_ABNORMAL";
VAL_ 1879 DIF_aebUnavailableReason 1 "DI_AEB_UNAVAILABLE_CLOSURE" 5 "DI_AEB_UNAVAILABLE_DI_STATE" 6 "DI_AEB_UNAVAILABLE_EBR_UNAVAILABLE" 7 "DI_AEB_UNAVAILABLE_EPB" 2 "DI_AEB_UNAVAILABLE_GEAR" 8 "DI_AEB_UNAVAILABLE_HYSTERESIS" 4 "DI_AEB_UNAVAILABLE_NEGATIVE_SPEED" 0 "DI_AEB_UNAVAILABLE_NONE" 10 "DI_AEB_UNAVAILABLE_REVERSE_SPEED" 3 "DI_AEB_UNAVAILABLE_SKID" 9 "DI_AEB_UNAVAILABLE_TRACK_MODE";
VAL_ 1879 DIF_brkStState 6 "BRKST_STATE_FINISHED" 1 "BRKST_STATE_IDLE" 5 "BRKST_STATE_INTERRUPTED" 4 "BRKST_STATE_RUNNING_PRESSED" 3 "BRKST_STATE_RUNNING_PRESSING" 2 "BRKST_STATE_RUNNING_UNPRESSED" 0 "BRKST_STATE_UNAVAILABLE";
VAL_ 1879 DIF_fluxState 5 "DI_FLUXSTATE_ENABLED" 9 "DI_FLUXSTATE_FAULT" 4 "DI_FLUXSTATE_FLUX_DOWN" 3 "DI_FLUXSTATE_FLUX_UP" 6 "DI_FLUXSTATE_ICONTROL" 2 "DI_FLUXSTATE_STANDBY" 0 "DI_FLUXSTATE_START" 10 "DI_FLUXSTATE_STATIONARY_WASTE" 1 "DI_FLUXSTATE_TEST" 7 "DI_FLUXSTATE_VCONTROL";
VAL_ 1879 DIF_gateDriveState 3 "PSTG_GD_STATE_CONFIGURED" 2 "PSTG_GD_STATE_CONFIGURING" 0 "PSTG_GD_STATE_INIT" 4 "PSTG_GD_STATE_NOT_CONFIGURED" 1 "PSTG_GD_STATE_SELFTEST";
VAL_ 1879 DIF_gateDriveSupplyState 0 "PSTG_GD_SUPPLY_DOWN" 3 "PSTG_GD_SUPPLY_FALLING" 1 "PSTG_GD_SUPPLY_RISING" 2 "PSTG_GD_SUPPLY_UP";
VAL_ 1879 DIF_immobilizerCondition 1 "DI_IMM_CONDITION_LEARNED" 0 "DI_IMM_CONDITION_VIRGIN_SNA";
VAL_ 1879 DIF_magnetTempEst 0 "SNA";
VAL_ 1879 DIF_motorType 8 "DI_MOTOR_F1A" 10 "DI_MOTOR_F1AC" 11 "DI_MOTOR_F2AB" 12 "DI_MOTOR_F2AC" 13 "DI_MOTOR_F2AD" 14 "DI_MOTOR_F2AE" 26 "DI_MOTOR_F2AE_AL" 15 "DI_MOTOR_F2APMSRM" 17 "DI_MOTOR_IM100A" 19 "DI_MOTOR_IM100B" 22 "DI_MOTOR_IM130C" 24 "DI_MOTOR_IM130D" 25 "DI_MOTOR_IM130D_AL" 27 "DI_MOTOR_IM130D_AL_POSCO" 20 "DI_MOTOR_IM216A" 3 "DI_MOTOR_M7M3" 4 "DI_MOTOR_M7M4" 5 "DI_MOTOR_M7M5" 7 "DI_MOTOR_M7M6" 6 "DI_MOTOR_M8A" 16 "DI_MOTOR_PM216A" 18 "DI_MOTOR_PM216B" 21 "DI_MOTOR_PM216C" 23 "DI_MOTOR_PM216D" 28 "DI_MOTOR_PM275B" 1 "DI_MOTOR_ROADSTER_BASE" 2 "DI_MOTOR_ROADSTER_SPORT" 0 "DI_MOTOR_SNA" 9 "DI_MOTOR_SSR1A";
VAL_ 1879 DIF_oilPumpPhaseVoltage 255 "SNA";
VAL_ 1879 DIF_oilPumpPressureEstimateMax 255 "SNA";
VAL_ 1879 DIF_oilPumpPressureExpectedMin 255 "SNA";
VAL_ 1879 DIF_opdUnavailableReason 1 "DI_OPD_UNAVAILABLE_DISABLED" 4 "DI_OPD_UNAVAILABLE_DI_SYS_STATE" 7 "DI_OPD_UNAVAILABLE_EPB_FAULT" 3 "DI_OPD_UNAVAILABLE_GEAR" 11 "DI_OPD_UNAVAILABLE_GRADE_ESTIMATE" 5 "DI_OPD_UNAVAILABLE_INVALID_BRAKE_SENSE" 14 "DI_OPD_UNAVAILABLE_INVALID_MSPD" 15 "DI_OPD_UNAVAILABLE_MOTOR_HOLD_TIMEOUT" 0 "DI_OPD_UNAVAILABLE_NONE" 13 "DI_OPD_UNAVAILABLE_PARKED" 2 "DI_OPD_UNAVAILABLE_PM_FAULT" 6 "DI_OPD_UNAVAILABLE_SKID" 12 "DI_OPD_UNAVAILABLE_TORQUE_LIMIT" 8 "DI_OPD_UNAVAILABLE_TRACK_MODE" 10 "DI_OPD_UNAVAILABLE_TRACTION_CONTROL" 9 "DI_OPD_UNAVAILABLE_VELOCITY_ESTIMATE";
VAL_ 1879 DIF_powerStageSafeState 2 "PSTG_SAFESTATE_3PS_HIGH" 3 "PSTG_SAFESTATE_3PS_LOW" 1 "PSTG_SAFESTATE_ALL_OFF" 0 "PSTG_SAFESTATE_NONE";
VAL_ 1879 DIF_rotorOffsetLearningState 9 "ROL_NUM_STATES" 2 "ROL_STATE_ACCELERATE" 5 "ROL_STATE_CORRECT" 8 "ROL_STATE_DONE" 0 "ROL_STATE_INIT" 4 "ROL_STATE_MEASURE" 3 "ROL_STATE_SHIFT" 6 "ROL_STATE_VERIFY" 1 "ROL_STATE_WAIT" 7 "ROL_STATE_WRITE";
VAL_ 1879 DIF_ssmState 5 "SSM_STATE_ABORT" 4 "SSM_STATE_ENABLE" 8 "SSM_STATE_FAULT" 2 "SSM_STATE_IDLE" 7 "SSM_STATE_RETRY" 3 "SSM_STATE_STANDBY" 0 "SSM_STATE_START" 1 "SSM_STATE_UNAVAILABLE" 6 "SSM_STATE_WAIT_FOR_RETRY";
VAL_ 1879 DIF_tcMaxRequest 255 "SNA";
VAL_ 1879 DIF_tcMinRequest 255 "SNA";
VAL_ 1879 DIF_usmState 3 "USM_STATE_ABORT" 4 "USM_STATE_ENABLE" 5 "USM_STATE_FAULT" 2 "USM_STATE_RETRY" 1 "USM_STATE_STANDBY" 0 "USM_STATE_START" 6 "USM_STATE_UNAVAILABLE" 7 "USM_STATE_WAIT_FOR_RETRY";
VAL_ 1879 DIF_velocityEstimatorState 4 "VE_STATE_BACKUP_MOTOR" 2 "VE_STATE_BACKUP_WHEELS_A" 3 "VE_STATE_BACKUP_WHEELS_B" 0 "VE_STATE_NOT_INITIALIZED" 1 "VE_STATE_WHEELS_NORMAL";
VAL_ 694 DI_ptcStateUI 0 "FAULTED" 1 "BACKUP" 2 "ON" 3 "SNA";
VAL_ 694 DI_tractionControlModeUI 0 "NORMAL" 1 "SLIP_START" 2 "DEV_MODE_1" 3 "DEV_MODE_2" 4 "ROLLS_MODE" 5 "DYNO_MODE" 6 "OFFROAD_ASSIST";
VAL_ 545 VCFRONT_LVPowerStateIndex 0 "Mux0" 1 "Mux1";
VAL_ 545 VCFRONT_CMPDLVState 3 "LV_FAULT" 2 "LV_GOING_DOWN" 0 "LV_OFF" 1 "LV_ON";
VAL_ 545 VCFRONT_amplifierLVRequest 3 "LV_FAULT" 2 "LV_GOING_DOWN" 0 "LV_OFF" 1 "LV_ON";
VAL_ 545 VCFRONT_cpLVRequest 3 "LV_FAULT" 2 "LV_GOING_DOWN" 0 "LV_OFF" 1 "LV_ON";
VAL_ 545 VCFRONT_das1HighCurrentLVState 3 "LV_FAULT" 2 "LV_GOING_DOWN" 0 "LV_OFF" 1 "LV_ON";
VAL_ 545 VCFRONT_das2HighCurrentLVState 3 "LV_FAULT" 2 "LV_GOING_DOWN" 0 "LV_OFF" 1 "LV_ON";
VAL_ 545 VCFRONT_difLVState 3 "LV_FAULT" 2 "LV_GOING_DOWN" 0 "LV_OFF" 1 "LV_ON";
VAL_ 545 VCFRONT_dirLVRequest 3 "LV_FAULT" 2 "LV_GOING_DOWN" 0 "LV_OFF" 1 "LV_ON";
VAL_ 545 VCFRONT_epasLVState 3 "LV_FAULT" 2 "LV_GOING_DOWN" 0 "LV_OFF" 1 "LV_ON";
VAL_ 545 VCFRONT_espLVState 3 "LV_FAULT" 2 "LV_GOING_DOWN" 0 "LV_OFF" 1 "LV_ON";
VAL_ 545 VCFRONT_hvacCompLVState 3 "LV_FAULT" 2 "LV_GOING_DOWN" 0 "LV_OFF" 1 "LV_ON";
VAL_ 545 VCFRONT_hvcLVRequest 3 "LV_FAULT" 2 "LV_GOING_DOWN" 0 "LV_OFF" 1 "LV_ON";
VAL_ 545 VCFRONT_iBoosterLVState 3 "LV_FAULT" 2 "LV_GOING_DOWN" 0 "LV_OFF" 1 "LV_ON";
VAL_ 545 VCFRONT_ocsLVRequest 3 "LV_FAULT" 2 "LV_GOING_DOWN" 0 "LV_OFF" 1 "LV_ON";
VAL_ 545 VCFRONT_oilPumpFrontLVState 3 "LV_FAULT" 2 "LV_GOING_DOWN" 0 "LV_OFF" 1 "LV_ON";
VAL_ 545 VCFRONT_oilPumpRearLVRequest 3 "LV_FAULT" 2 "LV_GOING_DOWN" 0 "LV_OFF" 1 "LV_ON";
VAL_ 545 VCFRONT_parkLVState 3 "LV_FAULT" 2 "LV_GOING_DOWN" 0 "LV_OFF" 1 "LV_ON";
VAL_ 545 VCFRONT_pcsLVState 3 "LV_FAULT" 2 "LV_GOING_DOWN" 0 "LV_OFF" 1 "LV_ON";
VAL_ 545 VCFRONT_ptcLVRequest 3 "LV_FAULT" 2 "LV_GOING_DOWN" 0 "LV_OFF" 1 "LV_ON";
VAL_ 545 VCFRONT_radcLVState 3 "LV_FAULT" 2 "LV_GOING_DOWN" 0 "LV_OFF" 1 "LV_ON";
VAL_ 545 VCFRONT_rcmLVRequest 3 "LV_FAULT" 2 "LV_GOING_DOWN" 0 "LV_OFF" 1 "LV_ON";
VAL_ 545 VCFRONT_sccmLVRequest 3 "LV_FAULT" 2 "LV_GOING_DOWN" 0 "LV_OFF" 1 "LV_ON";
VAL_ 545 VCFRONT_tasLVState 3 "LV_FAULT" 2 "LV_GOING_DOWN" 0 "LV_OFF" 1 "LV_ON";
VAL_ 545 VCFRONT_tpmsLVRequest 3 "LV_FAULT" 2 "LV_GOING_DOWN" 0 "LV_OFF" 1 "LV_ON";
VAL_ 545 VCFRONT_tunerLVRequest 3 "LV_FAULT" 2 "LV_GOING_DOWN" 0 "LV_OFF" 1 "LV_ON";
VAL_ 545 VCFRONT_uiHiCurrentLVState 3 "LV_FAULT" 2 "LV_GOING_DOWN" 0 "LV_OFF" 1 "LV_ON";
VAL_ 545 VCFRONT_vcleftHiCurrentLVState 3 "LV_FAULT" 2 "LV_GOING_DOWN" 0 "LV_OFF" 1 "LV_ON";
VAL_ 545 VCFRONT_vcrightHiCurrentLVState 3 "LV_FAULT" 2 "LV_GOING_DOWN" 0 "LV_OFF" 1 "LV_ON";
VAL_ 753 VCFRONT_eFuseDebugStatusIndex 8 "VCF_DBG_STS_AUTOPILOT_1" 9 "VCF_DBG_STS_AUTOPILOT_2" 4 "VCF_DBG_STS_EPAS3P" 5 "VCF_DBG_STS_EPAS3S" 6 "VCF_DBG_STS_ESP_MOTOR" 7 "VCF_DBG_STS_ESP_VALVE" 12 "VCF_DBG_STS_HEADLAMPS" 3 "VCF_DBG_STS_IBOOSTER" 18 "VCF_DBG_STS_INVALID" 17 "VCF_DBG_STS_LV_BATTERY_DEBUG" 16 "VCF_DBG_STS_MISC_RAILS" 2 "VCF_DBG_STS_PCS" 14 "VCF_DBG_STS_PUMPS" 15 "VCF_DBG_STS_RAILS_A_B" 10 "VCF_DBG_STS_SLEEP_BYPASS" 11 "VCF_DBG_STS_UI" 13 "VCF_DBG_STS_VBAT_FUSED_HIGH_CURRENT" 1 "VCF_DBG_STS_VCLEFT" 0 "VCF_DBG_STS_VCRIGHT";
VAL_ 753 VCFRONT_EPAS3PSelfTestResult 4 "EFUSE_SELF_TEST_EFUSE_RESULT_FAILED_EFUSE_OUTPUT_SHORT" 8 "EFUSE_SELF_TEST_EFUSE_RESULT_FAILED_ENABLE_HIGH_MALFUNCTION" 6 "EFUSE_SELF_TEST_EFUSE_RESULT_FAILED_ENABLE_LOW_MALFUNCTION" 10 "EFUSE_SELF_TEST_EFUSE_RESULT_FAILED_NOT_LATCHED" 7 "EFUSE_SELF_TEST_EFUSE_RESULT_FAILED_POWER_FET_CHANNEL_OPEN" 5 "EFUSE_SELF_TEST_EFUSE_RESULT_FAILED_POWER_FET_STUCK_ON" 3 "EFUSE_SELF_TEST_EFUSE_RESULT_FAILED_RAILS_UNSTABLE" 9 "EFUSE_SELF_TEST_EFUSE_RESULT_FAILED_TURN_OFF_PATH_TOO_SLOW" 0 "EFUSE_SELF_TEST_EFUSE_RESULT_NOT_RUN" 2 "EFUSE_SELF_TEST_EFUSE_RESULT_PASSED" 1 "EFUSE_SELF_TEST_EFUSE_RESULT_RUNNING" 11 "EFUSE_SELF_TEST_EFUSE_RESULT_SKIPPED";
VAL_ 753 VCFRONT_EPAS3PState 2 "EFUSE_STATE_LOCKED_OUT" 0 "EFUSE_STATE_OFF" 1 "EFUSE_STATE_ON";
VAL_ 753 VCFRONT_EPAS3SSelfTestResult 4 "EFUSE_SELF_TEST_EFUSE_RESULT_FAILED_EFUSE_OUTPUT_SHORT" 8 "EFUSE_SELF_TEST_EFUSE_RESULT_FAILED_ENABLE_HIGH_MALFUNCTION" 6 "EFUSE_SELF_TEST_EFUSE_RESULT_FAILED_ENABLE_LOW_MALFUNCTION" 10 "EFUSE_SELF_TEST_EFUSE_RESULT_FAILED_NOT_LATCHED" 7 "EFUSE_SELF_TEST_EFUSE_RESULT_FAILED_POWER_FET_CHANNEL_OPEN" 5 "EFUSE_SELF_TEST_EFUSE_RESULT_FAILED_POWER_FET_STUCK_ON" 3 "EFUSE_SELF_TEST_EFUSE_RESULT_FAILED_RAILS_UNSTABLE" 9 "EFUSE_SELF_TEST_EFUSE_RESULT_FAILED_TURN_OFF_PATH_TOO_SLOW" 0 "EFUSE_SELF_TEST_EFUSE_RESULT_NOT_RUN" 2 "EFUSE_SELF_TEST_EFUSE_RESULT_PASSED" 1 "EFUSE_SELF_TEST_EFUSE_RESULT_RUNNING" 11 "EFUSE_SELF_TEST_EFUSE_RESULT_SKIPPED";
VAL_ 753 VCFRONT_EPAS3SState 2 "EFUSE_STATE_LOCKED_OUT" 0 "EFUSE_STATE_OFF" 1 "EFUSE_STATE_ON";
VAL_ 753 VCFRONT_ESPMotorSelfTestResult 4 "EFUSE_SELF_TEST_EFUSE_RESULT_FAILED_EFUSE_OUTPUT_SHORT" 8 "EFUSE_SELF_TEST_EFUSE_RESULT_FAILED_ENABLE_HIGH_MALFUNCTION" 6 "EFUSE_SELF_TEST_EFUSE_RESULT_FAILED_ENABLE_LOW_MALFUNCTION" 10 "EFUSE_SELF_TEST_EFUSE_RESULT_FAILED_NOT_LATCHED" 7 "EFUSE_SELF_TEST_EFUSE_RESULT_FAILED_POWER_FET_CHANNEL_OPEN" 5 "EFUSE_SELF_TEST_EFUSE_RESULT_FAILED_POWER_FET_STUCK_ON" 3 "EFUSE_SELF_TEST_EFUSE_RESULT_FAILED_RAILS_UNSTABLE" 9 "EFUSE_SELF_TEST_EFUSE_RESULT_FAILED_TURN_OFF_PATH_TOO_SLOW" 0 "EFUSE_SELF_TEST_EFUSE_RESULT_NOT_RUN" 2 "EFUSE_SELF_TEST_EFUSE_RESULT_PASSED" 1 "EFUSE_SELF_TEST_EFUSE_RESULT_RUNNING" 11 "EFUSE_SELF_TEST_EFUSE_RESULT_SKIPPED";
VAL_ 753 VCFRONT_ESPMotorState 2 "EFUSE_STATE_LOCKED_OUT" 0 "EFUSE_STATE_OFF" 1 "EFUSE_STATE_ON";
VAL_ 753 VCFRONT_ESPValveState 2 "EFUSE_STATE_LOCKED_OUT" 0 "EFUSE_STATE_OFF" 1 "EFUSE_STATE_ON";
VAL_ 753 VCFRONT_PCSState 2 "EFUSE_STATE_LOCKED_OUT" 0 "EFUSE_STATE_OFF" 1 "EFUSE_STATE_ON";
VAL_ 753 VCFRONT_autopilot1State 2 "EFUSE_STATE_LOCKED_OUT" 0 "EFUSE_STATE_OFF" 1 "EFUSE_STATE_ON";
VAL_ 753 VCFRONT_autopilot2State 2 "EFUSE_STATE_LOCKED_OUT" 0 "EFUSE_STATE_OFF" 1 "EFUSE_STATE_ON";
VAL_ 753 VCFRONT_headlampLeftTemperature 128 "SNA";
VAL_ 753 VCFRONT_headlampLeftVoltage 255 "SNA";
VAL_ 753 VCFRONT_headlampRightTemperature 128 "SNA";
VAL_ 753 VCFRONT_headlampRightVoltage 255 "SNA";
VAL_ 753 VCFRONT_iBoosterSelfTestResult 4 "EFUSE_SELF_TEST_EFUSE_RESULT_FAILED_EFUSE_OUTPUT_SHORT" 8 "EFUSE_SELF_TEST_EFUSE_RESULT_FAILED_ENABLE_HIGH_MALFUNCTION" 6 "EFUSE_SELF_TEST_EFUSE_RESULT_FAILED_ENABLE_LOW_MALFUNCTION" 10 "EFUSE_SELF_TEST_EFUSE_RESULT_FAILED_NOT_LATCHED" 7 "EFUSE_SELF_TEST_EFUSE_RESULT_FAILED_POWER_FET_CHANNEL_OPEN" 5 "EFUSE_SELF_TEST_EFUSE_RESULT_FAILED_POWER_FET_STUCK_ON" 3 "EFUSE_SELF_TEST_EFUSE_RESULT_FAILED_RAILS_UNSTABLE" 9 "EFUSE_SELF_TEST_EFUSE_RESULT_FAILED_TURN_OFF_PATH_TOO_SLOW" 0 "EFUSE_SELF_TEST_EFUSE_RESULT_NOT_RUN" 2 "EFUSE_SELF_TEST_EFUSE_RESULT_PASSED" 1 "EFUSE_SELF_TEST_EFUSE_RESULT_RUNNING" 11 "EFUSE_SELF_TEST_EFUSE_RESULT_SKIPPED";
VAL_ 753 VCFRONT_iBoosterState 2 "EFUSE_STATE_LOCKED_OUT" 0 "EFUSE_STATE_OFF" 1 "EFUSE_STATE_ON";
VAL_ 753 VCFRONT_leftControllerState 2 "EFUSE_STATE_LOCKED_OUT" 0 "EFUSE_STATE_OFF" 1 "EFUSE_STATE_ON";
VAL_ 753 VCFRONT_pcsSelfTestResult 4 "EFUSE_SELF_TEST_EFUSE_RESULT_FAILED_EFUSE_OUTPUT_SHORT" 8 "EFUSE_SELF_TEST_EFUSE_RESULT_FAILED_ENABLE_HIGH_MALFUNCTION" 6 "EFUSE_SELF_TEST_EFUSE_RESULT_FAILED_ENABLE_LOW_MALFUNCTION" 10 "EFUSE_SELF_TEST_EFUSE_RESULT_FAILED_NOT_LATCHED" 7 "EFUSE_SELF_TEST_EFUSE_RESULT_FAILED_POWER_FET_CHANNEL_OPEN" 5 "EFUSE_SELF_TEST_EFUSE_RESULT_FAILED_POWER_FET_STUCK_ON" 3 "EFUSE_SELF_TEST_EFUSE_RESULT_FAILED_RAILS_UNSTABLE" 9 "EFUSE_SELF_TEST_EFUSE_RESULT_FAILED_TURN_OFF_PATH_TOO_SLOW" 0 "EFUSE_SELF_TEST_EFUSE_RESULT_NOT_RUN" 2 "EFUSE_SELF_TEST_EFUSE_RESULT_PASSED" 1 "EFUSE_SELF_TEST_EFUSE_RESULT_RUNNING" 11 "EFUSE_SELF_TEST_EFUSE_RESULT_SKIPPED";
VAL_ 753 VCFRONT_rightControllerState 2 "EFUSE_STATE_LOCKED_OUT" 0 "EFUSE_STATE_OFF" 1 "EFUSE_STATE_ON";
VAL_ 753 VCFRONT_vbatFusedSelfTestResult 4 "EFUSE_SELF_TEST_EFUSE_RESULT_FAILED_EFUSE_OUTPUT_SHORT" 8 "EFUSE_SELF_TEST_EFUSE_RESULT_FAILED_ENABLE_HIGH_MALFUNCTION" 6 "EFUSE_SELF_TEST_EFUSE_RESULT_FAILED_ENABLE_LOW_MALFUNCTION" 10 "EFUSE_SELF_TEST_EFUSE_RESULT_FAILED_NOT_LATCHED" 7 "EFUSE_SELF_TEST_EFUSE_RESULT_FAILED_POWER_FET_CHANNEL_OPEN" 5 "EFUSE_SELF_TEST_EFUSE_RESULT_FAILED_POWER_FET_STUCK_ON" 3 "EFUSE_SELF_TEST_EFUSE_RESULT_FAILED_RAILS_UNSTABLE" 9 "EFUSE_SELF_TEST_EFUSE_RESULT_FAILED_TURN_OFF_PATH_TOO_SLOW" 0 "EFUSE_SELF_TEST_EFUSE_RESULT_NOT_RUN" 2 "EFUSE_SELF_TEST_EFUSE_RESULT_PASSED" 1 "EFUSE_SELF_TEST_EFUSE_RESULT_RUNNING" 11 "EFUSE_SELF_TEST_EFUSE_RESULT_SKIPPED";
VAL_ 753 VCFRONT_vcleftSelfTestResult 4 "EFUSE_SELF_TEST_EFUSE_RESULT_FAILED_EFUSE_OUTPUT_SHORT" 8 "EFUSE_SELF_TEST_EFUSE_RESULT_FAILED_ENABLE_HIGH_MALFUNCTION" 6 "EFUSE_SELF_TEST_EFUSE_RESULT_FAILED_ENABLE_LOW_MALFUNCTION" 10 "EFUSE_SELF_TEST_EFUSE_RESULT_FAILED_NOT_LATCHED" 7 "EFUSE_SELF_TEST_EFUSE_RESULT_FAILED_POWER_FET_CHANNEL_OPEN" 5 "EFUSE_SELF_TEST_EFUSE_RESULT_FAILED_POWER_FET_STUCK_ON" 3 "EFUSE_SELF_TEST_EFUSE_RESULT_FAILED_RAILS_UNSTABLE" 9 "EFUSE_SELF_TEST_EFUSE_RESULT_FAILED_TURN_OFF_PATH_TOO_SLOW" 0 "EFUSE_SELF_TEST_EFUSE_RESULT_NOT_RUN" 2 "EFUSE_SELF_TEST_EFUSE_RESULT_PASSED" 1 "EFUSE_SELF_TEST_EFUSE_RESULT_RUNNING" 11 "EFUSE_SELF_TEST_EFUSE_RESULT_SKIPPED";
VAL_ 753 VCFRONT_vcrightSelfTestResult 4 "EFUSE_SELF_TEST_EFUSE_RESULT_FAILED_EFUSE_OUTPUT_SHORT" 8 "EFUSE_SELF_TEST_EFUSE_RESULT_FAILED_ENABLE_HIGH_MALFUNCTION" 6 "EFUSE_SELF_TEST_EFUSE_RESULT_FAILED_ENABLE_LOW_MALFUNCTION" 10 "EFUSE_SELF_TEST_EFUSE_RESULT_FAILED_NOT_LATCHED" 7 "EFUSE_SELF_TEST_EFUSE_RESULT_FAILED_POWER_FET_CHANNEL_OPEN" 5 "EFUSE_SELF_TEST_EFUSE_RESULT_FAILED_POWER_FET_STUCK_ON" 3 "EFUSE_SELF_TEST_EFUSE_RESULT_FAILED_RAILS_UNSTABLE" 9 "EFUSE_SELF_TEST_EFUSE_RESULT_FAILED_TURN_OFF_PATH_TOO_SLOW" 0 "EFUSE_SELF_TEST_EFUSE_RESULT_NOT_RUN" 2 "EFUSE_SELF_TEST_EFUSE_RESULT_PASSED" 1 "EFUSE_SELF_TEST_EFUSE_RESULT_RUNNING" 11 "EFUSE_SELF_TEST_EFUSE_RESULT_SKIPPED";
VAL_ 579 VCRIGHT_hvacStatusIndex 3 "END" 0 "STATUS_UI" 1 "STATUS_VCFRONT" 2 "STATUS_VCFRONT2";
VAL_ 579 VCRIGHT_hvacACRunning 0 "OFF" 1 "ON";
VAL_ 579 VCRIGHT_hvacAirDistributionMode 4 "DEFROST" 5 "DEFROST_FLOOR" 6 "DEFROST_PANEL" 7 "DEFROST_PANEL_FLOOR" 1 "FLOOR" 0 "NONE" 2 "PANEL" 3 "PANEL_FLOOR";
VAL_ 579 VCRIGHT_hvacBlowerSegment 1 "1" 10 "10" 11 "11" 2 "2" 3 "3" 4 "4" 5 "5" 6 "6" 7 "7" 8 "8" 9 "9" 0 "OFF";
VAL_ 579 VCRIGHT_hvacDuctTargetLeft 255 "SNA";
VAL_ 579 VCRIGHT_hvacDuctTargetRight 255 "SNA";
VAL_ 579 VCRIGHT_hvacModelInitStatus 4 "INIT_FORWARD_CALC" 2 "INIT_FROM_SENSORS" 3 "INIT_FROM_SENSORS_PREDICTION_ERROR" 5 "INIT_WAITING_FOR_SENSORS" 1 "NOT_INIT_WAIT_FOR_GTW" 0 "NOT_INIT_WAIT_FOR_SENSORS";
VAL_ 579 VCRIGHT_hvacPowerState 0 "OFF" 1 "ON" 4 "OVERHEAT_PROTECT" 3 "OVERHEAT_PROTECT_FANONLY" 2 "PRECONDITION";
VAL_ 579 VCRIGHT_hvacRecirc 0 "AUTO" 2 "FRESH" 1 "RECIRC";
VAL_ 579 VCRIGHT_hvacSecondRowState 0 "AUTO" 4 "HIGH" 2 "LOW" 3 "MED" 1 "OFF";
VAL_ 579 VCRIGHT_hvacVentStatus 0 "BOTH" 1 "LEFT" 2 "RIGHT";
VAL_ 579 VCRIGHT_tempDuctLeft 255 "SNA";
VAL_ 579 VCRIGHT_tempDuctLeftLower 255 "SNA";
VAL_ 579 VCRIGHT_tempDuctLeftUpper 255 "SNA";
VAL_ 579 VCRIGHT_tempDuctRight 255 "SNA";
VAL_ 579 VCRIGHT_tempDuctRightLower 255 "SNA";
VAL_ 579 VCRIGHT_tempDuctRightUpper 255 "SNA";
VAL_ 524 VCRIGHT_hvacPerfTestState 2 "BLOWING" 0 "STOPPED" 1 "WAITING";
VAL_ 524 VCRIGHT_tempAmbientRaw 0 "SNA";
VAL_ 524 VCRIGHT_tempEvaporator 2047 "SNA";
VAL_ 524 VCRIGHT_tempEvaporatorTarget 255 "SNA";
VAL_ 691 VCRIGHT_logging1HzIndex 11 "END" 5 "HEATER_AND_DUCT_TARGETS" 7 "HVAC_ACTUATOR_ENDSTOP" 6 "HVAC_ACTUATOR_VOLTAGES" 8 "HVAC_ACTUATOR_ZEROSTOP" 4 "HVAC_COMFORT_SOLAR" 2 "HVAC_HUMIDITY_HEATER_TEMP" 9 "HVAC_MISCELLANEOUS_1" 10 "HVAC_MISCELLANEOUS_2" 3 "HVAC_STATUS_AIRFLOW" 0 "HVAC_TEMP_SENSORS_AND_ESTIMATES_1" 1 "HVAC_TEMP_SENSORS_AND_ESTIMATES_2";
VAL_ 691 VCRIGHT_cabinTempBreathLevel 255 "SNA";
VAL_ 691 VCRIGHT_cabinTempGlassRoof 255 "SNA";
VAL_ 691 VCRIGHT_cabinTempInterior 240 "SNA";
VAL_ 691 VCRIGHT_cabinTempInteriorL2 240 "SNA";
VAL_ 691 VCRIGHT_cabinTempInteriorL3 240 "SNA";
VAL_ 691 VCRIGHT_cabinTempInteriorSunny 240 "SNA";
VAL_ 691 VCRIGHT_cabinTempInteriorSunnyL2 240 "SNA";
VAL_ 691 VCRIGHT_cabinTempInteriorSunnyL3 240 "SNA";
VAL_ 691 VCRIGHT_cabinTempSideGlassLeft 255 "SNA";
VAL_ 691 VCRIGHT_cabinTempSideGlassRight 255 "SNA";
VAL_ 691 VCRIGHT_cabinTempTopPadAir 240 "SNA";
VAL_ 691 VCRIGHT_cabinTempWindshield 255 "SNA";
VAL_ 691 VCRIGHT_convectionDeliveredLeft 255 "SNA";
VAL_ 691 VCRIGHT_convectionDeliveredRight 255 "SNA";
VAL_ 691 VCRIGHT_convectionTargetLeft 255 "SNA";
VAL_ 691 VCRIGHT_convectionTargetRight 255 "SNA";
VAL_ 691 VCRIGHT_filterLifeBlowerTorque 1023 "SNA";
VAL_ 691 VCRIGHT_hvacAirFlowModeRow1 4 "DEFROST" 5 "DEFROST_FLOOR" 6 "DEFROST_PANEL" 7 "DEFROST_PANEL_FLOOR" 1 "FLOOR" 0 "NONE" 2 "PANEL" 3 "PANEL_FLOOR";
VAL_ 691 VCRIGHT_hvacAirFlowModeRow2 4 "DEFROST" 5 "DEFROST_FLOOR" 6 "DEFROST_PANEL" 7 "DEFROST_PANEL_FLOOR" 1 "FLOOR" 0 "NONE" 2 "PANEL" 3 "PANEL_FLOOR";
VAL_ 691 VCRIGHT_hvacAirflowReason 10 "CABIN_OVERHEAT_PROTECT" 9 "CABIN_PURGE" 3 "CABIN_TEMPERATURE_CONTROL" 8 "COLD_DUCT_LOCKOUT" 12 "EVAP_DRYING" 13 "EVAP_OIL_PURGE" 0 "HVAC_OFF" 1 "MANUAL_FAN_SPEED" 4 "MINIMUM_AUTO_AIRFLOW" 14 "NONE" 7 "OCCUPANT_CONVECTION_REQUIREMENT" 11 "SCREEN_PROTECTION" 5 "STRATIFICATION_GLASS_ROOF" 6 "STRATIFICATION_INTERIOR_SURFACES" 2 "UI_SHORTCUT";
VAL_ 691 VCRIGHT_hvacAutoTransitionReason 10 "BI_LEVEL_LANDING" 14 "CABIN_PURGE" 11 "DEFOG_OVERRIDE" 9 "DUCTS_COLD" 18 "DUCT_TARGETS_INVALID" 19 "END" 15 "EVAP_DRYING" 16 "EVAP_OIL_PURGE" 6 "EXCESS_OCCUPANT_CONVECTION" 1 "HUMIDITY_HIGH" 3 "HUMIDITY_LOW" 2 "HUMIDITY_MODERATE" 17 "HVAC_OFF" 0 "NONE" 7 "OCCUPANT_CONVECTION_REQUIREMENT" 13 "SET_TEMP_HI" 12 "SET_TEMP_LO" 5 "TEMP_TARGET_ABOVE_THRESHOLD" 4 "TEMP_TARGET_BELOW_THRESHOLD" 8 "TEMP_TARGET_LOW";
VAL_ 691 VCRIGHT_solarLoadLeftOccupant 127 "SNA";
VAL_ 691 VCRIGHT_solarLoadOnVehFiltered 255 "SNA";
VAL_ 691 VCRIGHT_solarLoadOnVehicle 255 "SNA";
VAL_ 691 VCRIGHT_solarLoadRightOccupant 127 "SNA";
VAL_ 691 VCRIGHT_tempDuctModeledLeft 511 "SNA";
VAL_ 691 VCRIGHT_tempDuctModeledRight 511 "SNA";
VAL_ 691 VCRIGHT_tempHtrSurfaceModeledL 511 "SNA";
VAL_ 691 VCRIGHT_tempHtrSurfaceModeledR 511 "SNA";
VAL_ 691 VCRIGHT_tempIncarCabinDeep 255 "SNA";
VAL_ 691 VCRIGHT_tempIncarCabinMid 250 "SNA";
VAL_ 691 VCRIGHT_tempIncarCabinProbe 255 "SNA";
VAL_ 705 VCFRONT_logging10HzIndex 4 "ACTIVE_LOUVER" 3 "COMPRESSOR_REFRIGERANT" 0 "COOLANT_PUMPS" 2 "COOLANT_VALVE" 7 "END" 5 "HP_SUBCOOL_CONTROLLER" 6 "MISCELLANEOUS" 1 "THERMAL_FAN";
VAL_ 705 VCFRONT_activeLouverMotorState 5 "BRAKE" 7 "DRIVER_FAULT" 3 "I2C_ERROR" 2 "INIT_EEPROM" 1 "INIT_I2C" 4 "READY" 6 "STALL" 0 "UNPOWERED";
VAL_ 705 VCFRONT_activeLouverState 2 "CALIB_CLOSE" 3 "CALIB_OPEN" 6 "FAILSAFE_CLOSE" 8 "FAILSAFE_LOCKED" 7 "FAILSAFE_OPEN" 5 "FAULTED" 0 "NOT_READY" 4 "READY" 1 "UNCALIBRATED";
VAL_ 705 VCFRONT_coolantTempBasedMode 3 "AMBIENT_SOURCE" 2 "BLEND" 1 "PARALLEL" 0 "SERIES";
VAL_ 705 VCFRONT_coolantValveAngleActual 2047 "SNA";
VAL_ 705 VCFRONT_coolantValveAngleTarget 1023 "SNA";
VAL_ 705 VCFRONT_coolantValveDuty 127 "SNA";
VAL_ 705 VCFRONT_coolantValveState 1 "CALIBRATING" 3 "FAULT" 2 "READY" 0 "UNPOWERED";
VAL_ 705 VCFRONT_exvMotorState 4 "COMM_ERROR" 10 "DRIVER_FAULT" 5 "ENABLE_MOTOR" 9 "FAULT_OPEN_COIL" 8 "FAULT_SHORT_COIL" 3 "INIT_COMM" 6 "READY" 2 "RESET" 7 "STALL" 0 "UNKNOWN" 1 "UNPOWERED";
VAL_ 705 VCFRONT_pumpBatteryRPMTarget 1023 "SNA";
VAL_ 705 VCFRONT_pumpPowertrainRPMTarget 1023 "SNA";
VAL_ 705 VCFRONT_radarHeaterDuty 127 "SNA";
VAL_ 705 VCFRONT_radiatorFanRPMTarget 1023 "SNA";
VAL_ 705 VCFRONT_subcoolProtectionType 0 "SUBCOOL_PROT_NONE" 4 "SUBCOOL_PROT_OVERSHOOT" 2 "SUBCOOL_PROT_PD" 3 "SUBCOOL_PROT_SUPERHEAT" 1 "SUBCOOL_PROT_TD";
VAL_ 705 VCFRONT_tempDischargeSimulated 2047 "SNA";
VAL_ 737 VCFRONT_statusIndex 0 "VCF_STS_IDX_BODY_CONTROLS" 2 "VCF_STS_IDX_HOMELINK" 6 "VCF_STS_IDX_INVALID" 4 "VCF_STS_IDX_LV_BATTERY" 3 "VCF_STS_IDX_REFRIGERANT_SYSTEM" 5 "VCF_STS_IDX_SYSTEM_HEALTH" 1 "VCF_STS_IDX_VEHICLE_STATE";
VAL_ 737 VCFRONT_AS8510Voltage 4095 "SNA";
VAL_ 737 VCFRONT_airCompressorStatus 4 "VCFRONT_AIR_COMPRESSOR_STATUS_FAULT" 0 "VCFRONT_AIR_COMPRESSOR_STATUS_OFF" 1 "VCFRONT_AIR_COMPRESSOR_STATUS_ON" 5 "VCFRONT_AIR_COMPRESSOR_STATUS_RETRY_AVAILABLE" 7 "VCFRONT_AIR_COMPRESSOR_STATUS_SNA" 2 "VCFRONT_AIR_COMPRESSOR_STATUS_TURNING_OFF" 3 "VCFRONT_AIR_COMPRESSOR_STATUS_TURNING_ON";
VAL_ 737 VCFRONT_batterySMState 1 "BATTERY_SM_STATE_CHARGE" 2 "BATTERY_SM_STATE_DISCHARGE" 6 "BATTERY_SM_STATE_DISCONNECTED_BATTERY_TEST" 8 "BATTERY_SM_STATE_FAULT" 0 "BATTERY_SM_STATE_INIT" 5 "BATTERY_SM_STATE_OTA_STANDBY" 4 "BATTERY_SM_STATE_RESISTANCE_ESTIMATION" 7 "BATTERY_SM_STATE_SHORTED_CELL_TEST" 3 "BATTERY_SM_STATE_STANDBY";
VAL_ 737 VCFRONT_coolantFillRoutineStatus 3 "FAULTED" 1 "MOVING_TO_FILL_POSITION" 0 "NOT_READY" 2 "READY_TO_FILL";
VAL_ 737 VCFRONT_crashDetectedType 1 "CRASH_DETECTED_TYPE_MINOR_1" 2 "CRASH_DETECTED_TYPE_MINOR_2" 0 "CRASH_DETECTED_TYPE_NONE" 3 "CRASH_DETECTED_TYPE_SEVERE";
VAL_ 737 VCFRONT_crashState 0 "CRASH_STATE_IDLE" 1 "CRASH_STATE_MINOR_1" 2 "CRASH_STATE_MINOR_2" 3 "CRASH_STATE_SEVERE";
VAL_ 737 VCFRONT_frunkLatchStatus 5 "LATCH_AJAR" 2 "LATCH_CLOSED" 3 "LATCH_CLOSING" 7 "LATCH_DEFAULT" 8 "LATCH_FAULT" 1 "LATCH_OPENED" 4 "LATCH_OPENING" 0 "LATCH_SNA" 6 "LATCH_TIMEOUT";
VAL_ 737 VCFRONT_frunkLatchType 1 "FRUNK_LATCH_TYPE_DOUBLE_ACTUATOR" 2 "FRUNK_LATCH_TYPE_DOUBLE_PULL" 0 "FRUNK_LATCH_TYPE_UNKNOWN";
VAL_ 737 VCFRONT_homelinkCommStatus 3 "HOMELINK_COMM_STATUS_FAULT" 1 "HOMELINK_COMM_STATUS_OFF" 2 "HOMELINK_COMM_STATUS_ON" 0 "HOMELINK_COMM_STATUS_SNA";
VAL_ 737 VCFRONT_hvacPerfTestCommand 2 "BLOW" 1 "INIT" 0 "NOT_STARTED" 3 "STOP";
VAL_ 737 VCFRONT_iBoosterStateDBG 4 "IBOOSTER_FORCE_OFF" 2 "IBOOSTER_GOING_DOWN" 0 "IBOOSTER_OFF" 1 "IBOOSTER_ON" 3 "IBOOSTER_WRITING_DATA_SHUTDOWN";
VAL_ 737 VCFRONT_pressureRefrigDischarge 255 "SNA";
VAL_ 737 VCFRONT_pressureRefrigSuction 127 "SNA";
VAL_ 737 VCFRONT_radarHeaterState 4 "HEATER_STATE_FAULT" 2 "HEATER_STATE_OFF" 3 "HEATER_STATE_OFF_UNAVAILABLE" 1 "HEATER_STATE_ON" 0 "HEATER_STATE_SNA";
VAL_ 737 VCFRONT_refrigFillRoutineStatus 3 "FAULTED" 1 "MOVING_TO_FILL_POSITION" 0 "NOT_READY" 2 "READY_TO_FILL";
VAL_ 737 VCFRONT_vbatMonitorVoltage 4095 "SNA";
VAL_ 737 VCFRONT_vehicleStatusDBG 10 "VEHICLE_STATUS_ACCESSORY" 11 "VEHICLE_STATUS_ACCESSORY_PLUS" 3 "VEHICLE_STATUS_BATTERY_POST_WAKE" 12 "VEHICLE_STATUS_CONDITIONING" 14 "VEHICLE_STATUS_CRASH" 13 "VEHICLE_STATUS_DRIVE" 9 "VEHICLE_STATUS_HV_UP_STANDBY" 0 "VEHICLE_STATUS_INIT" 1 "VEHICLE_STATUS_LOW_POWER_STANDBY" 8 "VEHICLE_STATUS_LV_AWAKE" 7 "VEHICLE_STATUS_LV_SHUTDOWN" 15 "VEHICLE_STATUS_OTA" 17 "VEHICLE_STATUS_RESET" 2 "VEHICLE_STATUS_SILENT_WAKE" 5 "VEHICLE_STATUS_SLEEP_SHUTDOWN" 6 "VEHICLE_STATUS_SLEEP_STANDBY" 4 "VEHICLE_STATUS_SYSTEM_CHECKS" 16 "VEHICLE_STATUS_TURN_ON_RAILS";
VAL_ 737 VCFRONT_voltageProfile 3 "VOLTAGE_PROFILE_ALWAYS_CLOSED_CONTACTORS" 0 "VOLTAGE_PROFILE_CHARGE" 1 "VOLTAGE_PROFILE_FLOAT" 2 "VOLTAGE_PROFILE_REDUCED_FLOAT";
VAL_ 737 VCFRONT_wiperPosition 3 "WIPER_POSITION_DELAYED_REST" 2 "WIPER_POSITION_DEPRESSED_PARK" 1 "WIPER_POSITION_SERVICE" 0 "WIPER_POSITION_SNA" 4 "WIPER_POSITION_WIPING";
VAL_ 737 VCFRONT_wiperSpeed 2 "WIPER_SPEED_1" 3 "WIPER_SPEED_2" 4 "WIPER_SPEED_3" 5 "WIPER_SPEED_4" 6 "WIPER_SPEED_5" 8 "WIPER_SPEED_HIGH" 7 "WIPER_SPEED_LOW" 1 "WIPER_SPEED_OFF" 0 "WIPER_SPEED_SNA";
VAL_ 737 VCFRONT_wiperState 9 "WIPER_STATE_CONT_FAST" 10 "WIPER_STATE_CONT_SLOW" 3 "WIPER_STATE_DELAYED_REST" 2 "WIPER_STATE_FAULT" 7 "WIPER_STATE_INTERMITTENT_HIGH" 8 "WIPER_STATE_INTERMITTENT_LOW" 12 "WIPER_STATE_INT_AUTO_HIGH" 11 "WIPER_STATE_INT_AUTO_LOW" 6 "WIPER_STATE_MOMENTARY_WIPE" 4 "WIPER_STATE_PARK" 1 "WIPER_STATE_SERVICE" 0 "WIPER_STATE_SNA" 5 "WIPER_STATE_WASH";
VAL_ 897 VCFRONT_logging1HzIndex 18 "BODY_CONTROL" 0 "COOLANT" 2 "COOLANT_VALVE" 19 "END" 1 "FAN_DEMAND_CONDENSER_AND_FET_TEMPS" 3 "HCML_LED_TEMPS" 4 "HCMR_LED_TEMPS" 6 "HEADLAMP_AIM" 5 "HOMELINK" 15 "HP_ARBITRATION" 9 "HP_CONTROL_LOOP_AND_STATE" 10 "HP_CYCLE_MODEL" 8 "HP_DATA_AND_ACCUMULATORS" 12 "HP_DISSIPATION_AND_POWER" 11 "HP_EXV_CALIBRATION" 7 "HP_EXV_RANGE" 17 "HP_MODE_OPTIONS" 16 "HP_MODE_SELECT_AND_ESTIMATES" 14 "HP_PRESSURE_CONTROL" 13 "HP_TEMPS_AND_DEMANDS";
VAL_ 897 VCFRONT_HCML_bladeTemp 128 "SNA";
VAL_ 897 VCFRONT_HCML_diffuseTemp 128 "SNA";
VAL_ 897 VCFRONT_HCML_highBeamTemp 128 "SNA";
VAL_ 897 VCFRONT_HCML_lowBeamSpotTemp 128 "SNA";
VAL_ 897 VCFRONT_HCML_turnTemp 128 "SNA";
VAL_ 897 VCFRONT_HCMR_bladeTemp 128 "SNA";
VAL_ 897 VCFRONT_HCMR_diffuseTemp 128 "SNA";
VAL_ 897 VCFRONT_HCMR_highBeamTemp 128 "SNA";
VAL_ 897 VCFRONT_HCMR_lowBeamSpotTemp 128 "SNA";
VAL_ 897 VCFRONT_HCMR_turnTemp 128 "SNA";
VAL_ 897 VCFRONT_coolantValveCountRange 1023 "SNA";
VAL_ 897 VCFRONT_coolantValveRadBypass 127 "SNA";
VAL_ 897 VCFRONT_coolantValveRecalReason 3 "CALIBRATION_FAULT_NO_TRAVEL" 2 "GENERAL_FAULT" 1 "MAX_TRAVEL" 5 "MOTOR_FEEDBACK_INTERRUPTED" 6 "POWER_LOSS" 4 "SELF_TEST" 0 "UNDEFINED";
VAL_ 897 VCFRONT_homelinkRegionCode 5 "HOMELINK_REGION_CODE_AMERICAS" 9 "HOMELINK_REGION_CODE_CHINA" 1 "HOMELINK_REGION_CODE_EUROPE" 8 "HOMELINK_REGION_CODE_REST_OF_WORLD" 0 "HOMELINK_REGION_CODE_UNKNOWN";
VAL_ 897 VCFRONT_hpMode 2 "AMBIENT_SOURCE" 15 "BATTERY_COOL" 17 "BATTERY_COOL_CABIN_CONDENSER" 16 "BATTERY_COOL_CABIN_CONDENSER_REHEAT" 18 "BATTERY_COOL_CABIN_REHEAT" 19 "BATTERY_COOL_EVAPORATOR" 13 "BATTERY_HEAT_AMBIENT_SOURCE" 14 "BATTERY_HEAT_COP1" 11 "CABIN_COOL_EVAPORATOR" 12 "CABIN_COOL_EVAPORATOR_REHEAT" 4 "CABIN_HEAT_AMBIENT_SOURCE" 10 "CABIN_HEAT_BATTERY_COOL_REHEAT" 9 "CABIN_HEAT_BATTERY_HEAT_REHEAT_AMBIENT_SOURCE" 7 "CABIN_HEAT_BLEND" 8 "CABIN_HEAT_COP1" 6 "CABIN_HEAT_REHEAT_AMBIENT_SOURCE" 5 "CABIN_HEAT_REHEAT_SCAVENGE" 3 "CABIN_HEAT_SCAVENGE_ONLY" 1 "GENERAL" 0 "NONE";
VAL_ 897 VCFRONT_hpRefrigerantPurgeState 2 "COMPLETE" 1 "EVAP_PURGE" 0 "IDLE";
VAL_ 897 VCFRONT_modeDesired 3 "AMBIENT_SOURCE" 2 "BLEND" 1 "PARALLEL" 0 "SERIES";
VAL_ 897 VCFRONT_modeTransitionID 23 "ENTER_AMBIENTSOURCE" 24 "EXIT_AMBIENTSOURCE" 20 "INIT" 21 "OVERRIDE" 6 "PARALLEL_2_drive_batteryWantsHeat" 7 "PARALLEL_3_drive_batteryWantsCool" 8 "PARALLEL_4_drive_batteryNeedsCool" 11 "PARALLEL_5_charge_batteryWantsHeat" 12 "PARALLEL_6_charge_batteryWantsCool" 15 "PARALLEL_7_fastCharge_batteryWantsCool" 16 "PARALLEL_8_fastCharge_batteryWantsHeat" 19 "PARALLEL_9_drive_batteryThermalLimiting" 0 "PARALLEL_F1_noFlowRequest" 32 "PAR_1_drive_battNeedsActiveCooling" 33 "PAR_2_drive_ptNeedsActiveCooling" 34 "PAR_3_drive_chillerPassivelyCoolsBatt" 35 "PAR_4_drive_cannotPassivelyCoolBatt" 36 "PAR_5_drive_battAboveHotStagnationTemp" 37 "PAR_6_FC_battNeedsActiveCooling_evapDisabled" 38 "PAR_7_FC_battNeedsActiveCooling_evapEnabled" 39 "PAR_8_charge_battAbovePassiveTarget" 3 "SERIES_1_drive_batteryWantsCool" 4 "SERIES_2_drive_batteryNeedsHeat" 5 "SERIES_3_drive_batteryWantsHeat" 9 "SERIES_4_charge_batteryNeedsHeat" 10 "SERIES_5_charge_batteryWantsHeat" 13 "SERIES_6_fastCharge_batteryNeedsHeat" 14 "SERIES_7_fastCharge_batteryWantsCool" 17 "SERIES_8_preConditioning_batteryNeedsHeat" 18 "SERIES_9_drive_driveUnitThermalLimiting" 1 "SERIES_F2_faultPumps" 2 "SERIES_F3_faultTempSensors" 25 "SER_1_drive_battBelowHotStagnationTemp" 26 "SER_2_drive_chillerPassivelyCools" 27 "SER_3_drive_radPassivelyCoolsBatt" 28 "SER_4_FC_battHeatingNeeded" 29 "SER_5_FC_battNeedsActiveCooling_evapDisabled" 30 "SER_6_FC_battNeedsActiveCooling_evapEnabled" 31 "SER_7_charge_battBelowPassiveTarget" 22 "UNDEFINED";
VAL_ 897 VCFRONT_passiveCoolingState 3 "CannotCoolBattery" 2 "ChillerAndRadCoolSeriesLoop" 1 "ChillerCoolsParallelBattLoop" 0 "ChillerCoolsSeriesLoop";
VAL_ 897 VCFRONT_pumpBatteryFETTemp 255 "SNA";
VAL_ 897 VCFRONT_pumpPowertrainFETTemp 255 "SNA";
VAL_ 897 VCFRONT_radiatorFanFETTemp 255 "SNA";
VAL_ 897 VCFRONT_radiatorFanRunReason 1 "ACTIVE_MANAGER" 2 "AMBIENT_SNIFF" 5 "COAST_MODE" 4 "HEAT_PUMP" 6 "MIN_ON_GLOBAL" 7 "MIN_ON_NVH" 0 "NONE" 3 "NVH_MASKING" 8 "UDS";
VAL_ 897 VCFRONT_tempRefrigSuction 255 "SNA";
